VERSION "j1939-2025-03-v2.4-light"

NS_ :

BS_:

BU_:

BO_ 2633675518 HVESP7HIST: 19 Vector__XXX
 SG_ Hvesp7StateOfHealth : 0|8@1+ (0.4,0) [0|100] "%" Vector__XXX
 SG_ Hvesp7TotalEnergyThroughput : 24|32@1+ (100,0) [0|421108121500] "Watt-hour" Vector__XXX
 SG_ Hvesp7TotalAccumulatedCharge : 56|32@1+ (100,0) [0|421108121500] "Ah" Vector__XXX
 SG_ Hvesp7TotalLifetimeEnergyInput : 88|32@1+ (1,0) [0|4211081215] "kWh" Vector__XXX
 SG_ Hvesp7TotalLifetimeEnergyOutput : 120|32@1+ (1,0) [0|4211081215] "kWh" Vector__XXX
 SG_ Hvsp7CnttrOpnUndrLdCnt : 8|16@1+ (1,0) [0|64255] "count" Vector__XXX

BO_ 2566567166 EVDCLIM1: 8 Vector__XXX
 SG_ HrdOrEvDChrgngVltgMxmm : 0|16@1+ (0.05,0) [0|3212.75] "V" Vector__XXX
 SG_ HrdOrEvDChrgngCrrntMxmm : 16|16@1+ (0.0625,0) [0|4015.9375] "A" Vector__XXX
 SG_ HrdOrEvDChrgngPwrMxmm : 32|16@1+ (0.05,0) [0|3212.75] "kW" Vector__XXX
 SG_ HrdOrEvRqstdEnrgTrnsfrTp : 48|4@1+ (1,0) [0|15] "" Vector__XXX

BO_ 2566567422 EVSEDCLIM1: 8 Vector__XXX
 SG_ EvseDcChargingVoltageMaximum : 0|16@1+ (0.05,0) [0|3212.75] "V" Vector__XXX
 SG_ EvseDcChargingCurrentMaximum : 16|16@1+ (0.0625,0) [0|4015.9375] "A" Vector__XXX
 SG_ EvseDcChargingPowerMaximum : 32|16@1+ (0.05,0) [0|3212.75] "kW" Vector__XXX
 SG_ EvsSpprtdEnrgTrnsfrTps : 48|4@1+ (1,0) [0|15] "" Vector__XXX

BO_ 2566567678 EVSEDCLIM2: 8 Vector__XXX
 SG_ EvseDcChargingVoltageMinimum : 0|16@1+ (0.05,0) [0|3212.75] "V" Vector__XXX
 SG_ EvseDcChargingCurrentMinimum : 16|16@1+ (0.0625,0) [0|4015.9375] "A" Vector__XXX
 SG_ EvsePeakCurrentRipple : 32|16@1+ (0.0625,0) [0|4015.9375] "A" Vector__XXX
 SG_ EvseCurrentRegulationTolerance : 48|16@1+ (0.0625,0) [0|4015.9375] "A" Vector__XXX

BO_ 2566567934 EVDCTGT: 8 Vector__XXX
 SG_ DcChargingTargetCrc : 0|8@1+ (1,0) [0|250] "count" Vector__XXX
 SG_ DcChargingTargetSequenceCounter : 8|4@1+ (1,0) [0|15] "" Vector__XXX
 SG_ DcTargetChargingVoltage : 16|16@1+ (0.05,0) [0|3212.75] "V" Vector__XXX
 SG_ DcTargetChargingCurrent : 32|16@1+ (0.0625,0) [0|4015.9375] "A" Vector__XXX

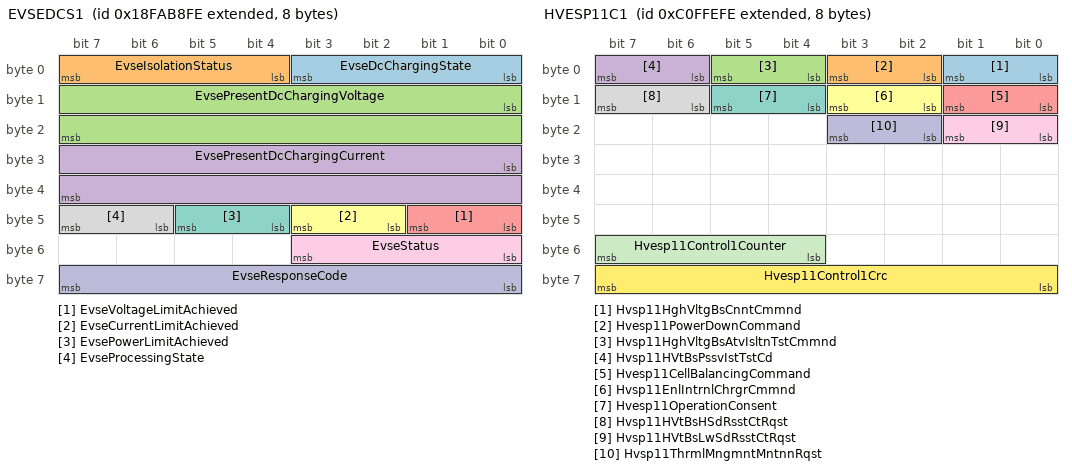
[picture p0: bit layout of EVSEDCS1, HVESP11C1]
BO_ 2566568190 EVSEDCS1: 8 Vector__XXX
 SG_ EvseDcChargingState : 0|4@1+ (1,0) [0|15] "" Vector__XXX
 SG_ EvseIsolationStatus : 4|4@1+ (1,0) [0|15] "" Vector__XXX
 SG_ EvsePresentDcChargingVoltage : 8|16@1+ (0.05,0) [0|3212.75] "V" Vector__XXX
 SG_ EvsePresentDcChargingCurrent : 24|16@1+ (0.05,-1600) [-1600|1612.75] "A" Vector__XXX
 SG_ EvseVoltageLimitAchieved : 40|2@1+ (1,0) [0|3] "" Vector__XXX
 SG_ EvseCurrentLimitAchieved : 42|2@1+ (1,0) [0|3] "" Vector__XXX
 SG_ EvsePowerLimitAchieved : 44|2@1+ (1,0) [0|3] "" Vector__XXX
 SG_ EvseProcessingState : 46|2@1+ (1,0) [0|3] "" Vector__XXX
 SG_ EvseStatus : 48|4@1+ (1,0) [0|15] "" Vector__XXX
 SG_ EvseResponseCode : 56|8@1+ (1,0) [0|250] "" Vector__XXX

BO_ 2566568446 EVSE1CC1: 8 Vector__XXX
 SG_ HrdOrEvDInltCnttr1Cmmnd : 0|2@1+ (1,0) [0|3] "" Vector__XXX

BO_ 2566568702 EVSE1CS1: 8 Vector__XXX
 SG_ HrdOrEvDCnttrInptVltg : 0|16@1+ (0.05,0) [0|3212.75] "V" Vector__XXX
 SG_ HybridOrEvDcChargingBusVoltage : 16|16@1+ (0.05,0) [0|3212.75] "V" Vector__XXX
 SG_ HrdOrEvDInltCnttr1Stt : 32|2@1+ (1,0) [0|3] "" Vector__XXX

BO_ 2566568958 DLCC3: 8 Vector__XXX
 SG_ TrnsmssnOlTmprtrHghLmpCmmnd : 0|2@1+ (1,0) [0|3] "" Vector__XXX
 SG_ TrnsmssnOlPrssrLwLmpCmmnd : 2|2@1+ (1,0) [0|3] "" Vector__XXX

BO_ 2566569214 DLCD3: 8 Vector__XXX
 SG_ TrnsmssnOlTmprtrHghLmpDt : 0|2@1+ (1,0) [0|3] "" Vector__XXX
 SG_ TrnsmssnOlPrssrLwLmpDt : 2|2@1+ (1,0) [0|3] "" Vector__XXX

BO_ 2566569470 MG1LD: 16 Vector__XXX
 SG_ MtrGnrtr1TtlEnrgCnsmd : 0|32@1+ (100,0) [0|421108121500] "Watt-hour" Vector__XXX
 SG_ MtrGnrtr1TtlEnrgGnrtd : 32|32@1+ (100,0) [0|421108121500] "Watt-hour" Vector__XXX
 SG_ MtrGnrtr1TtlChrgCnsmd : 64|32@1+ (100,0) [0|421108121500] "Ah" Vector__XXX
 SG_ MtrGnrtr1TtlChrgGnrtd : 96|32@1+ (100,0) [0|421108121500] "Ah" Vector__XXX

BO_ 2566569726 MG2LD: 16 Vector__XXX
 SG_ MtrGnrtr2TtlEnrgCnsmd : 0|32@1+ (100,0) [0|421108121500] "Watt-hour" Vector__XXX
 SG_ MtrGnrtr2TtlEnrgGnrtd : 32|32@1+ (100,0) [0|421108121500] "Watt-hour" Vector__XXX
 SG_ MtrGnrtr2TtlChrgCnsmd : 64|32@1+ (100,0) [0|421108121500] "Ah" Vector__XXX
 SG_ MtrGnrtr2TtlChrgGnrtd : 96|32@1+ (100,0) [0|421108121500] "Ah" Vector__XXX

BO_ 2566569982 MG3LD: 16 Vector__XXX
 SG_ MtrGnrtr3TtlEnrgCnsmd : 0|32@1+ (100,0) [0|421108121500] "Watt-hour" Vector__XXX
 SG_ MtrGnrtr3TtlEnrgGnrtd : 32|32@1+ (100,0) [0|421108121500] "Watt-hour" Vector__XXX
 SG_ MtrGnrtr3TtlChrgCnsmd : 64|32@1+ (100,0) [0|421108121500] "Ah" Vector__XXX
 SG_ MtrGnrtr3TtlChrgGnrtd : 96|32@1+ (100,0) [0|421108121500] "Ah" Vector__XXX

BO_ 2566570238 MG4LD: 16 Vector__XXX
 SG_ MtrGnrtr4TtlEnrgCnsmd : 0|32@1+ (100,0) [0|421108121500] "Watt-hour" Vector__XXX
 SG_ MtrGnrtr4TtlEnrgGnrtd : 32|32@1+ (100,0) [0|421108121500] "Watt-hour" Vector__XXX
 SG_ MtrGnrtr4TtlChrgCnsmd : 64|32@1+ (100,0) [0|421108121500] "Ah" Vector__XXX
 SG_ MtrGnrtr4TtlChrgGnrtd : 96|32@1+ (100,0) [0|421108121500] "Ah" Vector__XXX

BO_ 2566570494 MG5LD: 16 Vector__XXX
 SG_ MtrGnrtr5TtlEnrgCnsmd : 0|32@1+ (100,0) [0|421108121500] "Watt-hour" Vector__XXX
 SG_ MtrGnrtr5TtlEnrgGnrtd : 32|32@1+ (100,0) [0|421108121500] "Watt-hour" Vector__XXX
 SG_ MtrGnrtr5TtlChrgCnsmd : 64|32@1+ (100,0) [0|421108121500] "Ah" Vector__XXX
 SG_ MtrGnrtr5TtlChrgGnrtd : 96|32@1+ (100,0) [0|421108121500] "Ah" Vector__XXX

BO_ 2566570750 MG6LD: 16 Vector__XXX
 SG_ MtrGnrtr6TtlEnrgCnsmd : 0|32@1+ (100,0) [0|421108121500] "Watt-hour" Vector__XXX
 SG_ MtrGnrtr6TtlEnrgGnrtd : 32|32@1+ (100,0) [0|421108121500] "Watt-hour" Vector__XXX
 SG_ MtrGnrtr6TtlChrgCnsmd : 64|32@1+ (100,0) [0|421108121500] "Ah" Vector__XXX
 SG_ MtrGnrtr6TtlChrgGnrtd : 96|32@1+ (100,0) [0|421108121500] "Ah" Vector__XXX

BO_ 2566571006 AIR3: 8 Vector__XXX
 SG_ AirDryerCartridgeLifeRemaining : 0|8@1+ (0.4,0) [0|100] "%" Vector__XXX
 SG_ AirSuspensionSupplyPressure2 : 8|8@1+ (8,0) [0|2000] "kPa" Vector__XXX

BO_ 2566571262 EVSEACSV: 8 Vector__XXX
 SG_ EvseNominalRmsVoltageLineToLine : 16|16@1+ (0.05,0) [0|3212.75] "V" Vector__XXX
 SG_ EvseNominalSupplyFrequency : 32|8@1+ (1,0) [0|250] "" Vector__XXX
 SG_ EvsNmnlRmsVltgLnTNtrl : 0|16@1+ (0.05,0) [0|3212.75] "V" Vector__XXX

BO_ 2566571518 EVSEAC3PL: 8 Vector__XXX
 SG_ HvessChargerRmsCurrentL1 : 0|16@1+ (0.0625,0) [0|4015.9375] "A" Vector__XXX
 SG_ HvessChargerRmsCurrentL2 : 16|16@1+ (0.0625,0) [0|4015.9375] "A" Vector__XXX
 SG_ HvessChargerRmsCurrentL3 : 32|16@1+ (0.0625,0) [0|4015.9375] "A" Vector__XXX
 SG_ HvessChargerNeutralRmsCurrent : 48|16@1+ (0.0625,0) [0|4015.9375] "A" Vector__XXX

BO_ 2499462910 ERC3: 8 Vector__XXX
 SG_ RtrdrRdSpdDlrtSwth : 0|2@1+ (1,0) [0|3] "" Vector__XXX
 SG_ RtrdrRdSpdAlrtSwth : 2|2@1+ (1,0) [0|3] "" Vector__XXX

BO_ 2566572286 ETC14: 8 Vector__XXX
 SG_ TransmissionClutch1Temperature : 0|16@1+ (0.03125,-273) [-273|1734.96875] "degC" Vector__XXX
 SG_ TrnsmssnClth1OvrhtIndtr : 16|2@1+ (1,0) [0|3] "" Vector__XXX
 SG_ TransmissionLaunchCapability : 18|3@1+ (1,0) [0|7] "" Vector__XXX
 SG_ TransmissionGearShiftCapability : 21|3@1+ (1,0) [0|7] "" Vector__XXX
 SG_ TrnsmssnDmgThrshldStts : 24|3@1+ (1,0) [0|7] "" Vector__XXX

BO_ 2499464702 A1SCREGP2: 8 Vector__XXX
 SG_ Aftrtrtmnt1SrOtltAsltPrssr : 0|16@1+ (0.1,0) [0|6425.5] "kPa" Vector__XXX
 SG_ Aftrtrtmnt1SrOtltPrssr : 16|16@1+ (0.1,0) [0|6425.5] "kPa" Vector__XXX

BO_ 2566573822 PTO2: 8 Vector__XXX
 SG_ TransmissionPtoGearboxStatus : 16|4@1+ (1,0) [0|15] "" Vector__XXX
 SG_ TrnsmssnPtGrxOtptShftSpd : 0|16@1+ (0.125,0) [0|8031.875] "rpm" Vector__XXX

BO_ 2364690686 EATC1: 8 Vector__XXX
 SG_ AxlrTrnsmssnOtptSpd : 0|16@1+ (0.125,0) [0|8031.875] "rpm" Vector__XXX

BO_ 2566563326 DFM3: 8 Vector__XXX
 SG_ BddDFMdEsttdIsttsFSvsRt : 0|16@1+ (0.05,0) [0|3212.75] "l/h" Vector__XXX
 SG_ BlnddDlFlMdOprtngStts : 16|4@1+ (1,0) [0|15] "" Vector__XXX
 SG_ BlendedDualFuelModeStatusReason : 24|8@1+ (1,0) [0|250] "" Vector__XXX

BO_ 2566563582 DFM2: 8 Vector__XXX
 SG_ BlnddDlFlMdTtlDslFlDmnd : 32|32@1+ (0.5,0) [0|2105540607.5] "l" Vector__XXX
 SG_ BlnddDlFlMdTtlDslFlDspldBGssFl : 0|32@1+ (0.5,0) [0|2105540607.5] "l" Vector__XXX

BO_ 2566563838 DFM1: 8 Vector__XXX
 SG_ BlnddDlFlMdTtlDslFlUsd : 0|32@1+ (0.5,0) [0|2105540607.5] "l" Vector__XXX
 SG_ BlnddDlFlMdTtlDslFlPrntDspld : 32|8@1+ (0.5,0) [0|125] "%" Vector__XXX
 SG_ BlnddDlFlMdPrntTmAtv : 40|8@1+ (0.4,0) [0|100] "%" Vector__XXX
 SG_ BlnddDlFlMdDslFlPrntDspld : 48|8@1+ (0.4,0) [0|100] "%" Vector__XXX
 SG_ BddDFMdEsttdIsttsDsSvsRtPt : 56|8@1+ (0.4,0) [0|100] "%" Vector__XXX

BO_ 2566564094 T1HIST: 12 Vector__XXX
 SG_ Trnsmssn1TtlOtptShftRvltns : 32|32@1+ (1000,0) [0|4211081215000] "r" Vector__XXX
 SG_ Trnsmssn1OprtnTmSnRld : 64|32@1+ (1,0) [0|4211081215] "s" Vector__XXX
 SG_ Trnsmssn1TtlHrsOfOprtn : 0|32@1+ (1,0) [0|4211081215] "s" Vector__XXX

BO_ 2566564350 TSTI: 8 Vector__XXX
 SG_ Trnsmssn1InptShftPkTwst : 0|8@1+ (0.1,-12.5) [-12.5|12.5] "deg" Vector__XXX
 SG_ Trnsmssn1OtptShftPkTwst : 8|8@1+ (0.1,-12.5) [-12.5|12.5] "deg" Vector__XXX
 SG_ Trnsmssn1IntrmdtShftPkTwst : 16|8@1+ (0.1,-12.5) [-12.5|12.5] "deg" Vector__XXX

BO_ 2566564606 EATC2: 8 Vector__XXX
 SG_ AxlrTrnsmssnSltdGr : 0|8@1+ (1,-125) [-125|125] "gear value" Vector__XXX
 SG_ AxlrTrnsmssnCrrntGr : 8|8@1+ (1,-125) [-125|125] "gear value" Vector__XXX

BO_ 2349858558 HVESP11C1: 8 Vector__XXX
 SG_ Hvsp11HghVltgBsCnntCmmnd : 0|2@1+ (1,0) [0|3] "" Vector__XXX
 SG_ Hvesp11PowerDownCommand : 2|2@1+ (1,0) [0|3] "" Vector__XXX
 SG_ Hvsp11HghVltgBsAtvIsltnTstCmmnd : 4|2@1+ (1,0) [0|3] "" Vector__XXX
 SG_ Hvsp11HVtBsPssvIstTstCd : 6|2@1+ (1,0) [0|3] "" Vector__XXX
 SG_ Hvesp11CellBalancingCommand : 8|2@1+ (1,0) [0|3] "" Vector__XXX
 SG_ Hvsp11EnlIntrnlChrgrCmmnd : 10|2@1+ (1,0) [0|3] "" Vector__XXX
 SG_ Hvesp11OperationConsent : 12|2@1+ (1,0) [0|3] "" Vector__XXX
 SG_ Hvsp11HVtBsHSdRsstCtRqst : 14|2@1+ (1,0) [0|3] "" Vector__XXX
 SG_ Hvsp11HVtBsLwSdRsstCtRqst : 16|2@1+ (1,0) [0|3] "" Vector__XXX
 SG_ Hvsp11ThrmlMngmntMntnnRqst : 18|2@1+ (1,0) [0|3] "" Vector__XXX
 SG_ Hvesp11Control1Counter : 52|4@1+ (1,0) [0|15] "" Vector__XXX
 SG_ Hvesp11Control1Crc : 56|8@1+ (1,0) [0|250] "count" Vector__XXX

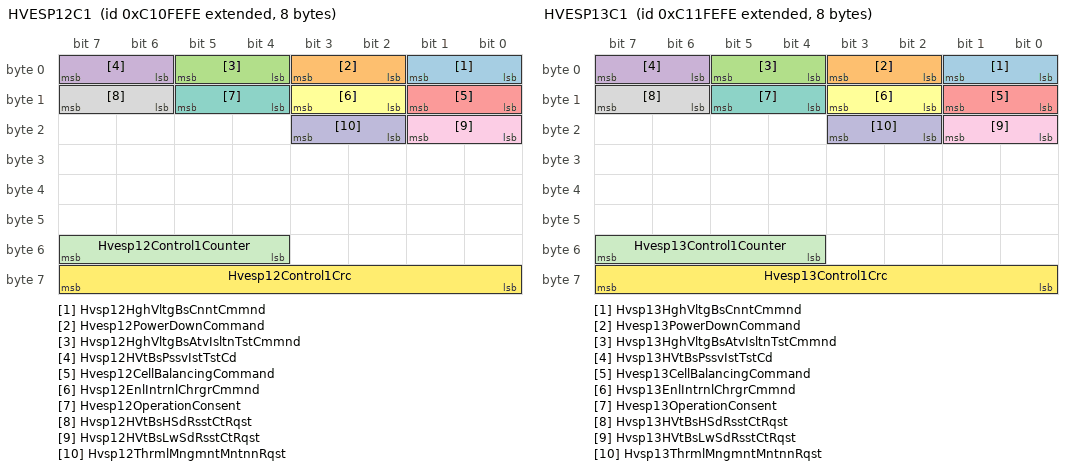
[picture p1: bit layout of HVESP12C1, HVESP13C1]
BO_ 2349924094 HVESP12C1: 8 Vector__XXX
 SG_ Hvsp12HghVltgBsCnntCmmnd : 0|2@1+ (1,0) [0|3] "" Vector__XXX
 SG_ Hvesp12PowerDownCommand : 2|2@1+ (1,0) [0|3] "" Vector__XXX
 SG_ Hvsp12HghVltgBsAtvIsltnTstCmmnd : 4|2@1+ (1,0) [0|3] "" Vector__XXX
 SG_ Hvsp12HVtBsPssvIstTstCd : 6|2@1+ (1,0) [0|3] "" Vector__XXX
 SG_ Hvesp12CellBalancingCommand : 8|2@1+ (1,0) [0|3] "" Vector__XXX
 SG_ Hvsp12EnlIntrnlChrgrCmmnd : 10|2@1+ (1,0) [0|3] "" Vector__XXX
 SG_ Hvesp12OperationConsent : 12|2@1+ (1,0) [0|3] "" Vector__XXX
 SG_ Hvsp12HVtBsHSdRsstCtRqst : 14|2@1+ (1,0) [0|3] "" Vector__XXX
 SG_ Hvsp12HVtBsLwSdRsstCtRqst : 16|2@1+ (1,0) [0|3] "" Vector__XXX
 SG_ Hvsp12ThrmlMngmntMntnnRqst : 18|2@1+ (1,0) [0|3] "" Vector__XXX
 SG_ Hvesp12Control1Counter : 52|4@1+ (1,0) [0|15] "" Vector__XXX
 SG_ Hvesp12Control1Crc : 56|8@1+ (1,0) [0|250] "count" Vector__XXX

BO_ 2349989630 HVESP13C1: 8 Vector__XXX
 SG_ Hvsp13HghVltgBsCnntCmmnd : 0|2@1+ (1,0) [0|3] "" Vector__XXX
 SG_ Hvesp13PowerDownCommand : 2|2@1+ (1,0) [0|3] "" Vector__XXX
 SG_ Hvsp13HghVltgBsAtvIsltnTstCmmnd : 4|2@1+ (1,0) [0|3] "" Vector__XXX
 SG_ Hvsp13HVtBsPssvIstTstCd : 6|2@1+ (1,0) [0|3] "" Vector__XXX
 SG_ Hvesp13CellBalancingCommand : 8|2@1+ (1,0) [0|3] "" Vector__XXX
 SG_ Hvsp13EnlIntrnlChrgrCmmnd : 10|2@1+ (1,0) [0|3] "" Vector__XXX
 SG_ Hvesp13OperationConsent : 12|2@1+ (1,0) [0|3] "" Vector__XXX
 SG_ Hvsp13HVtBsHSdRsstCtRqst : 14|2@1+ (1,0) [0|3] "" Vector__XXX
 SG_ Hvsp13HVtBsLwSdRsstCtRqst : 16|2@1+ (1,0) [0|3] "" Vector__XXX
 SG_ Hvsp13ThrmlMngmntMntnnRqst : 18|2@1+ (1,0) [0|3] "" Vector__XXX
 SG_ Hvesp13Control1Counter : 52|4@1+ (1,0) [0|15] "" Vector__XXX
 SG_ Hvesp13Control1Crc : 56|8@1+ (1,0) [0|250] "count" Vector__XXX

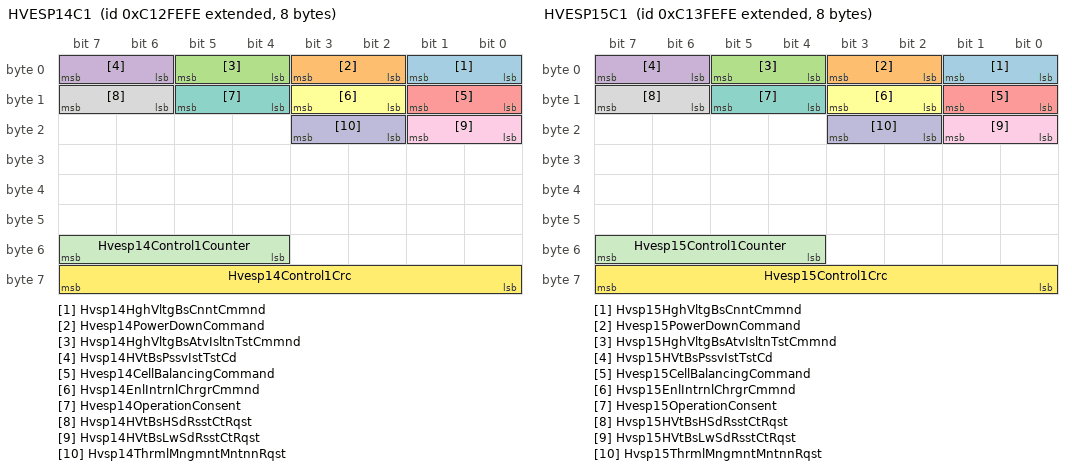
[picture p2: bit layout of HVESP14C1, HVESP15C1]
BO_ 2350055166 HVESP14C1: 8 Vector__XXX
 SG_ Hvsp14HghVltgBsCnntCmmnd : 0|2@1+ (1,0) [0|3] "" Vector__XXX
 SG_ Hvesp14PowerDownCommand : 2|2@1+ (1,0) [0|3] "" Vector__XXX
 SG_ Hvsp14HghVltgBsAtvIsltnTstCmmnd : 4|2@1+ (1,0) [0|3] "" Vector__XXX
 SG_ Hvsp14HVtBsPssvIstTstCd : 6|2@1+ (1,0) [0|3] "" Vector__XXX
 SG_ Hvesp14CellBalancingCommand : 8|2@1+ (1,0) [0|3] "" Vector__XXX
 SG_ Hvsp14EnlIntrnlChrgrCmmnd : 10|2@1+ (1,0) [0|3] "" Vector__XXX
 SG_ Hvesp14OperationConsent : 12|2@1+ (1,0) [0|3] "" Vector__XXX
 SG_ Hvsp14HVtBsHSdRsstCtRqst : 14|2@1+ (1,0) [0|3] "" Vector__XXX
 SG_ Hvsp14HVtBsLwSdRsstCtRqst : 16|2@1+ (1,0) [0|3] "" Vector__XXX
 SG_ Hvsp14ThrmlMngmntMntnnRqst : 18|2@1+ (1,0) [0|3] "" Vector__XXX
 SG_ Hvesp14Control1Counter : 52|4@1+ (1,0) [0|15] "" Vector__XXX
 SG_ Hvesp14Control1Crc : 56|8@1+ (1,0) [0|250] "count" Vector__XXX

BO_ 2350120702 HVESP15C1: 8 Vector__XXX
 SG_ Hvsp15HghVltgBsCnntCmmnd : 0|2@1+ (1,0) [0|3] "" Vector__XXX
 SG_ Hvesp15PowerDownCommand : 2|2@1+ (1,0) [0|3] "" Vector__XXX
 SG_ Hvsp15HghVltgBsAtvIsltnTstCmmnd : 4|2@1+ (1,0) [0|3] "" Vector__XXX
 SG_ Hvsp15HVtBsPssvIstTstCd : 6|2@1+ (1,0) [0|3] "" Vector__XXX
 SG_ Hvesp15CellBalancingCommand : 8|2@1+ (1,0) [0|3] "" Vector__XXX
 SG_ Hvsp15EnlIntrnlChrgrCmmnd : 10|2@1+ (1,0) [0|3] "" Vector__XXX
 SG_ Hvesp15OperationConsent : 12|2@1+ (1,0) [0|3] "" Vector__XXX
 SG_ Hvsp15HVtBsHSdRsstCtRqst : 14|2@1+ (1,0) [0|3] "" Vector__XXX
 SG_ Hvsp15HVtBsLwSdRsstCtRqst : 16|2@1+ (1,0) [0|3] "" Vector__XXX
 SG_ Hvsp15ThrmlMngmntMntnnRqst : 18|2@1+ (1,0) [0|3] "" Vector__XXX
 SG_ Hvesp15Control1Counter : 52|4@1+ (1,0) [0|15] "" Vector__XXX
 SG_ Hvesp15Control1Crc : 56|8@1+ (1,0) [0|250] "count" Vector__XXX

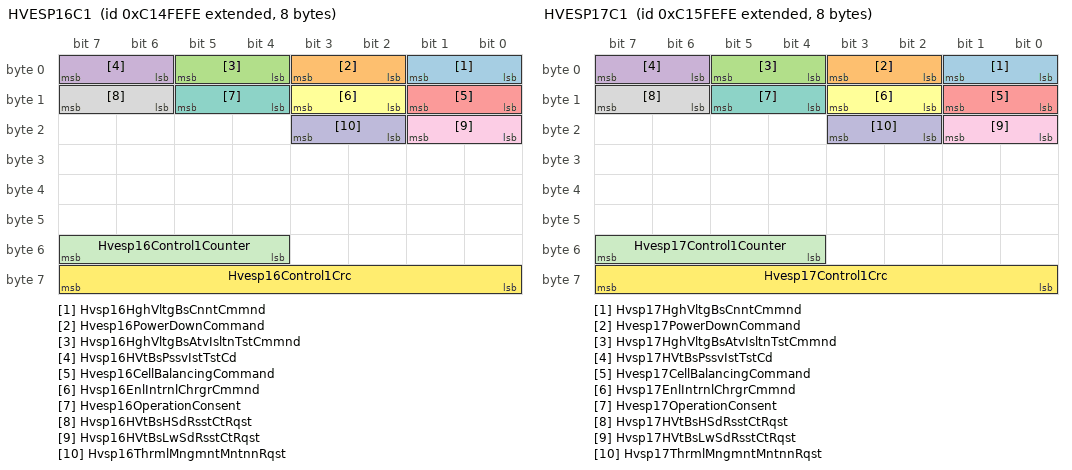
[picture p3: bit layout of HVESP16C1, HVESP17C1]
BO_ 2350186238 HVESP16C1: 8 Vector__XXX
 SG_ Hvsp16HghVltgBsCnntCmmnd : 0|2@1+ (1,0) [0|3] "" Vector__XXX
 SG_ Hvesp16PowerDownCommand : 2|2@1+ (1,0) [0|3] "" Vector__XXX
 SG_ Hvsp16HghVltgBsAtvIsltnTstCmmnd : 4|2@1+ (1,0) [0|3] "" Vector__XXX
 SG_ Hvsp16HVtBsPssvIstTstCd : 6|2@1+ (1,0) [0|3] "" Vector__XXX
 SG_ Hvesp16CellBalancingCommand : 8|2@1+ (1,0) [0|3] "" Vector__XXX
 SG_ Hvsp16EnlIntrnlChrgrCmmnd : 10|2@1+ (1,0) [0|3] "" Vector__XXX
 SG_ Hvesp16OperationConsent : 12|2@1+ (1,0) [0|3] "" Vector__XXX
 SG_ Hvsp16HVtBsHSdRsstCtRqst : 14|2@1+ (1,0) [0|3] "" Vector__XXX
 SG_ Hvsp16HVtBsLwSdRsstCtRqst : 16|2@1+ (1,0) [0|3] "" Vector__XXX
 SG_ Hvsp16ThrmlMngmntMntnnRqst : 18|2@1+ (1,0) [0|3] "" Vector__XXX
 SG_ Hvesp16Control1Counter : 52|4@1+ (1,0) [0|15] "" Vector__XXX
 SG_ Hvesp16Control1Crc : 56|8@1+ (1,0) [0|250] "count" Vector__XXX

BO_ 2350251774 HVESP17C1: 8 Vector__XXX
 SG_ Hvsp17HghVltgBsCnntCmmnd : 0|2@1+ (1,0) [0|3] "" Vector__XXX
 SG_ Hvesp17PowerDownCommand : 2|2@1+ (1,0) [0|3] "" Vector__XXX
 SG_ Hvsp17HghVltgBsAtvIsltnTstCmmnd : 4|2@1+ (1,0) [0|3] "" Vector__XXX
 SG_ Hvsp17HVtBsPssvIstTstCd : 6|2@1+ (1,0) [0|3] "" Vector__XXX
 SG_ Hvesp17CellBalancingCommand : 8|2@1+ (1,0) [0|3] "" Vector__XXX
 SG_ Hvsp17EnlIntrnlChrgrCmmnd : 10|2@1+ (1,0) [0|3] "" Vector__XXX
 SG_ Hvesp17OperationConsent : 12|2@1+ (1,0) [0|3] "" Vector__XXX
 SG_ Hvsp17HVtBsHSdRsstCtRqst : 14|2@1+ (1,0) [0|3] "" Vector__XXX
 SG_ Hvsp17HVtBsLwSdRsstCtRqst : 16|2@1+ (1,0) [0|3] "" Vector__XXX
 SG_ Hvsp17ThrmlMngmntMntnnRqst : 18|2@1+ (1,0) [0|3] "" Vector__XXX
 SG_ Hvesp17Control1Counter : 52|4@1+ (1,0) [0|15] "" Vector__XXX
 SG_ Hvesp17Control1Crc : 56|8@1+ (1,0) [0|250] "count" Vector__XXX

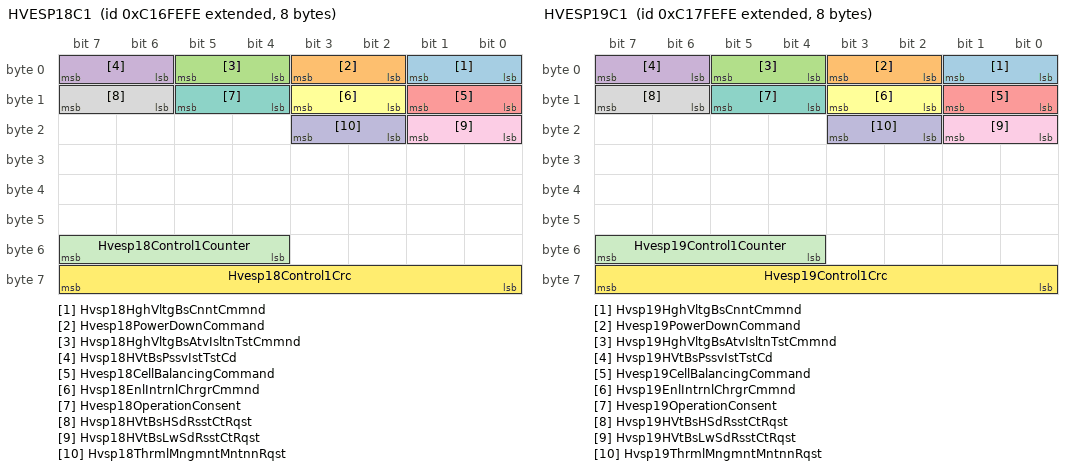
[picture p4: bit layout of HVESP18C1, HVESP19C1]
BO_ 2350317310 HVESP18C1: 8 Vector__XXX
 SG_ Hvsp18HghVltgBsCnntCmmnd : 0|2@1+ (1,0) [0|3] "" Vector__XXX
 SG_ Hvesp18PowerDownCommand : 2|2@1+ (1,0) [0|3] "" Vector__XXX
 SG_ Hvsp18HghVltgBsAtvIsltnTstCmmnd : 4|2@1+ (1,0) [0|3] "" Vector__XXX
 SG_ Hvsp18HVtBsPssvIstTstCd : 6|2@1+ (1,0) [0|3] "" Vector__XXX
 SG_ Hvesp18CellBalancingCommand : 8|2@1+ (1,0) [0|3] "" Vector__XXX
 SG_ Hvsp18EnlIntrnlChrgrCmmnd : 10|2@1+ (1,0) [0|3] "" Vector__XXX
 SG_ Hvesp18OperationConsent : 12|2@1+ (1,0) [0|3] "" Vector__XXX
 SG_ Hvsp18HVtBsHSdRsstCtRqst : 14|2@1+ (1,0) [0|3] "" Vector__XXX
 SG_ Hvsp18HVtBsLwSdRsstCtRqst : 16|2@1+ (1,0) [0|3] "" Vector__XXX
 SG_ Hvsp18ThrmlMngmntMntnnRqst : 18|2@1+ (1,0) [0|3] "" Vector__XXX
 SG_ Hvesp18Control1Counter : 52|4@1+ (1,0) [0|15] "" Vector__XXX
 SG_ Hvesp18Control1Crc : 56|8@1+ (1,0) [0|250] "count" Vector__XXX

BO_ 2350382846 HVESP19C1: 8 Vector__XXX
 SG_ Hvsp19HghVltgBsCnntCmmnd : 0|2@1+ (1,0) [0|3] "" Vector__XXX
 SG_ Hvesp19PowerDownCommand : 2|2@1+ (1,0) [0|3] "" Vector__XXX
 SG_ Hvsp19HghVltgBsAtvIsltnTstCmmnd : 4|2@1+ (1,0) [0|3] "" Vector__XXX
 SG_ Hvsp19HVtBsPssvIstTstCd : 6|2@1+ (1,0) [0|3] "" Vector__XXX
 SG_ Hvesp19CellBalancingCommand : 8|2@1+ (1,0) [0|3] "" Vector__XXX
 SG_ Hvsp19EnlIntrnlChrgrCmmnd : 10|2@1+ (1,0) [0|3] "" Vector__XXX
 SG_ Hvesp19OperationConsent : 12|2@1+ (1,0) [0|3] "" Vector__XXX
 SG_ Hvsp19HVtBsHSdRsstCtRqst : 14|2@1+ (1,0) [0|3] "" Vector__XXX
 SG_ Hvsp19HVtBsLwSdRsstCtRqst : 16|2@1+ (1,0) [0|3] "" Vector__XXX
 SG_ Hvsp19ThrmlMngmntMntnnRqst : 18|2@1+ (1,0) [0|3] "" Vector__XXX
 SG_ Hvesp19Control1Counter : 52|4@1+ (1,0) [0|15] "" Vector__XXX
 SG_ Hvesp19Control1Crc : 56|8@1+ (1,0) [0|250] "count" Vector__XXX

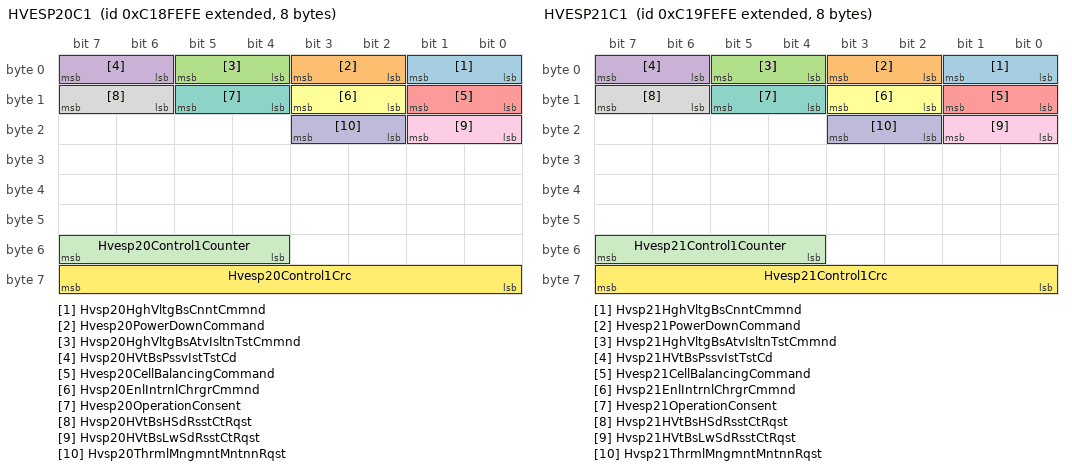
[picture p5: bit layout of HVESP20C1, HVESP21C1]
BO_ 2350448382 HVESP20C1: 8 Vector__XXX
 SG_ Hvsp20HghVltgBsCnntCmmnd : 0|2@1+ (1,0) [0|3] "" Vector__XXX
 SG_ Hvesp20PowerDownCommand : 2|2@1+ (1,0) [0|3] "" Vector__XXX
 SG_ Hvsp20HghVltgBsAtvIsltnTstCmmnd : 4|2@1+ (1,0) [0|3] "" Vector__XXX
 SG_ Hvsp20HVtBsPssvIstTstCd : 6|2@1+ (1,0) [0|3] "" Vector__XXX
 SG_ Hvesp20CellBalancingCommand : 8|2@1+ (1,0) [0|3] "" Vector__XXX
 SG_ Hvsp20EnlIntrnlChrgrCmmnd : 10|2@1+ (1,0) [0|3] "" Vector__XXX
 SG_ Hvesp20OperationConsent : 12|2@1+ (1,0) [0|3] "" Vector__XXX
 SG_ Hvsp20HVtBsHSdRsstCtRqst : 14|2@1+ (1,0) [0|3] "" Vector__XXX
 SG_ Hvsp20HVtBsLwSdRsstCtRqst : 16|2@1+ (1,0) [0|3] "" Vector__XXX
 SG_ Hvsp20ThrmlMngmntMntnnRqst : 18|2@1+ (1,0) [0|3] "" Vector__XXX
 SG_ Hvesp20Control1Counter : 52|4@1+ (1,0) [0|15] "" Vector__XXX
 SG_ Hvesp20Control1Crc : 56|8@1+ (1,0) [0|250] "count" Vector__XXX

BO_ 2350513918 HVESP21C1: 8 Vector__XXX
 SG_ Hvsp21HghVltgBsCnntCmmnd : 0|2@1+ (1,0) [0|3] "" Vector__XXX
 SG_ Hvesp21PowerDownCommand : 2|2@1+ (1,0) [0|3] "" Vector__XXX
 SG_ Hvsp21HghVltgBsAtvIsltnTstCmmnd : 4|2@1+ (1,0) [0|3] "" Vector__XXX
 SG_ Hvsp21HVtBsPssvIstTstCd : 6|2@1+ (1,0) [0|3] "" Vector__XXX
 SG_ Hvesp21CellBalancingCommand : 8|2@1+ (1,0) [0|3] "" Vector__XXX
 SG_ Hvsp21EnlIntrnlChrgrCmmnd : 10|2@1+ (1,0) [0|3] "" Vector__XXX
 SG_ Hvesp21OperationConsent : 12|2@1+ (1,0) [0|3] "" Vector__XXX
 SG_ Hvsp21HVtBsHSdRsstCtRqst : 14|2@1+ (1,0) [0|3] "" Vector__XXX
 SG_ Hvsp21HVtBsLwSdRsstCtRqst : 16|2@1+ (1,0) [0|3] "" Vector__XXX
 SG_ Hvsp21ThrmlMngmntMntnnRqst : 18|2@1+ (1,0) [0|3] "" Vector__XXX
 SG_ Hvesp21Control1Counter : 52|4@1+ (1,0) [0|15] "" Vector__XXX
 SG_ Hvesp21Control1Crc : 56|8@1+ (1,0) [0|250] "count" Vector__XXX

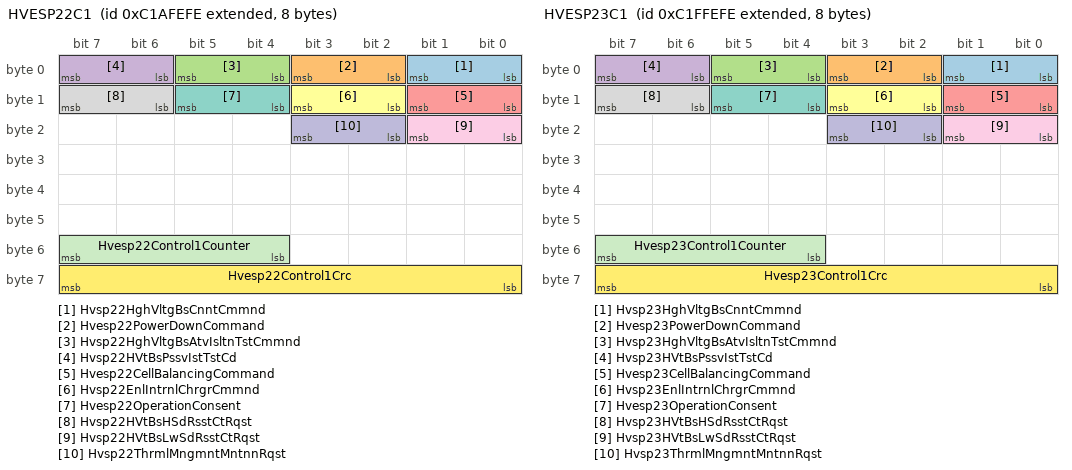
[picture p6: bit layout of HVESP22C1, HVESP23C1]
BO_ 2350579454 HVESP22C1: 8 Vector__XXX
 SG_ Hvsp22HghVltgBsCnntCmmnd : 0|2@1+ (1,0) [0|3] "" Vector__XXX
 SG_ Hvesp22PowerDownCommand : 2|2@1+ (1,0) [0|3] "" Vector__XXX
 SG_ Hvsp22HghVltgBsAtvIsltnTstCmmnd : 4|2@1+ (1,0) [0|3] "" Vector__XXX
 SG_ Hvsp22HVtBsPssvIstTstCd : 6|2@1+ (1,0) [0|3] "" Vector__XXX
 SG_ Hvesp22CellBalancingCommand : 8|2@1+ (1,0) [0|3] "" Vector__XXX
 SG_ Hvsp22EnlIntrnlChrgrCmmnd : 10|2@1+ (1,0) [0|3] "" Vector__XXX
 SG_ Hvesp22OperationConsent : 12|2@1+ (1,0) [0|3] "" Vector__XXX
 SG_ Hvsp22HVtBsHSdRsstCtRqst : 14|2@1+ (1,0) [0|3] "" Vector__XXX
 SG_ Hvsp22HVtBsLwSdRsstCtRqst : 16|2@1+ (1,0) [0|3] "" Vector__XXX
 SG_ Hvsp22ThrmlMngmntMntnnRqst : 18|2@1+ (1,0) [0|3] "" Vector__XXX
 SG_ Hvesp22Control1Counter : 52|4@1+ (1,0) [0|15] "" Vector__XXX
 SG_ Hvesp22Control1Crc : 56|8@1+ (1,0) [0|250] "count" Vector__XXX

BO_ 2350907134 HVESP23C1: 8 Vector__XXX
 SG_ Hvsp23HghVltgBsCnntCmmnd : 0|2@1+ (1,0) [0|3] "" Vector__XXX
 SG_ Hvesp23PowerDownCommand : 2|2@1+ (1,0) [0|3] "" Vector__XXX
 SG_ Hvsp23HghVltgBsAtvIsltnTstCmmnd : 4|2@1+ (1,0) [0|3] "" Vector__XXX
 SG_ Hvsp23HVtBsPssvIstTstCd : 6|2@1+ (1,0) [0|3] "" Vector__XXX
 SG_ Hvesp23CellBalancingCommand : 8|2@1+ (1,0) [0|3] "" Vector__XXX
 SG_ Hvsp23EnlIntrnlChrgrCmmnd : 10|2@1+ (1,0) [0|3] "" Vector__XXX
 SG_ Hvesp23OperationConsent : 12|2@1+ (1,0) [0|3] "" Vector__XXX
 SG_ Hvsp23HVtBsHSdRsstCtRqst : 14|2@1+ (1,0) [0|3] "" Vector__XXX
 SG_ Hvsp23HVtBsLwSdRsstCtRqst : 16|2@1+ (1,0) [0|3] "" Vector__XXX
 SG_ Hvsp23ThrmlMngmntMntnnRqst : 18|2@1+ (1,0) [0|3] "" Vector__XXX
 SG_ Hvesp23Control1Counter : 52|4@1+ (1,0) [0|15] "" Vector__XXX
 SG_ Hvesp23Control1Crc : 56|8@1+ (1,0) [0|250] "count" Vector__XXX

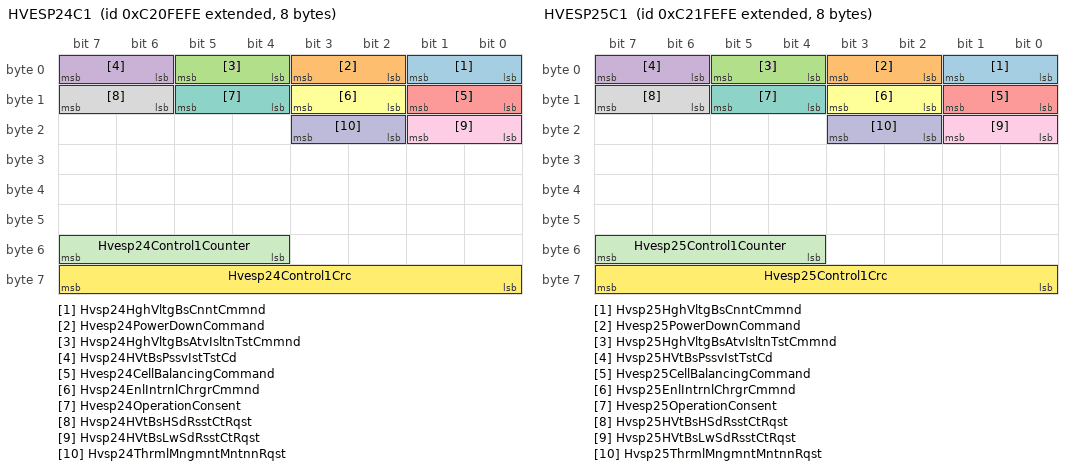
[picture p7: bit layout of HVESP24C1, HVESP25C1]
BO_ 2350972670 HVESP24C1: 8 Vector__XXX
 SG_ Hvsp24HghVltgBsCnntCmmnd : 0|2@1+ (1,0) [0|3] "" Vector__XXX
 SG_ Hvesp24PowerDownCommand : 2|2@1+ (1,0) [0|3] "" Vector__XXX
 SG_ Hvsp24HghVltgBsAtvIsltnTstCmmnd : 4|2@1+ (1,0) [0|3] "" Vector__XXX
 SG_ Hvsp24HVtBsPssvIstTstCd : 6|2@1+ (1,0) [0|3] "" Vector__XXX
 SG_ Hvesp24CellBalancingCommand : 8|2@1+ (1,0) [0|3] "" Vector__XXX
 SG_ Hvsp24EnlIntrnlChrgrCmmnd : 10|2@1+ (1,0) [0|3] "" Vector__XXX
 SG_ Hvesp24OperationConsent : 12|2@1+ (1,0) [0|3] "" Vector__XXX
 SG_ Hvsp24HVtBsHSdRsstCtRqst : 14|2@1+ (1,0) [0|3] "" Vector__XXX
 SG_ Hvsp24HVtBsLwSdRsstCtRqst : 16|2@1+ (1,0) [0|3] "" Vector__XXX
 SG_ Hvsp24ThrmlMngmntMntnnRqst : 18|2@1+ (1,0) [0|3] "" Vector__XXX
 SG_ Hvesp24Control1Counter : 52|4@1+ (1,0) [0|15] "" Vector__XXX
 SG_ Hvesp24Control1Crc : 56|8@1+ (1,0) [0|250] "count" Vector__XXX

BO_ 2351038206 HVESP25C1: 8 Vector__XXX
 SG_ Hvsp25HghVltgBsCnntCmmnd : 0|2@1+ (1,0) [0|3] "" Vector__XXX
 SG_ Hvesp25PowerDownCommand : 2|2@1+ (1,0) [0|3] "" Vector__XXX
 SG_ Hvsp25HghVltgBsAtvIsltnTstCmmnd : 4|2@1+ (1,0) [0|3] "" Vector__XXX
 SG_ Hvsp25HVtBsPssvIstTstCd : 6|2@1+ (1,0) [0|3] "" Vector__XXX
 SG_ Hvesp25CellBalancingCommand : 8|2@1+ (1,0) [0|3] "" Vector__XXX
 SG_ Hvsp25EnlIntrnlChrgrCmmnd : 10|2@1+ (1,0) [0|3] "" Vector__XXX
 SG_ Hvesp25OperationConsent : 12|2@1+ (1,0) [0|3] "" Vector__XXX
 SG_ Hvsp25HVtBsHSdRsstCtRqst : 14|2@1+ (1,0) [0|3] "" Vector__XXX
 SG_ Hvsp25HVtBsLwSdRsstCtRqst : 16|2@1+ (1,0) [0|3] "" Vector__XXX
 SG_ Hvsp25ThrmlMngmntMntnnRqst : 18|2@1+ (1,0) [0|3] "" Vector__XXX
 SG_ Hvesp25Control1Counter : 52|4@1+ (1,0) [0|15] "" Vector__XXX
 SG_ Hvesp25Control1Crc : 56|8@1+ (1,0) [0|250] "count" Vector__XXX

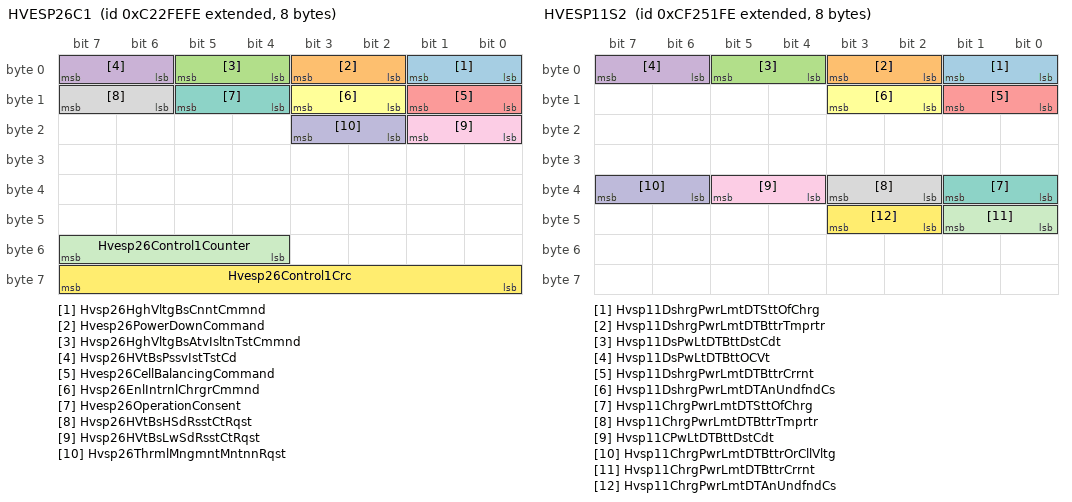
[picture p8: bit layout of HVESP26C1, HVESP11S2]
BO_ 2351103742 HVESP26C1: 8 Vector__XXX
 SG_ Hvsp26HghVltgBsCnntCmmnd : 0|2@1+ (1,0) [0|3] "" Vector__XXX
 SG_ Hvesp26PowerDownCommand : 2|2@1+ (1,0) [0|3] "" Vector__XXX
 SG_ Hvsp26HghVltgBsAtvIsltnTstCmmnd : 4|2@1+ (1,0) [0|3] "" Vector__XXX
 SG_ Hvsp26HVtBsPssvIstTstCd : 6|2@1+ (1,0) [0|3] "" Vector__XXX
 SG_ Hvesp26CellBalancingCommand : 8|2@1+ (1,0) [0|3] "" Vector__XXX
 SG_ Hvsp26EnlIntrnlChrgrCmmnd : 10|2@1+ (1,0) [0|3] "" Vector__XXX
 SG_ Hvesp26OperationConsent : 12|2@1+ (1,0) [0|3] "" Vector__XXX
 SG_ Hvsp26HVtBsHSdRsstCtRqst : 14|2@1+ (1,0) [0|3] "" Vector__XXX
 SG_ Hvsp26HVtBsLwSdRsstCtRqst : 16|2@1+ (1,0) [0|3] "" Vector__XXX
 SG_ Hvsp26ThrmlMngmntMntnnRqst : 18|2@1+ (1,0) [0|3] "" Vector__XXX
 SG_ Hvesp26Control1Counter : 52|4@1+ (1,0) [0|15] "" Vector__XXX
 SG_ Hvesp26Control1Crc : 56|8@1+ (1,0) [0|250] "count" Vector__XXX

BO_ 2555182846 EAECPC: 8 Vector__XXX
 SG_ EngnClntEltrPmpEnlCmmnd : 0|2@1+ (1,0) [0|3] "" Vector__XXX
 SG_ EngnClntEltrPmpPwrHld : 2|2@1+ (1,0) [0|3] "" Vector__XXX
 SG_ EngnClntEltrPmpDrvSr : 4|2@1+ (1,0) [0|3] "" Vector__XXX
 SG_ EngnClntEltrPmpSpdCmmnd : 8|16@1+ (0.5,0) [0|32127.5] "rpm" Vector__XXX
 SG_ EngnClntEltrPmpPrntSpd : 24|8@1+ (0.5,0) [0|125] "%" Vector__XXX

BO_ 2364567550 PC1IC1: 8 Vector__XXX
 SG_ PowerConverter1ControlCrc : 0|8@1+ (1,0) [0|250] "count" Vector__XXX
 SG_ PowerConverter1ControlCounter : 8|4@1+ (1,0) [0|15] "" Vector__XXX
 SG_ PwrCnvrtr1CntrlLmtsRqstOvrrdMd : 12|4@1+ (1,0) [0|15] "" Vector__XXX
 SG_ PwCvt1CtLtsRqstOvdMx : 16|12@1+ (0.0625,-125) [-125|125.9375] "%" Vector__XXX
 SG_ PwCvt1CtLtsRqstOvdM : 28|12@1+ (0.0625,-125) [-125|125.9375] "%" Vector__XXX
 SG_ PwrCnvrtr1CntrlStpntMdRqst : 43|5@1+ (1,0) [0|31] "" Vector__XXX
 SG_ PwrCnvrtr1CntrlStpntRqst : 48|16@1+ (0.00390625,-125) [-125|125.99609375] "%" Vector__XXX

BO_ 2364567806 PC2IC1: 8 Vector__XXX
 SG_ PowerConverter2ControlCrc : 0|8@1+ (1,0) [0|250] "count" Vector__XXX
 SG_ PowerConverter2ControlCounter : 8|4@1+ (1,0) [0|15] "" Vector__XXX
 SG_ PwrCnvrtr2CntrlLmtsRqstOvrrdMd : 12|4@1+ (1,0) [0|15] "" Vector__XXX
 SG_ PwCvt2CtLtsRqstOvdMx : 16|12@1+ (0.0625,-125) [-125|125.9375] "%" Vector__XXX
 SG_ PwCvt2CtLtsRqstOvdM : 28|12@1+ (0.0625,-125) [-125|125.9375] "%" Vector__XXX
 SG_ PwrCnvrtr2CntrlStpntMdRqst : 43|5@1+ (1,0) [0|31] "" Vector__XXX
 SG_ PwrCnvrtr2CntrlStpntRqst : 48|16@1+ (0.00390625,-125) [-125|125.99609375] "%" Vector__XXX

BO_ 2565894654 PC1IRLR1: 8 Vector__XXX
 SG_ PwrCnvrtr1RtLmtsRqst1Cr : 0|8@1+ (1,0) [0|250] "count" Vector__XXX
 SG_ PwrCnvrtr1RtLmtsRqst1Cntr : 8|4@1+ (1,0) [0|15] "" Vector__XXX
 SG_ PwCvt1RtLtsRqstAstFqRtLt : 12|12@1+ (0.25,0) [0|1003.75] "%/s" Vector__XXX
 SG_ PwCvt1RtLtsRqstAstCtRtLt : 24|12@1+ (2,0) [0|8030] "%/s" Vector__XXX

BO_ 2565894910 PC2IRLR1: 8 Vector__XXX
 SG_ PwrCnvrtr2RtLmtsRqst1Cr : 0|8@1+ (1,0) [0|250] "count" Vector__XXX
 SG_ PwrCnvrtr2RtLmtsRqst1Cntr : 8|4@1+ (1,0) [0|15] "" Vector__XXX
 SG_ PwCvt2RtLtsRqstAstFqRtLt : 12|12@1+ (0.25,0) [0|1003.75] "%/s" Vector__XXX
 SG_ PwCvt2RtLtsRqstAstCtRtLt : 24|12@1+ (2,0) [0|8030] "%/s" Vector__XXX

BO_ 2364568574 PC2IC2: 8 Vector__XXX
 SG_ PowerConverter2Control2Crc : 0|8@1+ (1,0) [0|250] "count" Vector__XXX
 SG_ PowerConverter2Control2Counter : 8|4@1+ (1,0) [0|15] "" Vector__XXX
 SG_ PwrCnvrtr2PdCntrlAppllMd : 12|4@1+ (1,0) [0|15] "" Vector__XXX
 SG_ PwCvt2PdCtNzdDtG : 16|8@1+ (0.03125,0) [0|7.8125] "%/(%/s)" Vector__XXX
 SG_ PwrCnvrtr2PdCntrlNrmlzdIntgrlGn : 24|16@1+ (0.015625,0) [0|1003.984375] "%/(%/s)" Vector__XXX
 SG_ PwCvt2PdCtNzdPptG : 40|12@1+ (0.0625,0) [0|250.9375] "%/%" Vector__XXX

BO_ 2364568830 PC1IC2: 8 Vector__XXX
 SG_ PowerConverter1Control2Crc : 0|8@1+ (1,0) [0|250] "count" Vector__XXX
 SG_ PowerConverter1Control2Counter : 8|4@1+ (1,0) [0|15] "" Vector__XXX
 SG_ PwrCnvrtr1PdCntrlAppllMd : 12|4@1+ (1,0) [0|15] "" Vector__XXX
 SG_ PwCvt1PdCtNzdDtG : 16|8@1+ (0.03125,0) [0|7.8125] "%/(%/s)" Vector__XXX
 SG_ PwrCnvrtr1PdCntrlNrmlzdIntgrlGn : 24|16@1+ (0.015625,0) [0|1003.984375] "%/(%/s)" Vector__XXX
 SG_ PwCvt1PdCtNzdPptG : 40|12@1+ (0.0625,0) [0|250.9375] "%/%" Vector__XXX

BO_ 2364569086 PC1IMF1: 8 Vector__XXX
 SG_ PowerConverter1ModeFeedback1Crc : 0|8@1+ (1,0) [0|250] "count" Vector__XXX
 SG_ PwrCnvrtr1MdFdk1Cntr : 8|4@1+ (1,0) [0|15] "" Vector__XXX
 SG_ PwrCnvrtr1CntrlLmtsOvrrdMd : 12|4@1+ (1,0) [0|15] "" Vector__XXX
 SG_ PwrCnvrtr1CntrlStpntMd : 16|5@1+ (1,0) [0|31] "" Vector__XXX
 SG_ PowerConverter1HvilStatus : 21|2@1+ (1,0) [0|3] "" Vector__XXX

BO_ 2565895934 PC1ILAP: 8 Vector__XXX
 SG_ PwrCnvrtr1LmtsAtvPwrCr : 0|8@1+ (1,0) [0|250] "count" Vector__XXX
 SG_ PwrCnvrtr1LmtsAtvPwrCntr : 8|4@1+ (1,0) [0|15] "" Vector__XXX
 SG_ PwrCnvrtr1LmtsAtvEltrlPwrMxmm : 12|12@1+ (0.0625,-125) [-125|125.9375] "%" Vector__XXX
 SG_ PwrCnvrtr1LmtsAtvEltrlPwrMnmm : 24|12@1+ (0.0625,-125) [-125|125.9375] "%" Vector__XXX
 SG_ PwCvt1LtsAtvDES1PwMx : 36|12@1+ (0.0625,-125) [-125|125.9375] "%" Vector__XXX
 SG_ PwCvt1LtsAtvDES1PwM : 48|12@1+ (0.0625,-125) [-125|125.9375] "%" Vector__XXX

BO_ 2565896190 PC1ILAM: 8 Vector__XXX
 SG_ PwrCnvrtr1LmtsAtvEltrlCr : 0|8@1+ (1,0) [0|250] "count" Vector__XXX
 SG_ PwrCnvrtr1LmtsAtvEltrlCntr : 8|4@1+ (1,0) [0|15] "" Vector__XXX
 SG_ PwrCnvrtr1LmtsAtvCrrntMxmm : 12|12@1+ (0.0625,-125) [-125|125.9375] "%" Vector__XXX
 SG_ PwrCnvrtr1LmtsAtvCrrntMnmm : 24|12@1+ (0.0625,-125) [-125|125.9375] "%" Vector__XXX
 SG_ PwrCnvrtr1LmtsAtvFrqnMxmm : 36|12@1+ (0.0625,-125) [-125|125.9375] "%" Vector__XXX
 SG_ PwrCnvrtr1LmtsAtvFrqnMnmm : 48|12@1+ (0.0625,-125) [-125|125.9375] "%" Vector__XXX

BO_ 2565896446 PC1ILADC: 8 Vector__XXX
 SG_ PwrCnvrtr1LmtsAtvDEnrgSr1Cr : 0|8@1+ (1,0) [0|250] "count" Vector__XXX
 SG_ PwrCnvrtr1LmtsAtvDEnrgSr1Cntr : 8|4@1+ (1,0) [0|15] "" Vector__XXX
 SG_ PwCvt1LtsAtvDES1VtMx : 12|12@1+ (0.0625,-125) [-125|125.9375] "%" Vector__XXX
 SG_ PwCvt1LtsAtvDES1VtM : 24|12@1+ (0.0625,-125) [-125|125.9375] "%" Vector__XXX
 SG_ PwCvt1LtsAtvDES1CtMx : 36|12@1+ (0.0625,-125) [-125|125.9375] "%" Vector__XXX
 SG_ PwCvt1LtsAtvDES1CtM : 48|12@1+ (0.0625,-125) [-125|125.9375] "%" Vector__XXX

BO_ 2565896702 PC1ILV: 8 Vector__XXX
 SG_ PwrCnvrtr1SwthdIgntnVltg : 0|16@1+ (0.05,0) [0|3212.75] "V" Vector__XXX
 SG_ PwrCnvrtr1UnswthdSlVltg : 16|16@1+ (0.05,0) [0|3212.75] "V" Vector__XXX

BO_ 2364570366 PC2IMF1: 8 Vector__XXX
 SG_ PowerConverter2ModeFeedback1Crc : 0|8@1+ (1,0) [0|250] "count" Vector__XXX
 SG_ PwrCnvrtr2MdFdk1Cntr : 8|4@1+ (1,0) [0|15] "" Vector__XXX
 SG_ PwrCnvrtr2CntrlLmtsOvrrdMd : 12|4@1+ (1,0) [0|15] "" Vector__XXX
 SG_ PwrCnvrtr2CntrlStpntMd : 16|5@1+ (1,0) [0|31] "" Vector__XXX
 SG_ PowerConverter2HvilStatus : 21|2@1+ (1,0) [0|3] "" Vector__XXX

BO_ 2565897214 PC2ILAP: 8 Vector__XXX
 SG_ PwrCnvrtr2LmtsAtvPwrCr : 0|8@1+ (1,0) [0|250] "count" Vector__XXX
 SG_ PwrCnvrtr2LmtsAtvPwrCntr : 8|4@1+ (1,0) [0|15] "" Vector__XXX
 SG_ PwrCnvrtr2LmtsAtvEltrlPwrMxmm : 12|12@1+ (0.0625,-125) [-125|125.9375] "%" Vector__XXX
 SG_ PwrCnvrtr2LmtsAtvEltrlPwrMnmm : 24|12@1+ (0.0625,-125) [-125|125.9375] "%" Vector__XXX
 SG_ PwCvt2LtsAtvDES1PwMx : 36|12@1+ (0.0625,-125) [-125|125.9375] "%" Vector__XXX
 SG_ PwCvt2LtsAtvDES1PwM : 48|12@1+ (0.0625,-125) [-125|125.9375] "%" Vector__XXX

BO_ 2565897470 PC2ILAM: 8 Vector__XXX
 SG_ PwrCnvrtr2LmtsAtvEltrlCr : 0|8@1+ (1,0) [0|250] "count" Vector__XXX
 SG_ PwrCnvrtr2LmtsAtvEltrlCntr : 8|4@1+ (1,0) [0|15] "" Vector__XXX
 SG_ PwrCnvrtr2LmtsAtvCrrntMxmm : 12|12@1+ (0.0625,-125) [-125|125.9375] "%" Vector__XXX
 SG_ PwrCnvrtr2LmtsAtvCrrntMnmm : 24|12@1+ (0.0625,-125) [-125|125.9375] "%" Vector__XXX
 SG_ PwrCnvrtr2LmtsAtvFrqnMxmm : 36|12@1+ (0.0625,-125) [-125|125.9375] "%" Vector__XXX
 SG_ PwrCnvrtr2LmtsAtvFrqnMnmm : 48|12@1+ (0.0625,-125) [-125|125.9375] "%" Vector__XXX

BO_ 2565897726 PC2ILADC: 8 Vector__XXX
 SG_ PwrCnvrtr2LmtsAtvDEnrgSr1Cr : 0|8@1+ (1,0) [0|250] "count" Vector__XXX
 SG_ PwrCnvrtr2LmtsAtvDEnrgSr1Cntr : 8|4@1+ (1,0) [0|15] "" Vector__XXX
 SG_ PwCvt2LtsAtvDES1VtMx : 12|12@1+ (0.0625,-125) [-125|125.9375] "%" Vector__XXX
 SG_ PwCvt2LtsAtvDES1VtM : 24|12@1+ (0.0625,-125) [-125|125.9375] "%" Vector__XXX
 SG_ PwCvt2LtsAtvDES1CtMx : 36|12@1+ (0.0625,-125) [-125|125.9375] "%" Vector__XXX
 SG_ PwCvt2LtsAtvDES1CtM : 48|12@1+ (0.0625,-125) [-125|125.9375] "%" Vector__XXX

BO_ 2565897982 PC2ILV: 8 Vector__XXX
 SG_ PwrCnvrtr2SwthdIgntnVltg : 0|16@1+ (0.05,0) [0|3212.75] "V" Vector__XXX
 SG_ PwrCnvrtr2UnswthdSlVltg : 16|16@1+ (0.05,0) [0|3212.75] "V" Vector__XXX

BO_ 2565898238 PC1IS2: 8 Vector__XXX
 SG_ PowerConverter1Status2Crc : 0|8@1+ (1,0) [0|250] "count" Vector__XXX
 SG_ PowerConverter1Status2Counter : 8|4@1+ (1,0) [0|15] "" Vector__XXX
 SG_ PwrCnvrtr1AvllMxmmCrrnt : 12|12@1+ (0.0625,-125) [-125|125.9375] "%" Vector__XXX
 SG_ PwrCnvrtr1AvllMnmmCrrnt : 24|12@1+ (0.0625,-125) [-125|125.9375] "%" Vector__XXX

BO_ 2565898494 PC1IRLA1: 8 Vector__XXX
 SG_ PwrCnvrtr1RtLmtsAtv1Cr : 0|8@1+ (1,0) [0|250] "count" Vector__XXX
 SG_ PwrCnvrtr1RtLmtsAtv1Cntr : 8|4@1+ (1,0) [0|15] "" Vector__XXX
 SG_ PwCvt1RtLtsAtvAstCtRtLt : 24|12@1+ (2,0) [0|8030] "%/s" Vector__XXX

BO_ 2565898750 PC2IS2: 8 Vector__XXX
 SG_ PowerConverter2Status2Crc : 0|8@1+ (1,0) [0|250] "count" Vector__XXX
 SG_ PowerConverter2Status2Counter : 8|4@1+ (1,0) [0|15] "" Vector__XXX
 SG_ PwrCnvrtr2AvllMxmmCrrnt : 12|12@1+ (0.0625,-125) [-125|125.9375] "%" Vector__XXX
 SG_ PwrCnvrtr2AvllMnmmCrrnt : 24|12@1+ (0.0625,-125) [-125|125.9375] "%" Vector__XXX

BO_ 2565899006 PC2IRLA1: 8 Vector__XXX
 SG_ PwrCnvrtr2RtLmtsAtv1Cr : 0|8@1+ (1,0) [0|250] "count" Vector__XXX
 SG_ PwrCnvrtr2RtLmtsAtv1Cntr : 8|4@1+ (1,0) [0|15] "" Vector__XXX
 SG_ PwCvt2RtLtsAtvAstCtRtLt : 24|12@1+ (2,0) [0|8030] "%/s" Vector__XXX

BO_ 2565899262 PC2II: 8 Vector__XXX
 SG_ PwrCnvrtr2IsltnIntgrtCr : 0|8@1+ (1,0) [0|250] "count" Vector__XXX
 SG_ PwrCnvrtr2IsltnIntgrtCntr : 8|4@1+ (1,0) [0|15] "" Vector__XXX
 SG_ PwCvt2DES1NtvTCsssGdVt : 12|12@1+ (0.0625,-125) [-125|125.9375] "%" Vector__XXX
 SG_ PwCvt2HVtBsAtvIstTstStts : 24|4@1+ (1,0) [0|15] "" Vector__XXX
 SG_ PwCvt2HVtBsPssvIstTstStts : 28|4@1+ (1,0) [0|15] "" Vector__XXX
 SG_ PwCvt2HVtBsAtvIstTstRsts : 32|16@1+ (0.1,0) [0|6425.5] "OhmPerV" Vector__XXX
 SG_ PwCvt2HVtBsPssvIstTstRsts : 48|16@1+ (0.1,0) [0|6425.5] "OhmPerV" Vector__XXX

BO_ 2565899518 PC1II: 8 Vector__XXX
 SG_ PwrCnvrtr1IsltnIntgrtCr : 0|8@1+ (1,0) [0|250] "count" Vector__XXX
 SG_ PwrCnvrtr1IsltnIntgrtCntr : 8|4@1+ (1,0) [0|15] "" Vector__XXX
 SG_ PwCvt1DES1NtvTCsssGdVt : 12|12@1+ (0.0625,-125) [-125|125.9375] "%" Vector__XXX
 SG_ PwCvt1HVtBsAtvIstTstStts : 24|4@1+ (1,0) [0|15] "" Vector__XXX
 SG_ PwCvt1HVtBsPssvIstTstStts : 28|4@1+ (1,0) [0|15] "" Vector__XXX
 SG_ PwCvt1HVtBsAtvIstTstRsts : 32|16@1+ (0.1,0) [0|6425.5] "OhmPerV" Vector__XXX
 SG_ PwCvt1HVtBsPssvIstTstRsts : 48|16@1+ (0.1,0) [0|6425.5] "OhmPerV" Vector__XXX

BO_ 2364573182 PC2IS1: 8 Vector__XXX
 SG_ PowerConverter2Status1Crc : 0|8@1+ (1,0) [0|250] "count" Vector__XXX
 SG_ PowerConverter2Status1Counter : 8|4@1+ (1,0) [0|15] "" Vector__XXX
 SG_ PowerConverter2Current : 12|12@1+ (0.0625,-125) [-125|125.9375] "%" Vector__XXX
 SG_ PowerConverter2Frequency : 24|16@1+ (0.00390625,-125) [-125|125.99609375] "%" Vector__XXX
 SG_ PwrCnvrtr2DEnrgSr1Crrnt : 40|12@1+ (0.0625,-125) [-125|125.9375] "%" Vector__XXX
 SG_ PwrCnvrtr2DEnrgSr1Vltg : 52|12@1+ (0.0625,-125) [-125|125.9375] "%" Vector__XXX

BO_ 2364573438 PC1IS1: 8 Vector__XXX
 SG_ PowerConverter1Status1Crc : 0|8@1+ (1,0) [0|250] "count" Vector__XXX
 SG_ PowerConverter1Status1Counter : 8|4@1+ (1,0) [0|15] "" Vector__XXX
 SG_ PowerConverter1Current : 12|12@1+ (0.0625,-125) [-125|125.9375] "%" Vector__XXX
 SG_ PowerConverter1Frequency : 24|16@1+ (0.00390625,-125) [-125|125.99609375] "%" Vector__XXX
 SG_ PwrCnvrtr1DEnrgSr1Crrnt : 40|12@1+ (0.0625,-125) [-125|125.9375] "%" Vector__XXX
 SG_ PwrCnvrtr1DEnrgSr1Vltg : 52|12@1+ (0.0625,-125) [-125|125.9375] "%" Vector__XXX

BO_ 2364690942 HVESP11S2: 8 Vector__XXX
 SG_ Hvsp11DshrgPwrLmtDTSttOfChrg : 0|2@1+ (1,0) [0|3] "" Vector__XXX
 SG_ Hvsp11DshrgPwrLmtDTBttrTmprtr : 2|2@1+ (1,0) [0|3] "" Vector__XXX
 SG_ Hvsp11DsPwLtDTBttDstCdt : 4|2@1+ (1,0) [0|3] "" Vector__XXX
 SG_ Hvsp11DsPwLtDTBttOCVt : 6|2@1+ (1,0) [0|3] "" Vector__XXX
 SG_ Hvsp11DshrgPwrLmtDTBttrCrrnt : 8|2@1+ (1,0) [0|3] "" Vector__XXX
 SG_ Hvsp11DshrgPwrLmtDTAnUndfndCs : 10|2@1+ (1,0) [0|3] "" Vector__XXX
 SG_ Hvsp11ChrgPwrLmtDTSttOfChrg : 32|2@1+ (1,0) [0|3] "" Vector__XXX
 SG_ Hvsp11ChrgPwrLmtDTBttrTmprtr : 34|2@1+ (1,0) [0|3] "" Vector__XXX
 SG_ Hvsp11CPwLtDTBttDstCdt : 36|2@1+ (1,0) [0|3] "" Vector__XXX
 SG_ Hvsp11ChrgPwrLmtDTBttrOrCllVltg : 38|2@1+ (1,0) [0|3] "" Vector__XXX
 SG_ Hvsp11ChrgPwrLmtDTBttrCrrnt : 40|2@1+ (1,0) [0|3] "" Vector__XXX
 SG_ Hvsp11ChrgPwrLmtDTAnUndfndCs : 42|2@1+ (1,0) [0|3] "" Vector__XXX

BO_ 2364691198 HVESP11D1: 8 Vector__XXX
 SG_ Hvesp11AvailableDischargePower : 0|16@1+ (0.05,0) [0|3212.75] "kW" Vector__XXX
 SG_ Hvesp11AvailableChargePower : 16|16@1+ (0.05,0) [0|3212.75] "kW" Vector__XXX
 SG_ Hvesp11VoltageLevel : 32|16@1+ (0.05,0) [0|3212.75] "V" Vector__XXX
 SG_ Hvesp11Current : 48|16@1+ (0.05,-1600) [-1600|1612.75] "A" Vector__XXX

BO_ 2364691454 HVESP11D2: 8 Vector__XXX
 SG_ Hvesp11FastUpdateStateOfCharge : 0|16@1+ (0.0015625,0) [0|100.3984375] "%" Vector__XXX
 SG_ Hvesp11HighestCellVoltage : 16|16@1+ (0.001,0) [0|64.255] "V" Vector__XXX
 SG_ Hvesp11LowestCellVoltage : 32|16@1+ (0.001,0) [0|64.255] "V" Vector__XXX
 SG_ Hvsp11CllVltgDffrntlStts : 48|4@1+ (1,0) [0|15] "" Vector__XXX

BO_ 2364691710 HVESP11D3: 8 Vector__XXX
 SG_ Hvesp11HighestCellTemperature : 0|16@1+ (0.03125,-273) [-273|1734.96875] "degC" Vector__XXX
 SG_ Hvesp11LowestCellTemperature : 16|16@1+ (0.03125,-273) [-273|1734.96875] "degC" Vector__XXX
 SG_ Hvesp11AverageCellTemperature : 32|16@1+ (0.03125,-273) [-273|1734.96875] "degC" Vector__XXX
 SG_ Hvsp11CllTmprtrDffrntlStts : 48|2@1+ (1,0) [0|3] "" Vector__XXX

BO_ 2364691966 HVESP11D4: 8 Vector__XXX
 SG_ Hvesp11DischargeCapacity : 0|16@1+ (0.01,0) [0|642.55] "Ah" Vector__XXX
 SG_ Hvesp11ChargeCapacity : 16|16@1+ (0.01,0) [0|642.55] "Ah" Vector__XXX
 SG_ Hvesp11CellBalancingCount : 32|16@1+ (1,0) [0|64255] "count" Vector__XXX

BO_ 2364692222 HVESP11D5: 8 Vector__XXX
 SG_ Hvesp11LowestCellStateOfCharge : 32|16@1+ (0.0015625,0) [0|100.3984375] "%" Vector__XXX
 SG_ Hvesp11HighestCellStateOfCharge : 48|16@1+ (0.0015625,0) [0|100.3984375] "%" Vector__XXX
 SG_ Hvsp11MxmmInstntnsDshrgCrrntLmt : 0|16@1+ (0.05,-1600) [-1600|0] "A" Vector__XXX
 SG_ Hvsp11MxmmInstntnsChrgCrrntLmt : 16|16@1+ (0.05,-1600) [0|1612.75] "A" Vector__XXX

BO_ 2364692478 HVESP11D6: 8 Vector__XXX
 SG_ Hvesp11BusVoltage : 0|16@1+ (0.05,0) [0|3212.75] "V" Vector__XXX
 SG_ Hvesp11IgnitionVoltage : 16|16@1+ (0.01,0) [0|642.55] "V" Vector__XXX
 SG_ Hvesp11IntakeCoolantTemperature : 32|8@1+ (1,-40) [-40|210] "degC" Vector__XXX
 SG_ Hvesp11OutletCoolantTemperature : 40|8@1+ (1,-40) [-40|210] "degC" Vector__XXX
 SG_ Hvesp11ElectronicsTemperature : 48|8@1+ (1,-40) [-40|210] "degC" Vector__XXX
 SG_ Hvesp11Temperature : 56|8@1+ (1,-40) [-40|210] "degC" Vector__XXX

BO_ 2364692734 HVESP11S1: 8 Vector__XXX
 SG_ Hvsp11HghVltgBsPstvCnttrStt : 0|2@1+ (1,0) [0|3] "" Vector__XXX
 SG_ Hvsp11HghVltgBsNgtvCnttrStt : 2|2@1+ (1,0) [0|3] "" Vector__XXX
 SG_ Hvsp11HghVltgBsDsnntFrwrnng : 4|4@1+ (1,0) [0|15] "" Vector__XXX
 SG_ Hvsp11HghVltgBsPrChrgRlStt : 8|2@1+ (1,0) [0|3] "" Vector__XXX
 SG_ Hvsp11CntrOfPkCnttrStt : 10|2@1+ (1,0) [0|3] "" Vector__XXX
 SG_ Hvsp11HghVltgBsAtvIsltnTstStts : 12|4@1+ (1,0) [0|15] "" Vector__XXX
 SG_ Hvsp11HghVltgBsPssvIsltnTstStts : 16|4@1+ (1,0) [0|15] "" Vector__XXX
 SG_ Hvesp11HvilStatus : 20|2@1+ (1,0) [0|3] "" Vector__XXX
 SG_ Hvesp11InertiaSwitchStatus : 22|2@1+ (1,0) [0|3] "" Vector__XXX
 SG_ Hvesp11StateOfChargeStatus : 24|4@1+ (1,0) [0|15] "" Vector__XXX
 SG_ Hvesp11CellBalanceStatus : 28|2@1+ (1,0) [0|3] "" Vector__XXX
 SG_ Hvesp11CellBalancingActive : 30|2@1+ (1,0) [0|3] "" Vector__XXX
 SG_ Hvesp11InternalChargerStatus : 32|2@1+ (1,0) [0|3] "" Vector__XXX
 SG_ Hvsp11HghVltgBsCnntnStts : 40|4@1+ (1,0) [0|15] "" Vector__XXX
 SG_ Hvesp11OperationalStatus : 44|4@1+ (1,0) [0|15] "" Vector__XXX
 SG_ Hvesp11Status1Counter : 52|4@1+ (1,0) [0|15] "" Vector__XXX
 SG_ Hvesp11Status1Crc : 56|8@1+ (1,0) [0|250] "count" Vector__XXX

BO_ 2364692990 HVESP11D7: 8 Vector__XXX
 SG_ Hvesp11DischargeEnergyCapacity : 0|24@1+ (0.001,0) [0|16449.535] "kWh" Vector__XXX
 SG_ Hvesp11ChargeEnergyCapacity : 24|24@1+ (0.001,0) [0|16449.535] "kWh" Vector__XXX
 SG_ Hvsp11MxmmChrgVltgLmt : 48|16@1+ (0.05,0) [0|3212.75] "V" Vector__XXX

BO_ 2364693246 HVESP11MS1: 8 Vector__XXX
 SG_ Hvesp11Module1OperationalStatus : 0|2@1+ (1,0) [0|3] "" Vector__XXX
 SG_ Hvesp11Module2OperationalStatus : 2|2@1+ (1,0) [0|3] "" Vector__XXX
 SG_ Hvesp11Module3OperationalStatus : 4|2@1+ (1,0) [0|3] "" Vector__XXX
 SG_ Hvesp11Module4OperationalStatus : 6|2@1+ (1,0) [0|3] "" Vector__XXX
 SG_ Hvesp11Module5OperationalStatus : 8|2@1+ (1,0) [0|3] "" Vector__XXX
 SG_ Hvesp11Module6OperationalStatus : 10|2@1+ (1,0) [0|3] "" Vector__XXX
 SG_ Hvesp11Module7OperationalStatus : 12|2@1+ (1,0) [0|3] "" Vector__XXX
 SG_ Hvesp11Module8OperationalStatus : 14|2@1+ (1,0) [0|3] "" Vector__XXX
 SG_ Hvesp11Module9OperationalStatus : 16|2@1+ (1,0) [0|3] "" Vector__XXX
 SG_ Hvsp11Mdl10OprtnlStts : 18|2@1+ (1,0) [0|3] "" Vector__XXX
 SG_ Hvsp11Mdl11OprtnlStts : 20|2@1+ (1,0) [0|3] "" Vector__XXX
 SG_ Hvsp11Mdl12OprtnlStts : 22|2@1+ (1,0) [0|3] "" Vector__XXX
 SG_ Hvsp11Mdl13OprtnlStts : 24|2@1+ (1,0) [0|3] "" Vector__XXX
 SG_ Hvsp11Mdl14OprtnlStts : 26|2@1+ (1,0) [0|3] "" Vector__XXX
 SG_ Hvsp11Mdl15OprtnlStts : 28|2@1+ (1,0) [0|3] "" Vector__XXX
 SG_ Hvsp11Mdl16OprtnlStts : 30|2@1+ (1,0) [0|3] "" Vector__XXX
 SG_ Hvsp11Mdl17OprtnlStts : 32|2@1+ (1,0) [0|3] "" Vector__XXX
 SG_ Hvsp11Mdl18OprtnlStts : 34|2@1+ (1,0) [0|3] "" Vector__XXX
 SG_ Hvsp11Mdl19OprtnlStts : 36|2@1+ (1,0) [0|3] "" Vector__XXX
 SG_ Hvsp11Mdl20OprtnlStts : 38|2@1+ (1,0) [0|3] "" Vector__XXX
 SG_ Hvsp11Mdl21OprtnlStts : 40|2@1+ (1,0) [0|3] "" Vector__XXX
 SG_ Hvsp11Mdl22OprtnlStts : 42|2@1+ (1,0) [0|3] "" Vector__XXX
 SG_ Hvsp11Mdl23OprtnlStts : 44|2@1+ (1,0) [0|3] "" Vector__XXX
 SG_ Hvsp11Mdl24OprtnlStts : 46|2@1+ (1,0) [0|3] "" Vector__XXX
 SG_ Hvsp11Mdl25OprtnlStts : 48|2@1+ (1,0) [0|3] "" Vector__XXX
 SG_ Hvsp11Mdl26OprtnlStts : 50|2@1+ (1,0) [0|3] "" Vector__XXX
 SG_ Hvsp11Mdl27OprtnlStts : 52|2@1+ (1,0) [0|3] "" Vector__XXX
 SG_ Hvsp11Mdl28OprtnlStts : 54|2@1+ (1,0) [0|3] "" Vector__XXX
 SG_ Hvsp11Mdl29OprtnlStts : 56|2@1+ (1,0) [0|3] "" Vector__XXX
 SG_ Hvsp11Mdl30OprtnlStts : 58|2@1+ (1,0) [0|3] "" Vector__XXX
 SG_ Hvsp11Mdl31OprtnlStts : 60|2@1+ (1,0) [0|3] "" Vector__XXX
 SG_ Hvsp11Mdl32OprtnlStts : 62|2@1+ (1,0) [0|3] "" Vector__XXX

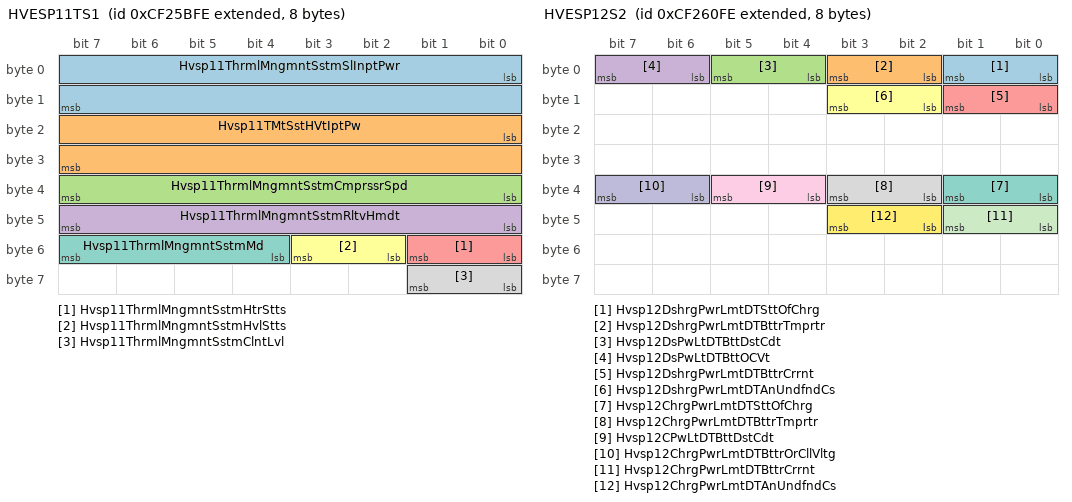
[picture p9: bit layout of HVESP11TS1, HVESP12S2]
BO_ 2364693502 HVESP11TS1: 8 Vector__XXX
 SG_ Hvsp11ThrmlMngmntSstmSlInptPwr : 0|16@1+ (0.5,0) [0|32127.5] "W" Vector__XXX
 SG_ Hvsp11TMtSstHVtIptPw : 16|16@1+ (0.5,0) [0|32127.5] "W" Vector__XXX
 SG_ Hvsp11ThrmlMngmntSstmCmprssrSpd : 32|8@1+ (32,0) [0|8000] "rpm" Vector__XXX
 SG_ Hvsp11ThrmlMngmntSstmRltvHmdt : 40|8@1+ (0.4,0) [0|100] "%" Vector__XXX
 SG_ Hvsp11ThrmlMngmntSstmHtrStts : 48|2@1+ (1,0) [0|3] "" Vector__XXX
 SG_ Hvsp11ThrmlMngmntSstmHvlStts : 50|2@1+ (1,0) [0|3] "" Vector__XXX
 SG_ Hvsp11ThrmlMngmntSstmMd : 52|4@1+ (1,0) [0|15] "" Vector__XXX
 SG_ Hvsp11ThrmlMngmntSstmClntLvl : 56|2@1+ (1,0) [0|3] "" Vector__XXX

BO_ 2364693758 HVESP11D8: 8 Vector__XXX
 SG_ Hvsp11HghstCllVltgMdlNmr : 0|8@1+ (1,0) [0|250] "count" Vector__XXX
 SG_ Hvsp11HghstCllVltgCllNmr : 8|8@1+ (1,0) [0|250] "count" Vector__XXX
 SG_ Hvsp11LwstCllVltgMdlNmr : 16|8@1+ (1,0) [0|250] "count" Vector__XXX
 SG_ Hvsp11LwstCllVltgCllNmr : 24|8@1+ (1,0) [0|250] "count" Vector__XXX
 SG_ Hvesp11AverageCellVoltage : 32|16@1+ (0.001,0) [0|64.255] "V" Vector__XXX

BO_ 2364694014 HVESP11D9: 8 Vector__XXX
 SG_ Hvsp11HghstCllTmprtrMdlNmr : 0|8@1+ (1,0) [0|250] "count" Vector__XXX
 SG_ Hvsp11HghstCllTmprtrCllNmr : 8|8@1+ (1,0) [0|250] "count" Vector__XXX
 SG_ Hvsp11LwstCllTmprtrMdlNmr : 16|8@1+ (1,0) [0|250] "count" Vector__XXX
 SG_ Hvsp11LwstCllTmprtrCllNmr : 24|8@1+ (1,0) [0|250] "count" Vector__XXX
 SG_ Hvess11ThermalEventDetected : 32|2@1+ (1,0) [0|3] "" Vector__XXX
 SG_ Hvsp11Dt9EmdddIntgrtSpprt : 50|2@1+ (1,0) [0|3] "" Vector__XXX
 SG_ Hvesp11Data9Counter : 52|4@1+ (1,0) [0|15] "" Vector__XXX
 SG_ Hvesp11Data9Crc : 56|8@1+ (1,0) [0|250] "count" Vector__XXX

BO_ 2364694270 HVESP11D10: 8 Vector__XXX
 SG_ Hvsp11HghstCllSttOfChrgMdlNmr : 0|8@1+ (1,0) [0|250] "count" Vector__XXX
 SG_ Hvsp11HghstCllSttOfChrgCllNmr : 8|8@1+ (1,0) [0|250] "count" Vector__XXX
 SG_ Hvsp11LwstCllSttOfChrgMdlNmr : 16|8@1+ (1,0) [0|250] "count" Vector__XXX
 SG_ Hvsp11LwstCllSttOfChrgCllNmr : 24|8@1+ (1,0) [0|250] "count" Vector__XXX
 SG_ Hvsp11HghVltgBsAtvIsltnTstRslts : 32|16@1+ (0.1,0) [0|6425.5] "OhmPerV" Vector__XXX
 SG_ Hvsp11HVtBsPssvIstTstRsts : 48|16@1+ (0.1,0) [0|6425.5] "OhmPerV" Vector__XXX

BO_ 2364694526 HVESP11D11: 8 Vector__XXX
 SG_ Hvsp11BsVltgNgtvTChsssGrndVltg : 0|16@1+ (0.05,0) [0|3212.75] "V" Vector__XXX
 SG_ Hvsp11VltgLvlNgtvTChsssGrndVltg : 16|16@1+ (0.05,0) [0|3212.75] "V" Vector__XXX
 SG_ Hvesp11ActualChargeRate : 32|16@1+ (0.05,0) [0|3212.75] "kW" Vector__XXX

BO_ 2364694782 HVESP12S2: 8 Vector__XXX
 SG_ Hvsp12DshrgPwrLmtDTSttOfChrg : 0|2@1+ (1,0) [0|3] "" Vector__XXX
 SG_ Hvsp12DshrgPwrLmtDTBttrTmprtr : 2|2@1+ (1,0) [0|3] "" Vector__XXX
 SG_ Hvsp12DsPwLtDTBttDstCdt : 4|2@1+ (1,0) [0|3] "" Vector__XXX
 SG_ Hvsp12DsPwLtDTBttOCVt : 6|2@1+ (1,0) [0|3] "" Vector__XXX
 SG_ Hvsp12DshrgPwrLmtDTBttrCrrnt : 8|2@1+ (1,0) [0|3] "" Vector__XXX
 SG_ Hvsp12DshrgPwrLmtDTAnUndfndCs : 10|2@1+ (1,0) [0|3] "" Vector__XXX
 SG_ Hvsp12ChrgPwrLmtDTSttOfChrg : 32|2@1+ (1,0) [0|3] "" Vector__XXX
 SG_ Hvsp12ChrgPwrLmtDTBttrTmprtr : 34|2@1+ (1,0) [0|3] "" Vector__XXX
 SG_ Hvsp12CPwLtDTBttDstCdt : 36|2@1+ (1,0) [0|3] "" Vector__XXX
 SG_ Hvsp12ChrgPwrLmtDTBttrOrCllVltg : 38|2@1+ (1,0) [0|3] "" Vector__XXX
 SG_ Hvsp12ChrgPwrLmtDTBttrCrrnt : 40|2@1+ (1,0) [0|3] "" Vector__XXX
 SG_ Hvsp12ChrgPwrLmtDTAnUndfndCs : 42|2@1+ (1,0) [0|3] "" Vector__XXX

BO_ 2364695038 HVESP12D1: 8 Vector__XXX
 SG_ Hvesp12AvailableDischargePower : 0|16@1+ (0.05,0) [0|3212.75] "kW" Vector__XXX
 SG_ Hvesp12AvailableChargePower : 16|16@1+ (0.05,0) [0|3212.75] "kW" Vector__XXX
 SG_ Hvesp12VoltageLevel : 32|16@1+ (0.05,0) [0|3212.75] "V" Vector__XXX
 SG_ Hvesp12Current : 48|16@1+ (0.05,-1600) [-1600|1612.75] "A" Vector__XXX

BO_ 2364695294 HVESP12D2: 8 Vector__XXX
 SG_ Hvesp12FastUpdateStateOfCharge : 0|16@1+ (0.0015625,0) [0|100.3984375] "%" Vector__XXX
 SG_ Hvesp12HighestCellVoltage : 16|16@1+ (0.001,0) [0|64.255] "V" Vector__XXX
 SG_ Hvesp12LowestCellVoltage : 32|16@1+ (0.001,0) [0|64.255] "V" Vector__XXX
 SG_ Hvsp12CllVltgDffrntlStts : 48|4@1+ (1,0) [0|15] "" Vector__XXX

BO_ 2364695550 HVESP12D3: 8 Vector__XXX
 SG_ Hvesp12HighestCellTemperature : 0|16@1+ (0.03125,-273) [-273|1734.96875] "degC" Vector__XXX
 SG_ Hvesp12LowestCellTemperature : 16|16@1+ (0.03125,-273) [-273|1734.96875] "degC" Vector__XXX
 SG_ Hvesp12AverageCellTemperature : 32|16@1+ (0.03125,-273) [-273|1734.96875] "degC" Vector__XXX
 SG_ Hvsp12CllTmprtrDffrntlStts : 48|2@1+ (1,0) [0|3] "" Vector__XXX

BO_ 2364695806 HVESP12D4: 8 Vector__XXX
 SG_ Hvesp12DischargeCapacity : 0|16@1+ (0.01,0) [0|642.55] "Ah" Vector__XXX
 SG_ Hvesp12ChargeCapacity : 16|16@1+ (0.01,0) [0|642.55] "Ah" Vector__XXX
 SG_ Hvesp12CellBalancingCount : 32|16@1+ (1,0) [0|64255] "count" Vector__XXX

BO_ 2364696062 HVESP12D5: 8 Vector__XXX
 SG_ Hvesp12LowestCellStateOfCharge : 32|16@1+ (0.0015625,0) [0|100.3984375] "%" Vector__XXX
 SG_ Hvesp12HighestCellStateOfCharge : 48|16@1+ (0.0015625,0) [0|100.3984375] "%" Vector__XXX
 SG_ Hvsp12MxmmInstntnsDshrgCrrntLmt : 0|16@1+ (0.05,-1600) [-1600|0] "A" Vector__XXX
 SG_ Hvsp12MxmmInstntnsChrgCrrntLmt : 16|16@1+ (0.05,-1600) [0|1612.75] "A" Vector__XXX

BO_ 2364696318 HVESP12D6: 8 Vector__XXX
 SG_ Hvesp12BusVoltage : 0|16@1+ (0.05,0) [0|3212.75] "V" Vector__XXX
 SG_ Hvesp12IgnitionVoltage : 16|16@1+ (0.01,0) [0|642.55] "V" Vector__XXX
 SG_ Hvesp12IntakeCoolantTemperature : 32|8@1+ (1,-40) [-40|210] "degC" Vector__XXX
 SG_ Hvesp12OutletCoolantTemperature : 40|8@1+ (1,-40) [-40|210] "degC" Vector__XXX
 SG_ Hvesp12ElectronicsTemperature : 48|8@1+ (1,-40) [-40|210] "degC" Vector__XXX
 SG_ Hvesp12Temperature : 56|8@1+ (1,-40) [-40|210] "degC" Vector__XXX

BO_ 2364696574 HVESP12S1: 8 Vector__XXX
 SG_ Hvsp12HghVltgBsPstvCnttrStt : 0|2@1+ (1,0) [0|3] "" Vector__XXX
 SG_ Hvsp12HghVltgBsNgtvCnttrStt : 2|2@1+ (1,0) [0|3] "" Vector__XXX
 SG_ Hvsp12HghVltgBsDsnntFrwrnng : 4|4@1+ (1,0) [0|15] "" Vector__XXX
 SG_ Hvsp12HghVltgBsPrChrgRlStt : 8|2@1+ (1,0) [0|3] "" Vector__XXX
 SG_ Hvsp12CntrOfPkCnttrStt : 10|2@1+ (1,0) [0|3] "" Vector__XXX
 SG_ Hvsp12HghVltgBsAtvIsltnTstStts : 12|4@1+ (1,0) [0|15] "" Vector__XXX
 SG_ Hvsp12HghVltgBsPssvIsltnTstStts : 16|4@1+ (1,0) [0|15] "" Vector__XXX
 SG_ Hvesp12HvilStatus : 20|2@1+ (1,0) [0|3] "" Vector__XXX
 SG_ Hvesp12InertiaSwitchStatus : 22|2@1+ (1,0) [0|3] "" Vector__XXX
 SG_ Hvesp12StateOfChargeStatus : 24|4@1+ (1,0) [0|15] "" Vector__XXX
 SG_ Hvesp12CellBalanceStatus : 28|2@1+ (1,0) [0|3] "" Vector__XXX
 SG_ Hvesp12CellBalancingActive : 30|2@1+ (1,0) [0|3] "" Vector__XXX
 SG_ Hvesp12InternalChargerStatus : 32|2@1+ (1,0) [0|3] "" Vector__XXX
 SG_ Hvsp12HghVltgBsCnntnStts : 40|4@1+ (1,0) [0|15] "" Vector__XXX
 SG_ Hvesp12OperationalStatus : 44|4@1+ (1,0) [0|15] "" Vector__XXX
 SG_ Hvesp12Status1Counter : 52|4@1+ (1,0) [0|15] "" Vector__XXX
 SG_ Hvesp12Status1Crc : 56|8@1+ (1,0) [0|250] "count" Vector__XXX

BO_ 2364696830 HVESP12D7: 8 Vector__XXX
 SG_ Hvesp12DischargeEnergyCapacity : 0|24@1+ (0.001,0) [0|16449.535] "kWh" Vector__XXX
 SG_ Hvesp12ChargeEnergyCapacity : 24|24@1+ (0.001,0) [0|16449.535] "kWh" Vector__XXX
 SG_ Hvsp12MxmmChrgVltgLmt : 48|16@1+ (0.05,0) [0|3212.75] "V" Vector__XXX

BO_ 2364697086 HVESP12MS1: 8 Vector__XXX
 SG_ Hvesp12Module1OperationalStatus : 0|2@1+ (1,0) [0|3] "" Vector__XXX
 SG_ Hvesp12Module2OperationalStatus : 2|2@1+ (1,0) [0|3] "" Vector__XXX
 SG_ Hvesp12Module3OperationalStatus : 4|2@1+ (1,0) [0|3] "" Vector__XXX
 SG_ Hvesp12Module4OperationalStatus : 6|2@1+ (1,0) [0|3] "" Vector__XXX
 SG_ Hvesp12Module5OperationalStatus : 8|2@1+ (1,0) [0|3] "" Vector__XXX
 SG_ Hvesp12Module6OperationalStatus : 10|2@1+ (1,0) [0|3] "" Vector__XXX
 SG_ Hvesp12Module7OperationalStatus : 12|2@1+ (1,0) [0|3] "" Vector__XXX
 SG_ Hvesp12Module8OperationalStatus : 14|2@1+ (1,0) [0|3] "" Vector__XXX
 SG_ Hvesp12Module9OperationalStatus : 16|2@1+ (1,0) [0|3] "" Vector__XXX
 SG_ Hvsp12Mdl10OprtnlStts : 18|2@1+ (1,0) [0|3] "" Vector__XXX
 SG_ Hvsp12Mdl11OprtnlStts : 20|2@1+ (1,0) [0|3] "" Vector__XXX
 SG_ Hvsp12Mdl12OprtnlStts : 22|2@1+ (1,0) [0|3] "" Vector__XXX
 SG_ Hvsp12Mdl13OprtnlStts : 24|2@1+ (1,0) [0|3] "" Vector__XXX
 SG_ Hvsp12Mdl14OprtnlStts : 26|2@1+ (1,0) [0|3] "" Vector__XXX
 SG_ Hvsp12Mdl15OprtnlStts : 28|2@1+ (1,0) [0|3] "" Vector__XXX
 SG_ Hvsp12Mdl16OprtnlStts : 30|2@1+ (1,0) [0|3] "" Vector__XXX
 SG_ Hvsp12Mdl17OprtnlStts : 32|2@1+ (1,0) [0|3] "" Vector__XXX
 SG_ Hvsp12Mdl18OprtnlStts : 34|2@1+ (1,0) [0|3] "" Vector__XXX
 SG_ Hvsp12Mdl19OprtnlStts : 36|2@1+ (1,0) [0|3] "" Vector__XXX
 SG_ Hvsp12Mdl20OprtnlStts : 38|2@1+ (1,0) [0|3] "" Vector__XXX
 SG_ Hvsp12Mdl21OprtnlStts : 40|2@1+ (1,0) [0|3] "" Vector__XXX
 SG_ Hvsp12Mdl22OprtnlStts : 42|2@1+ (1,0) [0|3] "" Vector__XXX
 SG_ Hvsp12Mdl23OprtnlStts : 44|2@1+ (1,0) [0|3] "" Vector__XXX
 SG_ Hvsp12Mdl24OprtnlStts : 46|2@1+ (1,0) [0|3] "" Vector__XXX
 SG_ Hvsp12Mdl25OprtnlStts : 48|2@1+ (1,0) [0|3] "" Vector__XXX
 SG_ Hvsp12Mdl26OprtnlStts : 50|2@1+ (1,0) [0|3] "" Vector__XXX
 SG_ Hvsp12Mdl27OprtnlStts : 52|2@1+ (1,0) [0|3] "" Vector__XXX
 SG_ Hvsp12Mdl28OprtnlStts : 54|2@1+ (1,0) [0|3] "" Vector__XXX
 SG_ Hvsp12Mdl29OprtnlStts : 56|2@1+ (1,0) [0|3] "" Vector__XXX
 SG_ Hvsp12Mdl30OprtnlStts : 58|2@1+ (1,0) [0|3] "" Vector__XXX
 SG_ Hvsp12Mdl31OprtnlStts : 60|2@1+ (1,0) [0|3] "" Vector__XXX
 SG_ Hvsp12Mdl32OprtnlStts : 62|2@1+ (1,0) [0|3] "" Vector__XXX

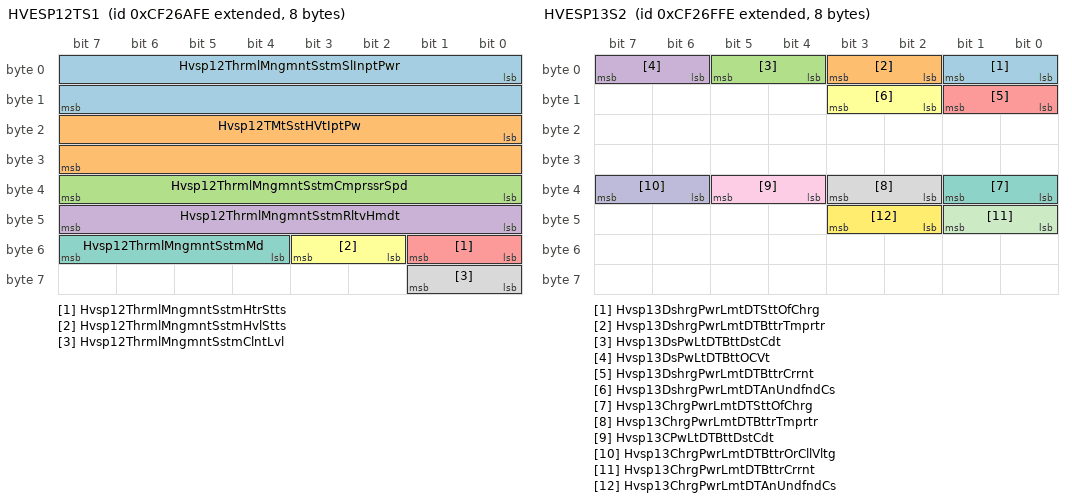
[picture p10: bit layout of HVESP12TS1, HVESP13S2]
BO_ 2364697342 HVESP12TS1: 8 Vector__XXX
 SG_ Hvsp12ThrmlMngmntSstmSlInptPwr : 0|16@1+ (0.5,0) [0|32127.5] "W" Vector__XXX
 SG_ Hvsp12TMtSstHVtIptPw : 16|16@1+ (0.5,0) [0|32127.5] "W" Vector__XXX
 SG_ Hvsp12ThrmlMngmntSstmCmprssrSpd : 32|8@1+ (32,0) [0|8000] "rpm" Vector__XXX
 SG_ Hvsp12ThrmlMngmntSstmRltvHmdt : 40|8@1+ (0.4,0) [0|100] "%" Vector__XXX
 SG_ Hvsp12ThrmlMngmntSstmHtrStts : 48|2@1+ (1,0) [0|3] "" Vector__XXX
 SG_ Hvsp12ThrmlMngmntSstmHvlStts : 50|2@1+ (1,0) [0|3] "" Vector__XXX
 SG_ Hvsp12ThrmlMngmntSstmMd : 52|4@1+ (1,0) [0|15] "" Vector__XXX
 SG_ Hvsp12ThrmlMngmntSstmClntLvl : 56|2@1+ (1,0) [0|3] "" Vector__XXX

BO_ 2364697598 HVESP12D8: 8 Vector__XXX
 SG_ Hvsp12HghstCllVltgMdlNmr : 0|8@1+ (1,0) [0|250] "count" Vector__XXX
 SG_ Hvsp12HghstCllVltgCllNmr : 8|8@1+ (1,0) [0|250] "count" Vector__XXX
 SG_ Hvsp12LwstCllVltgMdlNmr : 16|8@1+ (1,0) [0|250] "count" Vector__XXX
 SG_ Hvsp12LwstCllVltgCllNmr : 24|8@1+ (1,0) [0|250] "count" Vector__XXX
 SG_ Hvesp12AverageCellVoltage : 32|16@1+ (0.001,0) [0|64.255] "V" Vector__XXX

BO_ 2364697854 HVESP12D9: 8 Vector__XXX
 SG_ Hvsp12HghstCllTmprtrMdlNmr : 0|8@1+ (1,0) [0|250] "count" Vector__XXX
 SG_ Hvsp12HghstCllTmprtrCllNmr : 8|8@1+ (1,0) [0|250] "count" Vector__XXX
 SG_ Hvsp12LwstCllTmprtrMdlNmr : 16|8@1+ (1,0) [0|250] "count" Vector__XXX
 SG_ Hvsp12LwstCllTmprtrCllNmr : 24|8@1+ (1,0) [0|250] "count" Vector__XXX
 SG_ Hvess12ThermalEventDetected : 32|2@1+ (1,0) [0|3] "" Vector__XXX
 SG_ Hvsp12Dt9EmdddIntgrtSpprt : 50|2@1+ (1,0) [0|3] "" Vector__XXX
 SG_ Hvesp12Data9Counter : 52|4@1+ (1,0) [0|15] "" Vector__XXX
 SG_ Hvesp12Data9Crc : 56|8@1+ (1,0) [0|250] "count" Vector__XXX

BO_ 2364698110 HVESP12D10: 8 Vector__XXX
 SG_ Hvsp12HghstCllSttOfChrgMdlNmr : 0|8@1+ (1,0) [0|250] "count" Vector__XXX
 SG_ Hvsp12HghstCllSttOfChrgCllNmr : 8|8@1+ (1,0) [0|250] "count" Vector__XXX
 SG_ Hvsp12LwstCllSttOfChrgMdlNmr : 16|8@1+ (1,0) [0|250] "count" Vector__XXX
 SG_ Hvsp12LwstCllSttOfChrgCllNmr : 24|8@1+ (1,0) [0|250] "count" Vector__XXX
 SG_ Hvsp12HghVltgBsAtvIsltnTstRslts : 32|16@1+ (0.1,0) [0|6425.5] "OhmPerV" Vector__XXX
 SG_ Hvsp12HVtBsPssvIstTstRsts : 48|16@1+ (0.1,0) [0|6425.5] "OhmPerV" Vector__XXX

BO_ 2364698366 HVESP12D11: 8 Vector__XXX
 SG_ Hvsp12BsVltgNgtvTChsssGrndVltg : 0|16@1+ (0.05,0) [0|3212.75] "V" Vector__XXX
 SG_ Hvsp12VltgLvlNgtvTChsssGrndVltg : 16|16@1+ (0.05,0) [0|3212.75] "V" Vector__XXX
 SG_ Hvesp12ActualChargeRate : 32|16@1+ (0.05,0) [0|3212.75] "kW" Vector__XXX

BO_ 2364698622 HVESP13S2: 8 Vector__XXX
 SG_ Hvsp13DshrgPwrLmtDTSttOfChrg : 0|2@1+ (1,0) [0|3] "" Vector__XXX
 SG_ Hvsp13DshrgPwrLmtDTBttrTmprtr : 2|2@1+ (1,0) [0|3] "" Vector__XXX
 SG_ Hvsp13DsPwLtDTBttDstCdt : 4|2@1+ (1,0) [0|3] "" Vector__XXX
 SG_ Hvsp13DsPwLtDTBttOCVt : 6|2@1+ (1,0) [0|3] "" Vector__XXX
 SG_ Hvsp13DshrgPwrLmtDTBttrCrrnt : 8|2@1+ (1,0) [0|3] "" Vector__XXX
 SG_ Hvsp13DshrgPwrLmtDTAnUndfndCs : 10|2@1+ (1,0) [0|3] "" Vector__XXX
 SG_ Hvsp13ChrgPwrLmtDTSttOfChrg : 32|2@1+ (1,0) [0|3] "" Vector__XXX
 SG_ Hvsp13ChrgPwrLmtDTBttrTmprtr : 34|2@1+ (1,0) [0|3] "" Vector__XXX
 SG_ Hvsp13CPwLtDTBttDstCdt : 36|2@1+ (1,0) [0|3] "" Vector__XXX
 SG_ Hvsp13ChrgPwrLmtDTBttrOrCllVltg : 38|2@1+ (1,0) [0|3] "" Vector__XXX
 SG_ Hvsp13ChrgPwrLmtDTBttrCrrnt : 40|2@1+ (1,0) [0|3] "" Vector__XXX
 SG_ Hvsp13ChrgPwrLmtDTAnUndfndCs : 42|2@1+ (1,0) [0|3] "" Vector__XXX

BO_ 2364698878 HVESP13D1: 8 Vector__XXX
 SG_ Hvesp13AvailableDischargePower : 0|16@1+ (0.05,0) [0|3212.75] "kW" Vector__XXX
 SG_ Hvesp13AvailableChargePower : 16|16@1+ (0.05,0) [0|3212.75] "kW" Vector__XXX
 SG_ Hvesp13VoltageLevel : 32|16@1+ (0.05,0) [0|3212.75] "V" Vector__XXX
 SG_ Hvesp13Current : 48|16@1+ (0.05,-1600) [-1600|1612.75] "A" Vector__XXX

BO_ 2364699134 HVESP13D2: 8 Vector__XXX
 SG_ Hvesp13FastUpdateStateOfCharge : 0|16@1+ (0.0015625,0) [0|100.3984375] "%" Vector__XXX
 SG_ Hvesp13HighestCellVoltage : 16|16@1+ (0.001,0) [0|64.255] "V" Vector__XXX
 SG_ Hvesp13LowestCellVoltage : 32|16@1+ (0.001,0) [0|64.255] "V" Vector__XXX
 SG_ Hvsp13CllVltgDffrntlStts : 48|4@1+ (1,0) [0|15] "" Vector__XXX

BO_ 2364699390 HVESP13D3: 8 Vector__XXX
 SG_ Hvesp13HighestCellTemperature : 0|16@1+ (0.03125,-273) [-273|1734.96875] "degC" Vector__XXX
 SG_ Hvesp13LowestCellTemperature : 16|16@1+ (0.03125,-273) [-273|1734.96875] "degC" Vector__XXX
 SG_ Hvesp13AverageCellTemperature : 32|16@1+ (0.03125,-273) [-273|1734.96875] "degC" Vector__XXX
 SG_ Hvsp13CllTmprtrDffrntlStts : 48|2@1+ (1,0) [0|3] "" Vector__XXX

BO_ 2364699646 HVESP13D4: 8 Vector__XXX
 SG_ Hvesp13DischargeCapacity : 0|16@1+ (0.01,0) [0|642.55] "Ah" Vector__XXX
 SG_ Hvesp13ChargeCapacity : 16|16@1+ (0.01,0) [0|642.55] "Ah" Vector__XXX
 SG_ Hvesp13CellBalancingCount : 32|16@1+ (1,0) [0|64255] "count" Vector__XXX

BO_ 2364699902 HVESP13D5: 8 Vector__XXX
 SG_ Hvesp13LowestCellStateOfCharge : 32|16@1+ (0.0015625,0) [0|100.3984375] "%" Vector__XXX
 SG_ Hvesp13HighestCellStateOfCharge : 48|16@1+ (0.0015625,0) [0|100.3984375] "%" Vector__XXX
 SG_ Hvsp13MxmmInstntnsDshrgCrrntLmt : 0|16@1+ (0.05,-1600) [-1600|0] "A" Vector__XXX
 SG_ Hvsp13MxmmInstntnsChrgCrrntLmt : 16|16@1+ (0.05,-1600) [0|1612.75] "A" Vector__XXX

BO_ 2364700158 HVESP13D6: 8 Vector__XXX
 SG_ Hvesp13BusVoltage : 0|16@1+ (0.05,0) [0|3212.75] "V" Vector__XXX
 SG_ Hvesp13IgnitionVoltage : 16|16@1+ (0.01,0) [0|642.55] "V" Vector__XXX
 SG_ Hvesp13IntakeCoolantTemperature : 32|8@1+ (1,-40) [-40|210] "degC" Vector__XXX
 SG_ Hvesp13OutletCoolantTemperature : 40|8@1+ (1,-40) [-40|210] "degC" Vector__XXX
 SG_ Hvesp13ElectronicsTemperature : 48|8@1+ (1,-40) [-40|210] "degC" Vector__XXX
 SG_ Hvesp13Temperature : 56|8@1+ (1,-40) [-40|210] "degC" Vector__XXX

BO_ 2364700414 HVESP13S1: 8 Vector__XXX
 SG_ Hvsp13HghVltgBsPstvCnttrStt : 0|2@1+ (1,0) [0|3] "" Vector__XXX
 SG_ Hvsp13HghVltgBsNgtvCnttrStt : 2|2@1+ (1,0) [0|3] "" Vector__XXX
 SG_ Hvsp13HghVltgBsDsnntFrwrnng : 4|4@1+ (1,0) [0|15] "" Vector__XXX
 SG_ Hvsp13HghVltgBsPrChrgRlStt : 8|2@1+ (1,0) [0|3] "" Vector__XXX
 SG_ Hvsp13CntrOfPkCnttrStt : 10|2@1+ (1,0) [0|3] "" Vector__XXX
 SG_ Hvsp13HghVltgBsAtvIsltnTstStts : 12|4@1+ (1,0) [0|15] "" Vector__XXX
 SG_ Hvsp13HghVltgBsPssvIsltnTstStts : 16|4@1+ (1,0) [0|15] "" Vector__XXX
 SG_ Hvesp13HvilStatus : 20|2@1+ (1,0) [0|3] "" Vector__XXX
 SG_ Hvesp13InertiaSwitchStatus : 22|2@1+ (1,0) [0|3] "" Vector__XXX
 SG_ Hvesp13StateOfChargeStatus : 24|4@1+ (1,0) [0|15] "" Vector__XXX
 SG_ Hvesp13CellBalanceStatus : 28|2@1+ (1,0) [0|3] "" Vector__XXX
 SG_ Hvesp13CellBalancingActive : 30|2@1+ (1,0) [0|3] "" Vector__XXX
 SG_ Hvesp13InternalChargerStatus : 32|2@1+ (1,0) [0|3] "" Vector__XXX
 SG_ Hvsp13HghVltgBsCnntnStts : 40|4@1+ (1,0) [0|15] "" Vector__XXX
 SG_ Hvesp13OperationalStatus : 44|4@1+ (1,0) [0|15] "" Vector__XXX
 SG_ Hvesp13Status1Counter : 52|4@1+ (1,0) [0|15] "" Vector__XXX
 SG_ Hvesp13Status1Crc : 56|8@1+ (1,0) [0|250] "count" Vector__XXX

BO_ 2364700670 HVESP13D7: 8 Vector__XXX
 SG_ Hvesp13DischargeEnergyCapacity : 0|24@1+ (0.001,0) [0|16449.535] "kWh" Vector__XXX
 SG_ Hvesp13ChargeEnergyCapacity : 24|24@1+ (0.001,0) [0|16449.535] "kWh" Vector__XXX
 SG_ Hvsp13MxmmChrgVltgLmt : 48|16@1+ (0.05,0) [0|3212.75] "V" Vector__XXX

BO_ 2364700926 HVESP13MS1: 8 Vector__XXX
 SG_ Hvesp13Module1OperationalStatus : 0|2@1+ (1,0) [0|3] "" Vector__XXX
 SG_ Hvesp13Module2OperationalStatus : 2|2@1+ (1,0) [0|3] "" Vector__XXX
 SG_ Hvesp13Module3OperationalStatus : 4|2@1+ (1,0) [0|3] "" Vector__XXX
 SG_ Hvesp13Module4OperationalStatus : 6|2@1+ (1,0) [0|3] "" Vector__XXX
 SG_ Hvesp13Module5OperationalStatus : 8|2@1+ (1,0) [0|3] "" Vector__XXX
 SG_ Hvesp13Module6OperationalStatus : 10|2@1+ (1,0) [0|3] "" Vector__XXX
 SG_ Hvesp13Module7OperationalStatus : 12|2@1+ (1,0) [0|3] "" Vector__XXX
 SG_ Hvesp13Module8OperationalStatus : 14|2@1+ (1,0) [0|3] "" Vector__XXX
 SG_ Hvesp13Module9OperationalStatus : 16|2@1+ (1,0) [0|3] "" Vector__XXX
 SG_ Hvsp13Mdl10OprtnlStts : 18|2@1+ (1,0) [0|3] "" Vector__XXX
 SG_ Hvsp13Mdl11OprtnlStts : 20|2@1+ (1,0) [0|3] "" Vector__XXX
 SG_ Hvsp13Mdl12OprtnlStts : 22|2@1+ (1,0) [0|3] "" Vector__XXX
 SG_ Hvsp13Mdl13OprtnlStts : 24|2@1+ (1,0) [0|3] "" Vector__XXX
 SG_ Hvsp13Mdl14OprtnlStts : 26|2@1+ (1,0) [0|3] "" Vector__XXX
 SG_ Hvsp13Mdl15OprtnlStts : 28|2@1+ (1,0) [0|3] "" Vector__XXX
 SG_ Hvsp13Mdl16OprtnlStts : 30|2@1+ (1,0) [0|3] "" Vector__XXX
 SG_ Hvsp13Mdl17OprtnlStts : 32|2@1+ (1,0) [0|3] "" Vector__XXX
 SG_ Hvsp13Mdl18OprtnlStts : 34|2@1+ (1,0) [0|3] "" Vector__XXX
 SG_ Hvsp13Mdl19OprtnlStts : 36|2@1+ (1,0) [0|3] "" Vector__XXX
 SG_ Hvsp13Mdl20OprtnlStts : 38|2@1+ (1,0) [0|3] "" Vector__XXX
 SG_ Hvsp13Mdl21OprtnlStts : 40|2@1+ (1,0) [0|3] "" Vector__XXX
 SG_ Hvsp13Mdl22OprtnlStts : 42|2@1+ (1,0) [0|3] "" Vector__XXX
 SG_ Hvsp13Mdl23OprtnlStts : 44|2@1+ (1,0) [0|3] "" Vector__XXX
 SG_ Hvsp13Mdl24OprtnlStts : 46|2@1+ (1,0) [0|3] "" Vector__XXX
 SG_ Hvsp13Mdl25OprtnlStts : 48|2@1+ (1,0) [0|3] "" Vector__XXX
 SG_ Hvsp13Mdl26OprtnlStts : 50|2@1+ (1,0) [0|3] "" Vector__XXX
 SG_ Hvsp13Mdl27OprtnlStts : 52|2@1+ (1,0) [0|3] "" Vector__XXX
 SG_ Hvsp13Mdl28OprtnlStts : 54|2@1+ (1,0) [0|3] "" Vector__XXX
 SG_ Hvsp13Mdl29OprtnlStts : 56|2@1+ (1,0) [0|3] "" Vector__XXX
 SG_ Hvsp13Mdl30OprtnlStts : 58|2@1+ (1,0) [0|3] "" Vector__XXX
 SG_ Hvsp13Mdl31OprtnlStts : 60|2@1+ (1,0) [0|3] "" Vector__XXX
 SG_ Hvsp13Mdl32OprtnlStts : 62|2@1+ (1,0) [0|3] "" Vector__XXX

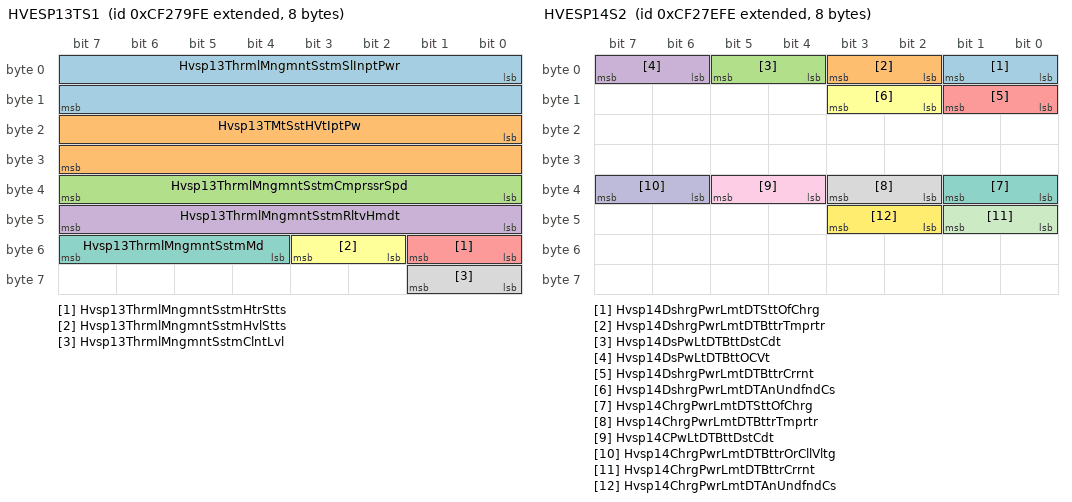
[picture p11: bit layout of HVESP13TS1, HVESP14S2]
BO_ 2364701182 HVESP13TS1: 8 Vector__XXX
 SG_ Hvsp13ThrmlMngmntSstmSlInptPwr : 0|16@1+ (0.5,0) [0|32127.5] "W" Vector__XXX
 SG_ Hvsp13TMtSstHVtIptPw : 16|16@1+ (0.5,0) [0|32127.5] "W" Vector__XXX
 SG_ Hvsp13ThrmlMngmntSstmCmprssrSpd : 32|8@1+ (32,0) [0|8000] "rpm" Vector__XXX
 SG_ Hvsp13ThrmlMngmntSstmRltvHmdt : 40|8@1+ (0.4,0) [0|100] "%" Vector__XXX
 SG_ Hvsp13ThrmlMngmntSstmHtrStts : 48|2@1+ (1,0) [0|3] "" Vector__XXX
 SG_ Hvsp13ThrmlMngmntSstmHvlStts : 50|2@1+ (1,0) [0|3] "" Vector__XXX
 SG_ Hvsp13ThrmlMngmntSstmMd : 52|4@1+ (1,0) [0|15] "" Vector__XXX
 SG_ Hvsp13ThrmlMngmntSstmClntLvl : 56|2@1+ (1,0) [0|3] "" Vector__XXX

BO_ 2364701438 HVESP13D8: 8 Vector__XXX
 SG_ Hvsp13HghstCllVltgMdlNmr : 0|8@1+ (1,0) [0|250] "count" Vector__XXX
 SG_ Hvsp13HghstCllVltgCllNmr : 8|8@1+ (1,0) [0|250] "count" Vector__XXX
 SG_ Hvsp13LwstCllVltgMdlNmr : 16|8@1+ (1,0) [0|250] "count" Vector__XXX
 SG_ Hvsp13LwstCllVltgCllNmr : 24|8@1+ (1,0) [0|250] "count" Vector__XXX
 SG_ Hvesp13AverageCellVoltage : 32|16@1+ (0.001,0) [0|64.255] "V" Vector__XXX

BO_ 2364701694 HVESP13D9: 8 Vector__XXX
 SG_ Hvsp13HghstCllTmprtrMdlNmr : 0|8@1+ (1,0) [0|250] "count" Vector__XXX
 SG_ Hvsp13HghstCllTmprtrCllNmr : 8|8@1+ (1,0) [0|250] "count" Vector__XXX
 SG_ Hvsp13LwstCllTmprtrMdlNmr : 16|8@1+ (1,0) [0|250] "count" Vector__XXX
 SG_ Hvsp13LwstCllTmprtrCllNmr : 24|8@1+ (1,0) [0|250] "count" Vector__XXX
 SG_ Hvess13ThermalEventDetected : 32|2@1+ (1,0) [0|3] "" Vector__XXX
 SG_ Hvsp13Dt9EmdddIntgrtSpprt : 50|2@1+ (1,0) [0|3] "" Vector__XXX
 SG_ Hvesp13Data9Counter : 52|4@1+ (1,0) [0|15] "" Vector__XXX
 SG_ Hvesp13Data9Crc : 56|8@1+ (1,0) [0|250] "count" Vector__XXX

BO_ 2364701950 HVESP13D10: 8 Vector__XXX
 SG_ Hvsp13HghstCllSttOfChrgMdlNmr : 0|8@1+ (1,0) [0|250] "count" Vector__XXX
 SG_ Hvsp13HghstCllSttOfChrgCllNmr : 8|8@1+ (1,0) [0|250] "count" Vector__XXX
 SG_ Hvsp13LwstCllSttOfChrgMdlNmr : 16|8@1+ (1,0) [0|250] "count" Vector__XXX
 SG_ Hvsp13LwstCllSttOfChrgCllNmr : 24|8@1+ (1,0) [0|250] "count" Vector__XXX
 SG_ Hvsp13HghVltgBsAtvIsltnTstRslts : 32|16@1+ (0.1,0) [0|6425.5] "OhmPerV" Vector__XXX
 SG_ Hvsp13HVtBsPssvIstTstRsts : 48|16@1+ (0.1,0) [0|6425.5] "OhmPerV" Vector__XXX

BO_ 2364702206 HVESP13D11: 8 Vector__XXX
 SG_ Hvsp13BsVltgNgtvTChsssGrndVltg : 0|16@1+ (0.05,0) [0|3212.75] "V" Vector__XXX
 SG_ Hvsp13VltgLvlNgtvTChsssGrndVltg : 16|16@1+ (0.05,0) [0|3212.75] "V" Vector__XXX
 SG_ Hvesp13ActualChargeRate : 32|16@1+ (0.05,0) [0|3212.75] "kW" Vector__XXX

BO_ 2364702462 HVESP14S2: 8 Vector__XXX
 SG_ Hvsp14DshrgPwrLmtDTSttOfChrg : 0|2@1+ (1,0) [0|3] "" Vector__XXX
 SG_ Hvsp14DshrgPwrLmtDTBttrTmprtr : 2|2@1+ (1,0) [0|3] "" Vector__XXX
 SG_ Hvsp14DsPwLtDTBttDstCdt : 4|2@1+ (1,0) [0|3] "" Vector__XXX
 SG_ Hvsp14DsPwLtDTBttOCVt : 6|2@1+ (1,0) [0|3] "" Vector__XXX
 SG_ Hvsp14DshrgPwrLmtDTBttrCrrnt : 8|2@1+ (1,0) [0|3] "" Vector__XXX
 SG_ Hvsp14DshrgPwrLmtDTAnUndfndCs : 10|2@1+ (1,0) [0|3] "" Vector__XXX
 SG_ Hvsp14ChrgPwrLmtDTSttOfChrg : 32|2@1+ (1,0) [0|3] "" Vector__XXX
 SG_ Hvsp14ChrgPwrLmtDTBttrTmprtr : 34|2@1+ (1,0) [0|3] "" Vector__XXX
 SG_ Hvsp14CPwLtDTBttDstCdt : 36|2@1+ (1,0) [0|3] "" Vector__XXX
 SG_ Hvsp14ChrgPwrLmtDTBttrOrCllVltg : 38|2@1+ (1,0) [0|3] "" Vector__XXX
 SG_ Hvsp14ChrgPwrLmtDTBttrCrrnt : 40|2@1+ (1,0) [0|3] "" Vector__XXX
 SG_ Hvsp14ChrgPwrLmtDTAnUndfndCs : 42|2@1+ (1,0) [0|3] "" Vector__XXX

BO_ 2364702718 HVESP14D1: 8 Vector__XXX
 SG_ Hvesp14AvailableDischargePower : 0|16@1+ (0.05,0) [0|3212.75] "kW" Vector__XXX
 SG_ Hvesp14AvailableChargePower : 16|16@1+ (0.05,0) [0|3212.75] "kW" Vector__XXX
 SG_ Hvesp14VoltageLevel : 32|16@1+ (0.05,0) [0|3212.75] "V" Vector__XXX
 SG_ Hvesp14Current : 48|16@1+ (0.05,-1600) [-1600|1612.75] "A" Vector__XXX

BO_ 2364702974 HVESP14D2: 8 Vector__XXX
 SG_ Hvesp14FastUpdateStateOfCharge : 0|16@1+ (0.0015625,0) [0|100.3984375] "%" Vector__XXX
 SG_ Hvesp14HighestCellVoltage : 16|16@1+ (0.001,0) [0|64.255] "V" Vector__XXX
 SG_ Hvesp14LowestCellVoltage : 32|16@1+ (0.001,0) [0|64.255] "V" Vector__XXX
 SG_ Hvsp14CllVltgDffrntlStts : 48|4@1+ (1,0) [0|15] "" Vector__XXX

BO_ 2364703230 HVESP14D3: 8 Vector__XXX
 SG_ Hvesp14HighestCellTemperature : 0|16@1+ (0.03125,-273) [-273|1734.96875] "degC" Vector__XXX
 SG_ Hvesp14LowestCellTemperature : 16|16@1+ (0.03125,-273) [-273|1734.96875] "degC" Vector__XXX
 SG_ Hvesp14AverageCellTemperature : 32|16@1+ (0.03125,-273) [-273|1734.96875] "degC" Vector__XXX
 SG_ Hvsp14CllTmprtrDffrntlStts : 48|2@1+ (1,0) [0|3] "" Vector__XXX

BO_ 2364703486 HVESP14D4: 8 Vector__XXX
 SG_ Hvesp14DischargeCapacity : 0|16@1+ (0.01,0) [0|642.55] "Ah" Vector__XXX
 SG_ Hvesp14ChargeCapacity : 16|16@1+ (0.01,0) [0|642.55] "Ah" Vector__XXX
 SG_ Hvesp14CellBalancingCount : 32|16@1+ (1,0) [0|64255] "count" Vector__XXX

BO_ 2364703742 HVESP14D5: 8 Vector__XXX
 SG_ Hvesp14LowestCellStateOfCharge : 32|16@1+ (0.0015625,0) [0|100.3984375] "%" Vector__XXX
 SG_ Hvesp14HighestCellStateOfCharge : 48|16@1+ (0.0015625,0) [0|100.3984375] "%" Vector__XXX
 SG_ Hvsp14MxmmInstntnsDshrgCrrntLmt : 0|16@1+ (0.05,-1600) [-1600|0] "A" Vector__XXX
 SG_ Hvsp14MxmmInstntnsChrgCrrntLmt : 16|16@1+ (0.05,-1600) [0|1612.75] "A" Vector__XXX

BO_ 2364703998 HVESP14D6: 8 Vector__XXX
 SG_ Hvesp14BusVoltage : 0|16@1+ (0.05,0) [0|3212.75] "V" Vector__XXX
 SG_ Hvesp14IgnitionVoltage : 16|16@1+ (0.01,0) [0|642.55] "V" Vector__XXX
 SG_ Hvesp14IntakeCoolantTemperature : 32|8@1+ (1,-40) [-40|210] "degC" Vector__XXX
 SG_ Hvesp14OutletCoolantTemperature : 40|8@1+ (1,-40) [-40|210] "degC" Vector__XXX
 SG_ Hvesp14ElectronicsTemperature : 48|8@1+ (1,-40) [-40|210] "degC" Vector__XXX
 SG_ Hvesp14Temperature : 56|8@1+ (1,-40) [-40|210] "degC" Vector__XXX

BO_ 2364704254 HVESP14S1: 8 Vector__XXX
 SG_ Hvsp14HghVltgBsPstvCnttrStt : 0|2@1+ (1,0) [0|3] "" Vector__XXX
 SG_ Hvsp14HghVltgBsNgtvCnttrStt : 2|2@1+ (1,0) [0|3] "" Vector__XXX
 SG_ Hvsp14HghVltgBsDsnntFrwrnng : 4|4@1+ (1,0) [0|15] "" Vector__XXX
 SG_ Hvsp14HghVltgBsPrChrgRlStt : 8|2@1+ (1,0) [0|3] "" Vector__XXX
 SG_ Hvsp14CntrOfPkCnttrStt : 10|2@1+ (1,0) [0|3] "" Vector__XXX
 SG_ Hvsp14HghVltgBsAtvIsltnTstStts : 12|4@1+ (1,0) [0|15] "" Vector__XXX
 SG_ Hvsp14HghVltgBsPssvIsltnTstStts : 16|4@1+ (1,0) [0|15] "" Vector__XXX
 SG_ Hvesp14HvilStatus : 20|2@1+ (1,0) [0|3] "" Vector__XXX
 SG_ Hvesp14InertiaSwitchStatus : 22|2@1+ (1,0) [0|3] "" Vector__XXX
 SG_ Hvesp14StateOfChargeStatus : 24|4@1+ (1,0) [0|15] "" Vector__XXX
 SG_ Hvesp14CellBalanceStatus : 28|2@1+ (1,0) [0|3] "" Vector__XXX
 SG_ Hvesp14CellBalancingActive : 30|2@1+ (1,0) [0|3] "" Vector__XXX
 SG_ Hvesp14InternalChargerStatus : 32|2@1+ (1,0) [0|3] "" Vector__XXX
 SG_ Hvsp14HghVltgBsCnntnStts : 40|4@1+ (1,0) [0|15] "" Vector__XXX
 SG_ Hvesp14OperationalStatus : 44|4@1+ (1,0) [0|15] "" Vector__XXX
 SG_ Hvesp14Status1Counter : 52|4@1+ (1,0) [0|15] "" Vector__XXX
 SG_ Hvesp14Status1Crc : 56|8@1+ (1,0) [0|250] "count" Vector__XXX

BO_ 2364704510 HVESP14D7: 8 Vector__XXX
 SG_ Hvesp14DischargeEnergyCapacity : 0|24@1+ (0.001,0) [0|16449.535] "kWh" Vector__XXX
 SG_ Hvesp14ChargeEnergyCapacity : 24|24@1+ (0.001,0) [0|16449.535] "kWh" Vector__XXX
 SG_ Hvsp14MxmmChrgVltgLmt : 48|16@1+ (0.05,0) [0|3212.75] "V" Vector__XXX

BO_ 2364704766 HVESP14MS1: 8 Vector__XXX
 SG_ Hvesp14Module1OperationalStatus : 0|2@1+ (1,0) [0|3] "" Vector__XXX
 SG_ Hvesp14Module2OperationalStatus : 2|2@1+ (1,0) [0|3] "" Vector__XXX
 SG_ Hvesp14Module3OperationalStatus : 4|2@1+ (1,0) [0|3] "" Vector__XXX
 SG_ Hvesp14Module4OperationalStatus : 6|2@1+ (1,0) [0|3] "" Vector__XXX
 SG_ Hvesp14Module5OperationalStatus : 8|2@1+ (1,0) [0|3] "" Vector__XXX
 SG_ Hvesp14Module6OperationalStatus : 10|2@1+ (1,0) [0|3] "" Vector__XXX
 SG_ Hvesp14Module7OperationalStatus : 12|2@1+ (1,0) [0|3] "" Vector__XXX
 SG_ Hvesp14Module8OperationalStatus : 14|2@1+ (1,0) [0|3] "" Vector__XXX
 SG_ Hvesp14Module9OperationalStatus : 16|2@1+ (1,0) [0|3] "" Vector__XXX
 SG_ Hvsp14Mdl10OprtnlStts : 18|2@1+ (1,0) [0|3] "" Vector__XXX
 SG_ Hvsp14Mdl11OprtnlStts : 20|2@1+ (1,0) [0|3] "" Vector__XXX
 SG_ Hvsp14Mdl12OprtnlStts : 22|2@1+ (1,0) [0|3] "" Vector__XXX
 SG_ Hvsp14Mdl13OprtnlStts : 24|2@1+ (1,0) [0|3] "" Vector__XXX
 SG_ Hvsp14Mdl14OprtnlStts : 26|2@1+ (1,0) [0|3] "" Vector__XXX
 SG_ Hvsp14Mdl15OprtnlStts : 28|2@1+ (1,0) [0|3] "" Vector__XXX
 SG_ Hvsp14Mdl16OprtnlStts : 30|2@1+ (1,0) [0|3] "" Vector__XXX
 SG_ Hvsp14Mdl17OprtnlStts : 32|2@1+ (1,0) [0|3] "" Vector__XXX
 SG_ Hvsp14Mdl18OprtnlStts : 34|2@1+ (1,0) [0|3] "" Vector__XXX
 SG_ Hvsp14Mdl19OprtnlStts : 36|2@1+ (1,0) [0|3] "" Vector__XXX
 SG_ Hvsp14Mdl20OprtnlStts : 38|2@1+ (1,0) [0|3] "" Vector__XXX
 SG_ Hvsp14Mdl21OprtnlStts : 40|2@1+ (1,0) [0|3] "" Vector__XXX
 SG_ Hvsp14Mdl22OprtnlStts : 42|2@1+ (1,0) [0|3] "" Vector__XXX
 SG_ Hvsp14Mdl23OprtnlStts : 44|2@1+ (1,0) [0|3] "" Vector__XXX
 SG_ Hvsp14Mdl24OprtnlStts : 46|2@1+ (1,0) [0|3] "" Vector__XXX
 SG_ Hvsp14Mdl25OprtnlStts : 48|2@1+ (1,0) [0|3] "" Vector__XXX
 SG_ Hvsp14Mdl26OprtnlStts : 50|2@1+ (1,0) [0|3] "" Vector__XXX
 SG_ Hvsp14Mdl27OprtnlStts : 52|2@1+ (1,0) [0|3] "" Vector__XXX
 SG_ Hvsp14Mdl28OprtnlStts : 54|2@1+ (1,0) [0|3] "" Vector__XXX
 SG_ Hvsp14Mdl29OprtnlStts : 56|2@1+ (1,0) [0|3] "" Vector__XXX
 SG_ Hvsp14Mdl30OprtnlStts : 58|2@1+ (1,0) [0|3] "" Vector__XXX
 SG_ Hvsp14Mdl31OprtnlStts : 60|2@1+ (1,0) [0|3] "" Vector__XXX
 SG_ Hvsp14Mdl32OprtnlStts : 62|2@1+ (1,0) [0|3] "" Vector__XXX

BO_ 2364705022 HVESP14TS1: 8 Vector__XXX
 SG_ Hvsp14ThrmlMngmntSstmSlInptPwr : 0|16@1+ (0.5,0) [0|32127.5] "W" Vector__XXX
 SG_ Hvsp14TMtSstHVtIptPw : 16|16@1+ (0.5,0) [0|32127.5] "W" Vector__XXX
 SG_ Hvsp14ThrmlMngmntSstmCmprssrSpd : 32|8@1+ (32,0) [0|8000] "rpm" Vector__XXX
 SG_ Hvsp14ThrmlMngmntSstmRltvHmdt : 40|8@1+ (0.4,0) [0|100] "%" Vector__XXX
 SG_ Hvsp14ThrmlMngmntSstmHtrStts : 48|2@1+ (1,0) [0|3] "" Vector__XXX
 SG_ Hvsp14ThrmlMngmntSstmHvlStts : 50|2@1+ (1,0) [0|3] "" Vector__XXX
 SG_ Hvsp14ThrmlMngmntSstmMd : 52|4@1+ (1,0) [0|15] "" Vector__XXX
 SG_ Hvsp14ThrmlMngmntSstmClntLvl : 56|2@1+ (1,0) [0|3] "" Vector__XXX

BO_ 2364705278 HVESP14D8: 8 Vector__XXX
 SG_ Hvsp14HghstCllVltgMdlNmr : 0|8@1+ (1,0) [0|250] "count" Vector__XXX
 SG_ Hvsp14HghstCllVltgCllNmr : 8|8@1+ (1,0) [0|250] "count" Vector__XXX
 SG_ Hvsp14LwstCllVltgMdlNmr : 16|8@1+ (1,0) [0|250] "count" Vector__XXX
 SG_ Hvsp14LwstCllVltgCllNmr : 24|8@1+ (1,0) [0|250] "count" Vector__XXX
 SG_ Hvesp14AverageCellVoltage : 32|16@1+ (0.001,0) [0|64.255] "V" Vector__XXX

BO_ 2364705534 HVESP14D9: 8 Vector__XXX
 SG_ Hvsp14HghstCllTmprtrMdlNmr : 0|8@1+ (1,0) [0|250] "count" Vector__XXX
 SG_ Hvsp14HghstCllTmprtrCllNmr : 8|8@1+ (1,0) [0|250] "count" Vector__XXX
 SG_ Hvsp14LwstCllTmprtrMdlNmr : 16|8@1+ (1,0) [0|250] "count" Vector__XXX
 SG_ Hvsp14LwstCllTmprtrCllNmr : 24|8@1+ (1,0) [0|250] "count" Vector__XXX
 SG_ Hvess14ThermalEventDetected : 32|2@1+ (1,0) [0|3] "" Vector__XXX
 SG_ Hvsp14Dt9EmdddIntgrtSpprt : 50|2@1+ (1,0) [0|3] "" Vector__XXX
 SG_ Hvesp14Data9Counter : 52|4@1+ (1,0) [0|15] "" Vector__XXX
 SG_ Hvesp14Data9Crc : 56|8@1+ (1,0) [0|250] "count" Vector__XXX

BO_ 2364705790 HVESP14D10: 8 Vector__XXX
 SG_ Hvsp14HghstCllSttOfChrgMdlNmr : 0|8@1+ (1,0) [0|250] "count" Vector__XXX
 SG_ Hvsp14HghstCllSttOfChrgCllNmr : 8|8@1+ (1,0) [0|250] "count" Vector__XXX
 SG_ Hvsp14LwstCllSttOfChrgMdlNmr : 16|8@1+ (1,0) [0|250] "count" Vector__XXX
 SG_ Hvsp14LwstCllSttOfChrgCllNmr : 24|8@1+ (1,0) [0|250] "count" Vector__XXX
 SG_ Hvsp14HghVltgBsAtvIsltnTstRslts : 32|16@1+ (0.1,0) [0|6425.5] "OhmPerV" Vector__XXX
 SG_ Hvsp14HVtBsPssvIstTstRsts : 48|16@1+ (0.1,0) [0|6425.5] "OhmPerV" Vector__XXX

BO_ 2364706046 HVESP14D11: 8 Vector__XXX
 SG_ Hvsp14BsVltgNgtvTChsssGrndVltg : 0|16@1+ (0.05,0) [0|3212.75] "V" Vector__XXX
 SG_ Hvsp14VltgLvlNgtvTChsssGrndVltg : 16|16@1+ (0.05,0) [0|3212.75] "V" Vector__XXX
 SG_ Hvesp14ActualChargeRate : 32|16@1+ (0.05,0) [0|3212.75] "kW" Vector__XXX

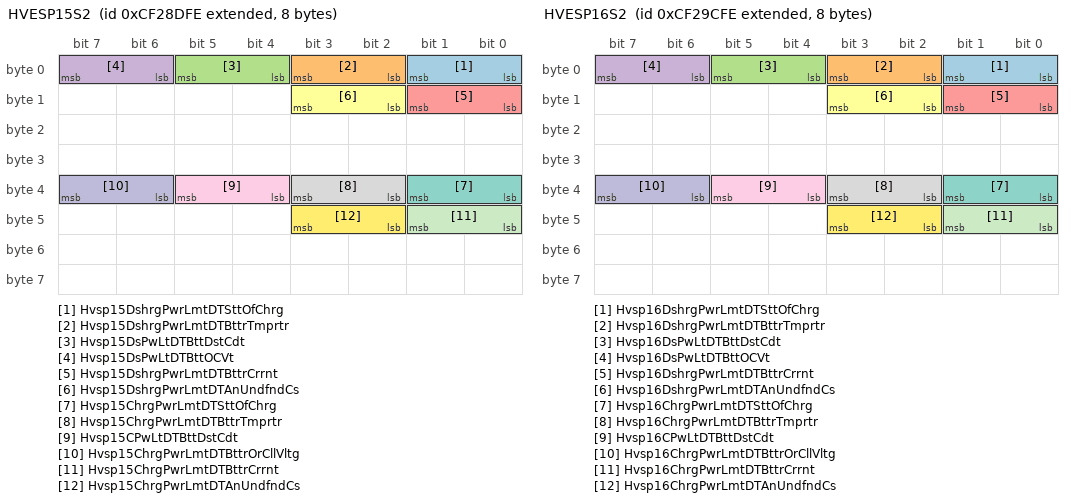
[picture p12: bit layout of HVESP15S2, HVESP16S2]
BO_ 2364706302 HVESP15S2: 8 Vector__XXX
 SG_ Hvsp15DshrgPwrLmtDTSttOfChrg : 0|2@1+ (1,0) [0|3] "" Vector__XXX
 SG_ Hvsp15DshrgPwrLmtDTBttrTmprtr : 2|2@1+ (1,0) [0|3] "" Vector__XXX
 SG_ Hvsp15DsPwLtDTBttDstCdt : 4|2@1+ (1,0) [0|3] "" Vector__XXX
 SG_ Hvsp15DsPwLtDTBttOCVt : 6|2@1+ (1,0) [0|3] "" Vector__XXX
 SG_ Hvsp15DshrgPwrLmtDTBttrCrrnt : 8|2@1+ (1,0) [0|3] "" Vector__XXX
 SG_ Hvsp15DshrgPwrLmtDTAnUndfndCs : 10|2@1+ (1,0) [0|3] "" Vector__XXX
 SG_ Hvsp15ChrgPwrLmtDTSttOfChrg : 32|2@1+ (1,0) [0|3] "" Vector__XXX
 SG_ Hvsp15ChrgPwrLmtDTBttrTmprtr : 34|2@1+ (1,0) [0|3] "" Vector__XXX
 SG_ Hvsp15CPwLtDTBttDstCdt : 36|2@1+ (1,0) [0|3] "" Vector__XXX
 SG_ Hvsp15ChrgPwrLmtDTBttrOrCllVltg : 38|2@1+ (1,0) [0|3] "" Vector__XXX
 SG_ Hvsp15ChrgPwrLmtDTBttrCrrnt : 40|2@1+ (1,0) [0|3] "" Vector__XXX
 SG_ Hvsp15ChrgPwrLmtDTAnUndfndCs : 42|2@1+ (1,0) [0|3] "" Vector__XXX

BO_ 2364706558 HVESP15D1: 8 Vector__XXX
 SG_ Hvesp15AvailableDischargePower : 0|16@1+ (0.05,0) [0|3212.75] "kW" Vector__XXX
 SG_ Hvesp15AvailableChargePower : 16|16@1+ (0.05,0) [0|3212.75] "kW" Vector__XXX
 SG_ Hvesp15VoltageLevel : 32|16@1+ (0.05,0) [0|3212.75] "V" Vector__XXX
 SG_ Hvesp15Current : 48|16@1+ (0.05,-1600) [-1600|1612.75] "A" Vector__XXX

BO_ 2364706814 HVESP15D2: 8 Vector__XXX
 SG_ Hvesp15FastUpdateStateOfCharge : 0|16@1+ (0.0015625,0) [0|100.3984375] "%" Vector__XXX
 SG_ Hvesp15HighestCellVoltage : 16|16@1+ (0.001,0) [0|64.255] "V" Vector__XXX
 SG_ Hvesp15LowestCellVoltage : 32|16@1+ (0.001,0) [0|64.255] "V" Vector__XXX
 SG_ Hvsp15CllVltgDffrntlStts : 48|4@1+ (1,0) [0|15] "" Vector__XXX

BO_ 2364707070 HVESP15D3: 8 Vector__XXX
 SG_ Hvesp15HighestCellTemperature : 0|16@1+ (0.03125,-273) [-273|1734.96875] "degC" Vector__XXX
 SG_ Hvesp15LowestCellTemperature : 16|16@1+ (0.03125,-273) [-273|1734.96875] "degC" Vector__XXX
 SG_ Hvesp15AverageCellTemperature : 32|16@1+ (0.03125,-273) [-273|1734.96875] "degC" Vector__XXX
 SG_ Hvsp15CllTmprtrDffrntlStts : 48|2@1+ (1,0) [0|3] "" Vector__XXX

BO_ 2364707326 HVESP15D4: 8 Vector__XXX
 SG_ Hvesp15DischargeCapacity : 0|16@1+ (0.01,0) [0|642.55] "Ah" Vector__XXX
 SG_ Hvesp15ChargeCapacity : 16|16@1+ (0.01,0) [0|642.55] "Ah" Vector__XXX
 SG_ Hvesp15CellBalancingCount : 32|16@1+ (1,0) [0|64255] "count" Vector__XXX

BO_ 2364707582 HVESP15D5: 8 Vector__XXX
 SG_ Hvesp15LowestCellStateOfCharge : 32|16@1+ (0.0015625,0) [0|100.3984375] "%" Vector__XXX
 SG_ Hvesp15HighestCellStateOfCharge : 48|16@1+ (0.0015625,0) [0|100.3984375] "%" Vector__XXX
 SG_ Hvsp15MxmmInstntnsDshrgCrrntLmt : 0|16@1+ (0.05,-1600) [-1600|0] "A" Vector__XXX
 SG_ Hvsp15MxmmInstntnsChrgCrrntLmt : 16|16@1+ (0.05,-1600) [0|1612.75] "A" Vector__XXX

BO_ 2364707838 HVESP15D6: 8 Vector__XXX
 SG_ Hvesp15BusVoltage : 0|16@1+ (0.05,0) [0|3212.75] "V" Vector__XXX
 SG_ Hvesp15IgnitionVoltage : 16|16@1+ (0.01,0) [0|642.55] "V" Vector__XXX
 SG_ Hvesp15IntakeCoolantTemperature : 32|8@1+ (1,-40) [-40|210] "degC" Vector__XXX
 SG_ Hvesp15OutletCoolantTemperature : 40|8@1+ (1,-40) [-40|210] "degC" Vector__XXX
 SG_ Hvesp15ElectronicsTemperature : 48|8@1+ (1,-40) [-40|210] "degC" Vector__XXX
 SG_ Hvesp15Temperature : 56|8@1+ (1,-40) [-40|210] "degC" Vector__XXX

BO_ 2364708094 HVESP15S1: 8 Vector__XXX
 SG_ Hvsp15HghVltgBsPstvCnttrStt : 0|2@1+ (1,0) [0|3] "" Vector__XXX
 SG_ Hvsp15HghVltgBsNgtvCnttrStt : 2|2@1+ (1,0) [0|3] "" Vector__XXX
 SG_ Hvsp15HghVltgBsDsnntFrwrnng : 4|4@1+ (1,0) [0|15] "" Vector__XXX
 SG_ Hvsp15HghVltgBsPrChrgRlStt : 8|2@1+ (1,0) [0|3] "" Vector__XXX
 SG_ Hvsp15CntrOfPkCnttrStt : 10|2@1+ (1,0) [0|3] "" Vector__XXX
 SG_ Hvsp15HghVltgBsAtvIsltnTstStts : 12|4@1+ (1,0) [0|15] "" Vector__XXX
 SG_ Hvsp15HghVltgBsPssvIsltnTstStts : 16|4@1+ (1,0) [0|15] "" Vector__XXX
 SG_ Hvesp15HvilStatus : 20|2@1+ (1,0) [0|3] "" Vector__XXX
 SG_ Hvesp15InertiaSwitchStatus : 22|2@1+ (1,0) [0|3] "" Vector__XXX
 SG_ Hvesp15StateOfChargeStatus : 24|4@1+ (1,0) [0|15] "" Vector__XXX
 SG_ Hvesp15CellBalanceStatus : 28|2@1+ (1,0) [0|3] "" Vector__XXX
 SG_ Hvesp15CellBalancingActive : 30|2@1+ (1,0) [0|3] "" Vector__XXX
 SG_ Hvesp15InternalChargerStatus : 32|2@1+ (1,0) [0|3] "" Vector__XXX
 SG_ Hvsp15HghVltgBsCnntnStts : 40|4@1+ (1,0) [0|15] "" Vector__XXX
 SG_ Hvesp15OperationalStatus : 44|4@1+ (1,0) [0|15] "" Vector__XXX
 SG_ Hvesp15Status1Counter : 52|4@1+ (1,0) [0|15] "" Vector__XXX
 SG_ Hvesp15Status1Crc : 56|8@1+ (1,0) [0|250] "count" Vector__XXX

BO_ 2364708350 HVESP15D7: 8 Vector__XXX
 SG_ Hvesp15DischargeEnergyCapacity : 0|24@1+ (0.001,0) [0|16449.535] "kWh" Vector__XXX
 SG_ Hvesp15ChargeEnergyCapacity : 24|24@1+ (0.001,0) [0|16449.535] "kWh" Vector__XXX
 SG_ Hvsp15MxmmChrgVltgLmt : 48|16@1+ (0.05,0) [0|3212.75] "V" Vector__XXX

BO_ 2364708606 HVESP15MS1: 8 Vector__XXX
 SG_ Hvesp15Module1OperationalStatus : 0|2@1+ (1,0) [0|3] "" Vector__XXX
 SG_ Hvesp15Module2OperationalStatus : 2|2@1+ (1,0) [0|3] "" Vector__XXX
 SG_ Hvesp15Module3OperationalStatus : 4|2@1+ (1,0) [0|3] "" Vector__XXX
 SG_ Hvesp15Module4OperationalStatus : 6|2@1+ (1,0) [0|3] "" Vector__XXX
 SG_ Hvesp15Module5OperationalStatus : 8|2@1+ (1,0) [0|3] "" Vector__XXX
 SG_ Hvesp15Module6OperationalStatus : 10|2@1+ (1,0) [0|3] "" Vector__XXX
 SG_ Hvesp15Module7OperationalStatus : 12|2@1+ (1,0) [0|3] "" Vector__XXX
 SG_ Hvesp15Module8OperationalStatus : 14|2@1+ (1,0) [0|3] "" Vector__XXX
 SG_ Hvesp15Module9OperationalStatus : 16|2@1+ (1,0) [0|3] "" Vector__XXX
 SG_ Hvsp15Mdl10OprtnlStts : 18|2@1+ (1,0) [0|3] "" Vector__XXX
 SG_ Hvsp15Mdl11OprtnlStts : 20|2@1+ (1,0) [0|3] "" Vector__XXX
 SG_ Hvsp15Mdl12OprtnlStts : 22|2@1+ (1,0) [0|3] "" Vector__XXX
 SG_ Hvsp15Mdl13OprtnlStts : 24|2@1+ (1,0) [0|3] "" Vector__XXX
 SG_ Hvsp15Mdl14OprtnlStts : 26|2@1+ (1,0) [0|3] "" Vector__XXX
 SG_ Hvsp15Mdl15OprtnlStts : 28|2@1+ (1,0) [0|3] "" Vector__XXX
 SG_ Hvsp15Mdl16OprtnlStts : 30|2@1+ (1,0) [0|3] "" Vector__XXX
 SG_ Hvsp15Mdl17OprtnlStts : 32|2@1+ (1,0) [0|3] "" Vector__XXX
 SG_ Hvsp15Mdl18OprtnlStts : 34|2@1+ (1,0) [0|3] "" Vector__XXX
 SG_ Hvsp15Mdl19OprtnlStts : 36|2@1+ (1,0) [0|3] "" Vector__XXX
 SG_ Hvsp15Mdl20OprtnlStts : 38|2@1+ (1,0) [0|3] "" Vector__XXX
 SG_ Hvsp15Mdl21OprtnlStts : 40|2@1+ (1,0) [0|3] "" Vector__XXX
 SG_ Hvsp15Mdl22OprtnlStts : 42|2@1+ (1,0) [0|3] "" Vector__XXX
 SG_ Hvsp15Mdl23OprtnlStts : 44|2@1+ (1,0) [0|3] "" Vector__XXX
 SG_ Hvsp15Mdl24OprtnlStts : 46|2@1+ (1,0) [0|3] "" Vector__XXX
 SG_ Hvsp15Mdl25OprtnlStts : 48|2@1+ (1,0) [0|3] "" Vector__XXX
 SG_ Hvsp15Mdl26OprtnlStts : 50|2@1+ (1,0) [0|3] "" Vector__XXX
 SG_ Hvsp15Mdl27OprtnlStts : 52|2@1+ (1,0) [0|3] "" Vector__XXX
 SG_ Hvsp15Mdl28OprtnlStts : 54|2@1+ (1,0) [0|3] "" Vector__XXX
 SG_ Hvsp15Mdl29OprtnlStts : 56|2@1+ (1,0) [0|3] "" Vector__XXX
 SG_ Hvsp15Mdl30OprtnlStts : 58|2@1+ (1,0) [0|3] "" Vector__XXX
 SG_ Hvsp15Mdl31OprtnlStts : 60|2@1+ (1,0) [0|3] "" Vector__XXX
 SG_ Hvsp15Mdl32OprtnlStts : 62|2@1+ (1,0) [0|3] "" Vector__XXX

BO_ 2364708862 HVESP15TS1: 8 Vector__XXX
 SG_ Hvsp15ThrmlMngmntSstmSlInptPwr : 0|16@1+ (0.5,0) [0|32127.5] "W" Vector__XXX
 SG_ Hvsp15TMtSstHVtIptPw : 16|16@1+ (0.5,0) [0|32127.5] "W" Vector__XXX
 SG_ Hvsp15ThrmlMngmntSstmCmprssrSpd : 32|8@1+ (32,0) [0|8000] "rpm" Vector__XXX
 SG_ Hvsp15ThrmlMngmntSstmRltvHmdt : 40|8@1+ (0.4,0) [0|100] "%" Vector__XXX
 SG_ Hvsp15ThrmlMngmntSstmHtrStts : 48|2@1+ (1,0) [0|3] "" Vector__XXX
 SG_ Hvsp15ThrmlMngmntSstmHvlStts : 50|2@1+ (1,0) [0|3] "" Vector__XXX
 SG_ Hvsp15ThrmlMngmntSstmMd : 52|4@1+ (1,0) [0|15] "" Vector__XXX
 SG_ Hvsp15ThrmlMngmntSstmClntLvl : 56|2@1+ (1,0) [0|3] "" Vector__XXX

BO_ 2364709118 HVESP15D8: 8 Vector__XXX
 SG_ Hvsp15HghstCllVltgMdlNmr : 0|8@1+ (1,0) [0|250] "count" Vector__XXX
 SG_ Hvsp15HghstCllVltgCllNmr : 8|8@1+ (1,0) [0|250] "count" Vector__XXX
 SG_ Hvsp15LwstCllVltgMdlNmr : 16|8@1+ (1,0) [0|250] "count" Vector__XXX
 SG_ Hvsp15LwstCllVltgCllNmr : 24|8@1+ (1,0) [0|250] "count" Vector__XXX
 SG_ Hvesp15AverageCellVoltage : 32|16@1+ (0.001,0) [0|64.255] "V" Vector__XXX

BO_ 2364709374 HVESP15D9: 8 Vector__XXX
 SG_ Hvsp15HghstCllTmprtrMdlNmr : 0|8@1+ (1,0) [0|250] "count" Vector__XXX
 SG_ Hvsp15HghstCllTmprtrCllNmr : 8|8@1+ (1,0) [0|250] "count" Vector__XXX
 SG_ Hvsp15LwstCllTmprtrMdlNmr : 16|8@1+ (1,0) [0|250] "count" Vector__XXX
 SG_ Hvsp15LwstCllTmprtrCllNmr : 24|8@1+ (1,0) [0|250] "count" Vector__XXX
 SG_ Hvess15ThermalEventDetected : 32|2@1+ (1,0) [0|3] "" Vector__XXX
 SG_ Hvsp15Dt9EmdddIntgrtSpprt : 50|2@1+ (1,0) [0|3] "" Vector__XXX
 SG_ Hvesp15Data9Counter : 52|4@1+ (1,0) [0|15] "" Vector__XXX
 SG_ Hvesp15Data9Crc : 56|8@1+ (1,0) [0|250] "count" Vector__XXX

BO_ 2364709630 HVESP15D10: 8 Vector__XXX
 SG_ Hvsp15HghstCllSttOfChrgMdlNmr : 0|8@1+ (1,0) [0|250] "count" Vector__XXX
 SG_ Hvsp15HghstCllSttOfChrgCllNmr : 8|8@1+ (1,0) [0|250] "count" Vector__XXX
 SG_ Hvsp15LwstCllSttOfChrgMdlNmr : 16|8@1+ (1,0) [0|250] "count" Vector__XXX
 SG_ Hvsp15LwstCllSttOfChrgCllNmr : 24|8@1+ (1,0) [0|250] "count" Vector__XXX
 SG_ Hvsp15HghVltgBsAtvIsltnTstRslts : 32|16@1+ (0.1,0) [0|6425.5] "OhmPerV" Vector__XXX
 SG_ Hvsp15HVtBsPssvIstTstRsts : 48|16@1+ (0.1,0) [0|6425.5] "OhmPerV" Vector__XXX

BO_ 2364709886 HVESP15D11: 8 Vector__XXX
 SG_ Hvsp15BsVltgNgtvTChsssGrndVltg : 0|16@1+ (0.05,0) [0|3212.75] "V" Vector__XXX
 SG_ Hvsp15VltgLvlNgtvTChsssGrndVltg : 16|16@1+ (0.05,0) [0|3212.75] "V" Vector__XXX
 SG_ Hvesp15ActualChargeRate : 32|16@1+ (0.05,0) [0|3212.75] "kW" Vector__XXX

BO_ 2364710142 HVESP16S2: 8 Vector__XXX
 SG_ Hvsp16DshrgPwrLmtDTSttOfChrg : 0|2@1+ (1,0) [0|3] "" Vector__XXX
 SG_ Hvsp16DshrgPwrLmtDTBttrTmprtr : 2|2@1+ (1,0) [0|3] "" Vector__XXX
 SG_ Hvsp16DsPwLtDTBttDstCdt : 4|2@1+ (1,0) [0|3] "" Vector__XXX
 SG_ Hvsp16DsPwLtDTBttOCVt : 6|2@1+ (1,0) [0|3] "" Vector__XXX
 SG_ Hvsp16DshrgPwrLmtDTBttrCrrnt : 8|2@1+ (1,0) [0|3] "" Vector__XXX
 SG_ Hvsp16DshrgPwrLmtDTAnUndfndCs : 10|2@1+ (1,0) [0|3] "" Vector__XXX
 SG_ Hvsp16ChrgPwrLmtDTSttOfChrg : 32|2@1+ (1,0) [0|3] "" Vector__XXX
 SG_ Hvsp16ChrgPwrLmtDTBttrTmprtr : 34|2@1+ (1,0) [0|3] "" Vector__XXX
 SG_ Hvsp16CPwLtDTBttDstCdt : 36|2@1+ (1,0) [0|3] "" Vector__XXX
 SG_ Hvsp16ChrgPwrLmtDTBttrOrCllVltg : 38|2@1+ (1,0) [0|3] "" Vector__XXX
 SG_ Hvsp16ChrgPwrLmtDTBttrCrrnt : 40|2@1+ (1,0) [0|3] "" Vector__XXX
 SG_ Hvsp16ChrgPwrLmtDTAnUndfndCs : 42|2@1+ (1,0) [0|3] "" Vector__XXX

BO_ 2364710398 HVESP16D1: 8 Vector__XXX
 SG_ Hvesp16AvailableDischargePower : 0|16@1+ (0.05,0) [0|3212.75] "kW" Vector__XXX
 SG_ Hvesp16AvailableChargePower : 16|16@1+ (0.05,0) [0|3212.75] "kW" Vector__XXX
 SG_ Hvesp16VoltageLevel : 32|16@1+ (0.05,0) [0|3212.75] "V" Vector__XXX
 SG_ Hvesp16Current : 48|16@1+ (0.05,-1600) [-1600|1612.75] "A" Vector__XXX

BO_ 2364710654 HVESP16D2: 8 Vector__XXX
 SG_ Hvesp16FastUpdateStateOfCharge : 0|16@1+ (0.0015625,0) [0|100.3984375] "%" Vector__XXX
 SG_ Hvesp16HighestCellVoltage : 16|16@1+ (0.001,0) [0|64.255] "V" Vector__XXX
 SG_ Hvesp16LowestCellVoltage : 32|16@1+ (0.001,0) [0|64.255] "V" Vector__XXX
 SG_ Hvsp16CllVltgDffrntlStts : 48|4@1+ (1,0) [0|15] "" Vector__XXX

BO_ 2364710910 HVESP16D3: 8 Vector__XXX
 SG_ Hvesp16HighestCellTemperature : 0|16@1+ (0.03125,-273) [-273|1734.96875] "degC" Vector__XXX
 SG_ Hvesp16LowestCellTemperature : 16|16@1+ (0.03125,-273) [-273|1734.96875] "degC" Vector__XXX
 SG_ Hvesp16AverageCellTemperature : 32|16@1+ (0.03125,-273) [-273|1734.96875] "degC" Vector__XXX
 SG_ Hvsp16CllTmprtrDffrntlStts : 48|2@1+ (1,0) [0|3] "" Vector__XXX

BO_ 2364711166 HVESP16D4: 8 Vector__XXX
 SG_ Hvesp16DischargeCapacity : 0|16@1+ (0.01,0) [0|642.55] "Ah" Vector__XXX
 SG_ Hvesp16ChargeCapacity : 16|16@1+ (0.01,0) [0|642.55] "Ah" Vector__XXX
 SG_ Hvesp16CellBalancingCount : 32|16@1+ (1,0) [0|64255] "count" Vector__XXX

BO_ 2364711422 HVESP16D5: 8 Vector__XXX
 SG_ Hvesp16LowestCellStateOfCharge : 32|16@1+ (0.0015625,0) [0|100.3984375] "%" Vector__XXX
 SG_ Hvesp16HighestCellStateOfCharge : 48|16@1+ (0.0015625,0) [0|100.3984375] "%" Vector__XXX
 SG_ Hvsp16MxmmInstntnsDshrgCrrntLmt : 0|16@1+ (0.05,-1600) [-1600|0] "A" Vector__XXX
 SG_ Hvsp16MxmmInstntnsChrgCrrntLmt : 16|16@1+ (0.05,-1600) [0|1612.75] "A" Vector__XXX

BO_ 2364711678 HVESP16D6: 8 Vector__XXX
 SG_ Hvesp16BusVoltage : 0|16@1+ (0.05,0) [0|3212.75] "V" Vector__XXX
 SG_ Hvesp16IgnitionVoltage : 16|16@1+ (0.01,0) [0|642.55] "V" Vector__XXX
 SG_ Hvesp16IntakeCoolantTemperature : 32|8@1+ (1,-40) [-40|210] "degC" Vector__XXX
 SG_ Hvesp16OutletCoolantTemperature : 40|8@1+ (1,-40) [-40|210] "degC" Vector__XXX
 SG_ Hvesp16ElectronicsTemperature : 48|8@1+ (1,-40) [-40|210] "degC" Vector__XXX
 SG_ Hvesp16Temperature : 56|8@1+ (1,-40) [-40|210] "degC" Vector__XXX

BO_ 2364711934 HVESP16S1: 8 Vector__XXX
 SG_ Hvsp16HghVltgBsPstvCnttrStt : 0|2@1+ (1,0) [0|3] "" Vector__XXX
 SG_ Hvsp16HghVltgBsNgtvCnttrStt : 2|2@1+ (1,0) [0|3] "" Vector__XXX
 SG_ Hvsp16HghVltgBsDsnntFrwrnng : 4|4@1+ (1,0) [0|15] "" Vector__XXX
 SG_ Hvsp16HghVltgBsPrChrgRlStt : 8|2@1+ (1,0) [0|3] "" Vector__XXX
 SG_ Hvsp16CntrOfPkCnttrStt : 10|2@1+ (1,0) [0|3] "" Vector__XXX
 SG_ Hvsp16HghVltgBsAtvIsltnTstStts : 12|4@1+ (1,0) [0|15] "" Vector__XXX
 SG_ Hvsp16HghVltgBsPssvIsltnTstStts : 16|4@1+ (1,0) [0|15] "" Vector__XXX
 SG_ Hvesp16HvilStatus : 20|2@1+ (1,0) [0|3] "" Vector__XXX
 SG_ Hvesp16InertiaSwitchStatus : 22|2@1+ (1,0) [0|3] "" Vector__XXX
 SG_ Hvesp16StateOfChargeStatus : 24|4@1+ (1,0) [0|15] "" Vector__XXX
 SG_ Hvesp16CellBalanceStatus : 28|2@1+ (1,0) [0|3] "" Vector__XXX
 SG_ Hvesp16CellBalancingActive : 30|2@1+ (1,0) [0|3] "" Vector__XXX
 SG_ Hvesp16InternalChargerStatus : 32|2@1+ (1,0) [0|3] "" Vector__XXX
 SG_ Hvsp16HghVltgBsCnntnStts : 40|4@1+ (1,0) [0|15] "" Vector__XXX
 SG_ Hvesp16OperationalStatus : 44|4@1+ (1,0) [0|15] "" Vector__XXX
 SG_ Hvesp16Status1Counter : 52|4@1+ (1,0) [0|15] "" Vector__XXX
 SG_ Hvesp16Status1Crc : 56|8@1+ (1,0) [0|250] "count" Vector__XXX

BO_ 2364712190 HVESP16D7: 8 Vector__XXX
 SG_ Hvesp16DischargeEnergyCapacity : 0|24@1+ (0.001,0) [0|16449.535] "kWh" Vector__XXX
 SG_ Hvesp16ChargeEnergyCapacity : 24|24@1+ (0.001,0) [0|16449.535] "kWh" Vector__XXX
 SG_ Hvsp16MxmmChrgVltgLmt : 48|16@1+ (0.05,0) [0|3212.75] "V" Vector__XXX

BO_ 2364712446 HVESP16MS1: 8 Vector__XXX
 SG_ Hvesp16Module1OperationalStatus : 0|2@1+ (1,0) [0|3] "" Vector__XXX
 SG_ Hvesp16Module2OperationalStatus : 2|2@1+ (1,0) [0|3] "" Vector__XXX
 SG_ Hvesp16Module3OperationalStatus : 4|2@1+ (1,0) [0|3] "" Vector__XXX
 SG_ Hvesp16Module4OperationalStatus : 6|2@1+ (1,0) [0|3] "" Vector__XXX
 SG_ Hvesp16Module5OperationalStatus : 8|2@1+ (1,0) [0|3] "" Vector__XXX
 SG_ Hvesp16Module6OperationalStatus : 10|2@1+ (1,0) [0|3] "" Vector__XXX
 SG_ Hvesp16Module7OperationalStatus : 12|2@1+ (1,0) [0|3] "" Vector__XXX
 SG_ Hvesp16Module8OperationalStatus : 14|2@1+ (1,0) [0|3] "" Vector__XXX
 SG_ Hvesp16Module9OperationalStatus : 16|2@1+ (1,0) [0|3] "" Vector__XXX
 SG_ Hvsp16Mdl10OprtnlStts : 18|2@1+ (1,0) [0|3] "" Vector__XXX
 SG_ Hvsp16Mdl11OprtnlStts : 20|2@1+ (1,0) [0|3] "" Vector__XXX
 SG_ Hvsp16Mdl12OprtnlStts : 22|2@1+ (1,0) [0|3] "" Vector__XXX
 SG_ Hvsp16Mdl13OprtnlStts : 24|2@1+ (1,0) [0|3] "" Vector__XXX
 SG_ Hvsp16Mdl14OprtnlStts : 26|2@1+ (1,0) [0|3] "" Vector__XXX
 SG_ Hvsp16Mdl15OprtnlStts : 28|2@1+ (1,0) [0|3] "" Vector__XXX
 SG_ Hvsp16Mdl16OprtnlStts : 30|2@1+ (1,0) [0|3] "" Vector__XXX
 SG_ Hvsp16Mdl17OprtnlStts : 32|2@1+ (1,0) [0|3] "" Vector__XXX
 SG_ Hvsp16Mdl18OprtnlStts : 34|2@1+ (1,0) [0|3] "" Vector__XXX
 SG_ Hvsp16Mdl19OprtnlStts : 36|2@1+ (1,0) [0|3] "" Vector__XXX
 SG_ Hvsp16Mdl20OprtnlStts : 38|2@1+ (1,0) [0|3] "" Vector__XXX
 SG_ Hvsp16Mdl21OprtnlStts : 40|2@1+ (1,0) [0|3] "" Vector__XXX
 SG_ Hvsp16Mdl22OprtnlStts : 42|2@1+ (1,0) [0|3] "" Vector__XXX
 SG_ Hvsp16Mdl23OprtnlStts : 44|2@1+ (1,0) [0|3] "" Vector__XXX
 SG_ Hvsp16Mdl24OprtnlStts : 46|2@1+ (1,0) [0|3] "" Vector__XXX
 SG_ Hvsp16Mdl25OprtnlStts : 48|2@1+ (1,0) [0|3] "" Vector__XXX
 SG_ Hvsp16Mdl26OprtnlStts : 50|2@1+ (1,0) [0|3] "" Vector__XXX
 SG_ Hvsp16Mdl27OprtnlStts : 52|2@1+ (1,0) [0|3] "" Vector__XXX
 SG_ Hvsp16Mdl28OprtnlStts : 54|2@1+ (1,0) [0|3] "" Vector__XXX
 SG_ Hvsp16Mdl29OprtnlStts : 56|2@1+ (1,0) [0|3] "" Vector__XXX
 SG_ Hvsp16Mdl30OprtnlStts : 58|2@1+ (1,0) [0|3] "" Vector__XXX
 SG_ Hvsp16Mdl31OprtnlStts : 60|2@1+ (1,0) [0|3] "" Vector__XXX
 SG_ Hvsp16Mdl32OprtnlStts : 62|2@1+ (1,0) [0|3] "" Vector__XXX

BO_ 2364712702 HVESP16TS1: 8 Vector__XXX
 SG_ Hvsp16ThrmlMngmntSstmSlInptPwr : 0|16@1+ (0.5,0) [0|32127.5] "W" Vector__XXX
 SG_ Hvsp16TMtSstHVtIptPw : 16|16@1+ (0.5,0) [0|32127.5] "W" Vector__XXX
 SG_ Hvsp16ThrmlMngmntSstmCmprssrSpd : 32|8@1+ (32,0) [0|8000] "rpm" Vector__XXX
 SG_ Hvsp16ThrmlMngmntSstmRltvHmdt : 40|8@1+ (0.4,0) [0|100] "%" Vector__XXX
 SG_ Hvsp16ThrmlMngmntSstmHtrStts : 48|2@1+ (1,0) [0|3] "" Vector__XXX
 SG_ Hvsp16ThrmlMngmntSstmHvlStts : 50|2@1+ (1,0) [0|3] "" Vector__XXX
 SG_ Hvsp16ThrmlMngmntSstmMd : 52|4@1+ (1,0) [0|15] "" Vector__XXX
 SG_ Hvsp16ThrmlMngmntSstmClntLvl : 56|2@1+ (1,0) [0|3] "" Vector__XXX

BO_ 2364712958 HVESP16D8: 8 Vector__XXX
 SG_ Hvsp16HghstCllVltgMdlNmr : 0|8@1+ (1,0) [0|250] "count" Vector__XXX
 SG_ Hvsp16HghstCllVltgCllNmr : 8|8@1+ (1,0) [0|250] "count" Vector__XXX
 SG_ Hvsp16LwstCllVltgMdlNmr : 16|8@1+ (1,0) [0|250] "count" Vector__XXX
 SG_ Hvsp16LwstCllVltgCllNmr : 24|8@1+ (1,0) [0|250] "count" Vector__XXX
 SG_ Hvesp16AverageCellVoltage : 32|16@1+ (0.001,0) [0|64.255] "V" Vector__XXX

BO_ 2364713214 HVESP16D9: 8 Vector__XXX
 SG_ Hvsp16HghstCllTmprtrMdlNmr : 0|8@1+ (1,0) [0|250] "count" Vector__XXX
 SG_ Hvsp16HghstCllTmprtrCllNmr : 8|8@1+ (1,0) [0|250] "count" Vector__XXX
 SG_ Hvsp16LwstCllTmprtrMdlNmr : 16|8@1+ (1,0) [0|250] "count" Vector__XXX
 SG_ Hvsp16LwstCllTmprtrCllNmr : 24|8@1+ (1,0) [0|250] "count" Vector__XXX
 SG_ Hvess16ThermalEventDetected : 32|2@1+ (1,0) [0|3] "" Vector__XXX
 SG_ Hvsp16Dt9EmdddIntgrtSpprt : 50|2@1+ (1,0) [0|3] "" Vector__XXX
 SG_ Hvesp16Data9Counter : 52|4@1+ (1,0) [0|15] "" Vector__XXX
 SG_ Hvesp16Data9Crc : 56|8@1+ (1,0) [0|250] "count" Vector__XXX

BO_ 2364713470 HVESP16D10: 8 Vector__XXX
 SG_ Hvsp16HghstCllSttOfChrgMdlNmr : 0|8@1+ (1,0) [0|250] "count" Vector__XXX
 SG_ Hvsp16HghstCllSttOfChrgCllNmr : 8|8@1+ (1,0) [0|250] "count" Vector__XXX
 SG_ Hvsp16LwstCllSttOfChrgMdlNmr : 16|8@1+ (1,0) [0|250] "count" Vector__XXX
 SG_ Hvsp16LwstCllSttOfChrgCllNmr : 24|8@1+ (1,0) [0|250] "count" Vector__XXX
 SG_ Hvsp16HghVltgBsAtvIsltnTstRslts : 32|16@1+ (0.1,0) [0|6425.5] "OhmPerV" Vector__XXX
 SG_ Hvsp16HVtBsPssvIstTstRsts : 48|16@1+ (0.1,0) [0|6425.5] "OhmPerV" Vector__XXX

BO_ 2364713726 HVESP16D11: 8 Vector__XXX
 SG_ Hvsp16BsVltgNgtvTChsssGrndVltg : 0|16@1+ (0.05,0) [0|3212.75] "V" Vector__XXX
 SG_ Hvsp16VltgLvlNgtvTChsssGrndVltg : 16|16@1+ (0.05,0) [0|3212.75] "V" Vector__XXX
 SG_ Hvesp16ActualChargeRate : 32|16@1+ (0.05,0) [0|3212.75] "kW" Vector__XXX

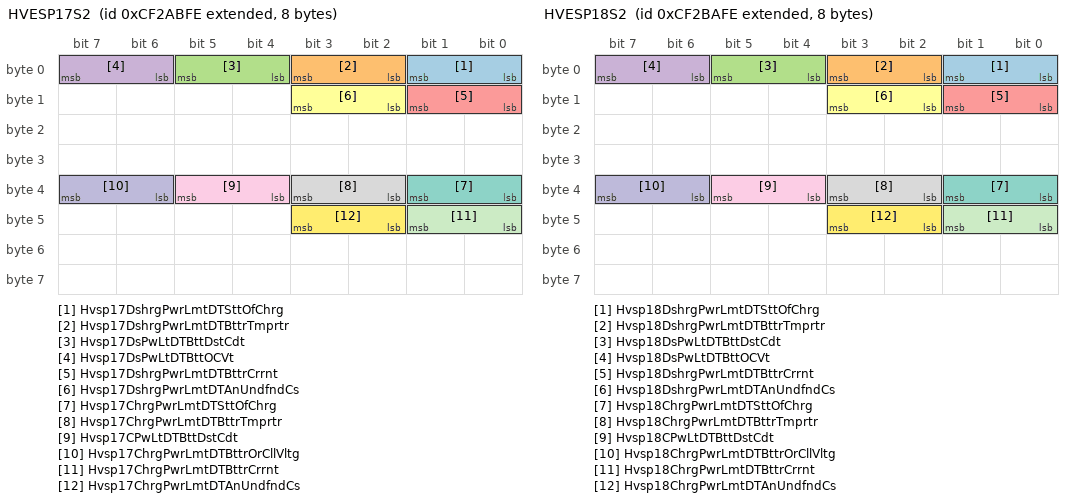
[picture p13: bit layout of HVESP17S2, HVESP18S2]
BO_ 2364713982 HVESP17S2: 8 Vector__XXX
 SG_ Hvsp17DshrgPwrLmtDTSttOfChrg : 0|2@1+ (1,0) [0|3] "" Vector__XXX
 SG_ Hvsp17DshrgPwrLmtDTBttrTmprtr : 2|2@1+ (1,0) [0|3] "" Vector__XXX
 SG_ Hvsp17DsPwLtDTBttDstCdt : 4|2@1+ (1,0) [0|3] "" Vector__XXX
 SG_ Hvsp17DsPwLtDTBttOCVt : 6|2@1+ (1,0) [0|3] "" Vector__XXX
 SG_ Hvsp17DshrgPwrLmtDTBttrCrrnt : 8|2@1+ (1,0) [0|3] "" Vector__XXX
 SG_ Hvsp17DshrgPwrLmtDTAnUndfndCs : 10|2@1+ (1,0) [0|3] "" Vector__XXX
 SG_ Hvsp17ChrgPwrLmtDTSttOfChrg : 32|2@1+ (1,0) [0|3] "" Vector__XXX
 SG_ Hvsp17ChrgPwrLmtDTBttrTmprtr : 34|2@1+ (1,0) [0|3] "" Vector__XXX
 SG_ Hvsp17CPwLtDTBttDstCdt : 36|2@1+ (1,0) [0|3] "" Vector__XXX
 SG_ Hvsp17ChrgPwrLmtDTBttrOrCllVltg : 38|2@1+ (1,0) [0|3] "" Vector__XXX
 SG_ Hvsp17ChrgPwrLmtDTBttrCrrnt : 40|2@1+ (1,0) [0|3] "" Vector__XXX
 SG_ Hvsp17ChrgPwrLmtDTAnUndfndCs : 42|2@1+ (1,0) [0|3] "" Vector__XXX

BO_ 2364714238 HVESP17D1: 8 Vector__XXX
 SG_ Hvesp17AvailableDischargePower : 0|16@1+ (0.05,0) [0|3212.75] "kW" Vector__XXX
 SG_ Hvesp17AvailableChargePower : 16|16@1+ (0.05,0) [0|3212.75] "kW" Vector__XXX
 SG_ Hvesp17VoltageLevel : 32|16@1+ (0.05,0) [0|3212.75] "V" Vector__XXX
 SG_ Hvesp17Current : 48|16@1+ (0.05,-1600) [-1600|1612.75] "A" Vector__XXX

BO_ 2364714494 HVESP17D2: 8 Vector__XXX
 SG_ Hvesp17FastUpdateStateOfCharge : 0|16@1+ (0.0015625,0) [0|100.3984375] "%" Vector__XXX
 SG_ Hvesp17HighestCellVoltage : 16|16@1+ (0.001,0) [0|64.255] "V" Vector__XXX
 SG_ Hvesp17LowestCellVoltage : 32|16@1+ (0.001,0) [0|64.255] "V" Vector__XXX
 SG_ Hvsp17CllVltgDffrntlStts : 48|4@1+ (1,0) [0|15] "" Vector__XXX

BO_ 2364714750 HVESP17D3: 8 Vector__XXX
 SG_ Hvesp17HighestCellTemperature : 0|16@1+ (0.03125,-273) [-273|1734.96875] "degC" Vector__XXX
 SG_ Hvesp17LowestCellTemperature : 16|16@1+ (0.03125,-273) [-273|1734.96875] "degC" Vector__XXX
 SG_ Hvesp17AverageCellTemperature : 32|16@1+ (0.03125,-273) [-273|1734.96875] "degC" Vector__XXX
 SG_ Hvsp17CllTmprtrDffrntlStts : 48|2@1+ (1,0) [0|3] "" Vector__XXX

BO_ 2364715006 HVESP17D4: 8 Vector__XXX
 SG_ Hvesp17DischargeCapacity : 0|16@1+ (0.01,0) [0|642.55] "Ah" Vector__XXX
 SG_ Hvesp17ChargeCapacity : 16|16@1+ (0.01,0) [0|642.55] "Ah" Vector__XXX
 SG_ Hvesp17CellBalancingCount : 32|16@1+ (1,0) [0|64255] "count" Vector__XXX

BO_ 2364715262 HVESP17D5: 8 Vector__XXX
 SG_ Hvesp17LowestCellStateOfCharge : 32|16@1+ (0.0015625,0) [0|100.3984375] "%" Vector__XXX
 SG_ Hvesp17HighestCellStateOfCharge : 48|16@1+ (0.0015625,0) [0|100.3984375] "%" Vector__XXX
 SG_ Hvsp17MxmmInstntnsDshrgCrrntLmt : 0|16@1+ (0.05,-1600) [-1600|0] "A" Vector__XXX
 SG_ Hvsp17MxmmInstntnsChrgCrrntLmt : 16|16@1+ (0.05,-1600) [0|1612.75] "A" Vector__XXX

BO_ 2364715518 HVESP17D6: 8 Vector__XXX
 SG_ Hvesp17BusVoltage : 0|16@1+ (0.05,0) [0|3212.75] "V" Vector__XXX
 SG_ Hvesp17IgnitionVoltage : 16|16@1+ (0.01,0) [0|642.55] "V" Vector__XXX
 SG_ Hvesp17IntakeCoolantTemperature : 32|8@1+ (1,-40) [-40|210] "degC" Vector__XXX
 SG_ Hvesp17OutletCoolantTemperature : 40|8@1+ (1,-40) [-40|210] "degC" Vector__XXX
 SG_ Hvesp17ElectronicsTemperature : 48|8@1+ (1,-40) [-40|210] "degC" Vector__XXX
 SG_ Hvesp17Temperature : 56|8@1+ (1,-40) [-40|210] "degC" Vector__XXX

BO_ 2364715774 HVESP17S1: 8 Vector__XXX
 SG_ Hvsp17HghVltgBsPstvCnttrStt : 0|2@1+ (1,0) [0|3] "" Vector__XXX
 SG_ Hvsp17HghVltgBsNgtvCnttrStt : 2|2@1+ (1,0) [0|3] "" Vector__XXX
 SG_ Hvsp17HghVltgBsDsnntFrwrnng : 4|4@1+ (1,0) [0|15] "" Vector__XXX
 SG_ Hvsp17HghVltgBsPrChrgRlStt : 8|2@1+ (1,0) [0|3] "" Vector__XXX
 SG_ Hvsp17CntrOfPkCnttrStt : 10|2@1+ (1,0) [0|3] "" Vector__XXX
 SG_ Hvsp17HghVltgBsAtvIsltnTstStts : 12|4@1+ (1,0) [0|15] "" Vector__XXX
 SG_ Hvsp17HghVltgBsPssvIsltnTstStts : 16|4@1+ (1,0) [0|15] "" Vector__XXX
 SG_ Hvesp17HvilStatus : 20|2@1+ (1,0) [0|3] "" Vector__XXX
 SG_ Hvesp17InertiaSwitchStatus : 22|2@1+ (1,0) [0|3] "" Vector__XXX
 SG_ Hvesp17StateOfChargeStatus : 24|4@1+ (1,0) [0|15] "" Vector__XXX
 SG_ Hvesp17CellBalanceStatus : 28|2@1+ (1,0) [0|3] "" Vector__XXX
 SG_ Hvesp17CellBalancingActive : 30|2@1+ (1,0) [0|3] "" Vector__XXX
 SG_ Hvesp17InternalChargerStatus : 32|2@1+ (1,0) [0|3] "" Vector__XXX
 SG_ Hvsp17HghVltgBsCnntnStts : 40|4@1+ (1,0) [0|15] "" Vector__XXX
 SG_ Hvesp17OperationalStatus : 44|4@1+ (1,0) [0|15] "" Vector__XXX
 SG_ Hvesp17Status1Counter : 52|4@1+ (1,0) [0|15] "" Vector__XXX
 SG_ Hvesp17Status1Crc : 56|8@1+ (1,0) [0|250] "count" Vector__XXX

BO_ 2364716030 HVESP17D7: 8 Vector__XXX
 SG_ Hvesp17DischargeEnergyCapacity : 0|24@1+ (0.001,0) [0|16449.535] "kWh" Vector__XXX
 SG_ Hvesp17ChargeEnergyCapacity : 24|24@1+ (0.001,0) [0|16449.535] "kWh" Vector__XXX
 SG_ Hvsp17MxmmChrgVltgLmt : 48|16@1+ (0.05,0) [0|3212.75] "V" Vector__XXX

BO_ 2364716286 HVESP17MS1: 8 Vector__XXX
 SG_ Hvesp17Module1OperationalStatus : 0|2@1+ (1,0) [0|3] "" Vector__XXX
 SG_ Hvesp17Module2OperationalStatus : 2|2@1+ (1,0) [0|3] "" Vector__XXX
 SG_ Hvesp17Module3OperationalStatus : 4|2@1+ (1,0) [0|3] "" Vector__XXX
 SG_ Hvesp17Module4OperationalStatus : 6|2@1+ (1,0) [0|3] "" Vector__XXX
 SG_ Hvesp17Module5OperationalStatus : 8|2@1+ (1,0) [0|3] "" Vector__XXX
 SG_ Hvesp17Module6OperationalStatus : 10|2@1+ (1,0) [0|3] "" Vector__XXX
 SG_ Hvesp17Module7OperationalStatus : 12|2@1+ (1,0) [0|3] "" Vector__XXX
 SG_ Hvesp17Module8OperationalStatus : 14|2@1+ (1,0) [0|3] "" Vector__XXX
 SG_ Hvesp17Module9OperationalStatus : 16|2@1+ (1,0) [0|3] "" Vector__XXX
 SG_ Hvsp17Mdl10OprtnlStts : 18|2@1+ (1,0) [0|3] "" Vector__XXX
 SG_ Hvsp17Mdl11OprtnlStts : 20|2@1+ (1,0) [0|3] "" Vector__XXX
 SG_ Hvsp17Mdl12OprtnlStts : 22|2@1+ (1,0) [0|3] "" Vector__XXX
 SG_ Hvsp17Mdl13OprtnlStts : 24|2@1+ (1,0) [0|3] "" Vector__XXX
 SG_ Hvsp17Mdl14OprtnlStts : 26|2@1+ (1,0) [0|3] "" Vector__XXX
 SG_ Hvsp17Mdl15OprtnlStts : 28|2@1+ (1,0) [0|3] "" Vector__XXX
 SG_ Hvsp17Mdl16OprtnlStts : 30|2@1+ (1,0) [0|3] "" Vector__XXX
 SG_ Hvsp17Mdl17OprtnlStts : 32|2@1+ (1,0) [0|3] "" Vector__XXX
 SG_ Hvsp17Mdl18OprtnlStts : 34|2@1+ (1,0) [0|3] "" Vector__XXX
 SG_ Hvsp17Mdl19OprtnlStts : 36|2@1+ (1,0) [0|3] "" Vector__XXX
 SG_ Hvsp17Mdl20OprtnlStts : 38|2@1+ (1,0) [0|3] "" Vector__XXX
 SG_ Hvsp17Mdl21OprtnlStts : 40|2@1+ (1,0) [0|3] "" Vector__XXX
 SG_ Hvsp17Mdl22OprtnlStts : 42|2@1+ (1,0) [0|3] "" Vector__XXX
 SG_ Hvsp17Mdl23OprtnlStts : 44|2@1+ (1,0) [0|3] "" Vector__XXX
 SG_ Hvsp17Mdl24OprtnlStts : 46|2@1+ (1,0) [0|3] "" Vector__XXX
 SG_ Hvsp17Mdl25OprtnlStts : 48|2@1+ (1,0) [0|3] "" Vector__XXX
 SG_ Hvsp17Mdl26OprtnlStts : 50|2@1+ (1,0) [0|3] "" Vector__XXX
 SG_ Hvsp17Mdl27OprtnlStts : 52|2@1+ (1,0) [0|3] "" Vector__XXX
 SG_ Hvsp17Mdl28OprtnlStts : 54|2@1+ (1,0) [0|3] "" Vector__XXX
 SG_ Hvsp17Mdl29OprtnlStts : 56|2@1+ (1,0) [0|3] "" Vector__XXX
 SG_ Hvsp17Mdl30OprtnlStts : 58|2@1+ (1,0) [0|3] "" Vector__XXX
 SG_ Hvsp17Mdl31OprtnlStts : 60|2@1+ (1,0) [0|3] "" Vector__XXX
 SG_ Hvsp17Mdl32OprtnlStts : 62|2@1+ (1,0) [0|3] "" Vector__XXX

BO_ 2364716542 HVESP17TS1: 8 Vector__XXX
 SG_ Hvsp17ThrmlMngmntSstmSlInptPwr : 0|16@1+ (0.5,0) [0|32127.5] "W" Vector__XXX
 SG_ Hvsp17TMtSstHVtIptPw : 16|16@1+ (0.5,0) [0|32127.5] "W" Vector__XXX
 SG_ Hvsp17ThrmlMngmntSstmCmprssrSpd : 32|8@1+ (32,0) [0|8000] "rpm" Vector__XXX
 SG_ Hvsp17ThrmlMngmntSstmRltvHmdt : 40|8@1+ (0.4,0) [0|100] "%" Vector__XXX
 SG_ Hvsp17ThrmlMngmntSstmHtrStts : 48|2@1+ (1,0) [0|3] "" Vector__XXX
 SG_ Hvsp17ThrmlMngmntSstmHvlStts : 50|2@1+ (1,0) [0|3] "" Vector__XXX
 SG_ Hvsp17ThrmlMngmntSstmMd : 52|4@1+ (1,0) [0|15] "" Vector__XXX
 SG_ Hvsp17ThrmlMngmntSstmClntLvl : 56|2@1+ (1,0) [0|3] "" Vector__XXX

BO_ 2364716798 HVESP17D8: 8 Vector__XXX
 SG_ Hvsp17HghstCllVltgMdlNmr : 0|8@1+ (1,0) [0|250] "count" Vector__XXX
 SG_ Hvsp17HghstCllVltgCllNmr : 8|8@1+ (1,0) [0|250] "count" Vector__XXX
 SG_ Hvsp17LwstCllVltgMdlNmr : 16|8@1+ (1,0) [0|250] "count" Vector__XXX
 SG_ Hvsp17LwstCllVltgCllNmr : 24|8@1+ (1,0) [0|250] "count" Vector__XXX
 SG_ Hvesp17AverageCellVoltage : 32|16@1+ (0.001,0) [0|64.255] "V" Vector__XXX

BO_ 2364717054 HVESP17D9: 8 Vector__XXX
 SG_ Hvsp17HghstCllTmprtrMdlNmr : 0|8@1+ (1,0) [0|250] "count" Vector__XXX
 SG_ Hvsp17HghstCllTmprtrCllNmr : 8|8@1+ (1,0) [0|250] "count" Vector__XXX
 SG_ Hvsp17LwstCllTmprtrMdlNmr : 16|8@1+ (1,0) [0|250] "count" Vector__XXX
 SG_ Hvsp17LwstCllTmprtrCllNmr : 24|8@1+ (1,0) [0|250] "count" Vector__XXX
 SG_ Hvess17ThermalEventDetected : 32|2@1+ (1,0) [0|3] "" Vector__XXX
 SG_ Hvsp17Dt9EmdddIntgrtSpprt : 50|2@1+ (1,0) [0|3] "" Vector__XXX
 SG_ Hvesp17Data9Counter : 52|4@1+ (1,0) [0|15] "" Vector__XXX
 SG_ Hvesp17Data9Crc : 56|8@1+ (1,0) [0|250] "count" Vector__XXX

BO_ 2364717310 HVESP17D10: 8 Vector__XXX
 SG_ Hvsp17HghstCllSttOfChrgMdlNmr : 0|8@1+ (1,0) [0|250] "count" Vector__XXX
 SG_ Hvsp17HghstCllSttOfChrgCllNmr : 8|8@1+ (1,0) [0|250] "count" Vector__XXX
 SG_ Hvsp17LwstCllSttOfChrgMdlNmr : 16|8@1+ (1,0) [0|250] "count" Vector__XXX
 SG_ Hvsp17LwstCllSttOfChrgCllNmr : 24|8@1+ (1,0) [0|250] "count" Vector__XXX
 SG_ Hvsp17HghVltgBsAtvIsltnTstRslts : 32|16@1+ (0.1,0) [0|6425.5] "OhmPerV" Vector__XXX
 SG_ Hvsp17HVtBsPssvIstTstRsts : 48|16@1+ (0.1,0) [0|6425.5] "OhmPerV" Vector__XXX

BO_ 2364717566 HVESP17D11: 8 Vector__XXX
 SG_ Hvsp17BsVltgNgtvTChsssGrndVltg : 0|16@1+ (0.05,0) [0|3212.75] "V" Vector__XXX
 SG_ Hvsp17VltgLvlNgtvTChsssGrndVltg : 16|16@1+ (0.05,0) [0|3212.75] "V" Vector__XXX
 SG_ Hvesp17ActualChargeRate : 32|16@1+ (0.05,0) [0|3212.75] "kW" Vector__XXX

BO_ 2364717822 HVESP18S2: 8 Vector__XXX
 SG_ Hvsp18DshrgPwrLmtDTSttOfChrg : 0|2@1+ (1,0) [0|3] "" Vector__XXX
 SG_ Hvsp18DshrgPwrLmtDTBttrTmprtr : 2|2@1+ (1,0) [0|3] "" Vector__XXX
 SG_ Hvsp18DsPwLtDTBttDstCdt : 4|2@1+ (1,0) [0|3] "" Vector__XXX
 SG_ Hvsp18DsPwLtDTBttOCVt : 6|2@1+ (1,0) [0|3] "" Vector__XXX
 SG_ Hvsp18DshrgPwrLmtDTBttrCrrnt : 8|2@1+ (1,0) [0|3] "" Vector__XXX
 SG_ Hvsp18DshrgPwrLmtDTAnUndfndCs : 10|2@1+ (1,0) [0|3] "" Vector__XXX
 SG_ Hvsp18ChrgPwrLmtDTSttOfChrg : 32|2@1+ (1,0) [0|3] "" Vector__XXX
 SG_ Hvsp18ChrgPwrLmtDTBttrTmprtr : 34|2@1+ (1,0) [0|3] "" Vector__XXX
 SG_ Hvsp18CPwLtDTBttDstCdt : 36|2@1+ (1,0) [0|3] "" Vector__XXX
 SG_ Hvsp18ChrgPwrLmtDTBttrOrCllVltg : 38|2@1+ (1,0) [0|3] "" Vector__XXX
 SG_ Hvsp18ChrgPwrLmtDTBttrCrrnt : 40|2@1+ (1,0) [0|3] "" Vector__XXX
 SG_ Hvsp18ChrgPwrLmtDTAnUndfndCs : 42|2@1+ (1,0) [0|3] "" Vector__XXX

BO_ 2364718078 HVESP18D1: 8 Vector__XXX
 SG_ Hvesp18AvailableDischargePower : 0|16@1+ (0.05,0) [0|3212.75] "kW" Vector__XXX
 SG_ Hvesp18AvailableChargePower : 16|16@1+ (0.05,0) [0|3212.75] "kW" Vector__XXX
 SG_ Hvesp18VoltageLevel : 32|16@1+ (0.05,0) [0|3212.75] "V" Vector__XXX
 SG_ Hvesp18Current : 48|16@1+ (0.05,-1600) [-1600|1612.75] "A" Vector__XXX

BO_ 2364718334 HVESP18D2: 8 Vector__XXX
 SG_ Hvesp18FastUpdateStateOfCharge : 0|16@1+ (0.0015625,0) [0|100.3984375] "%" Vector__XXX
 SG_ Hvesp18HighestCellVoltage : 16|16@1+ (0.001,0) [0|64.255] "V" Vector__XXX
 SG_ Hvesp18LowestCellVoltage : 32|16@1+ (0.001,0) [0|64.255] "V" Vector__XXX
 SG_ Hvsp18CllVltgDffrntlStts : 48|4@1+ (1,0) [0|15] "" Vector__XXX

BO_ 2364718590 HVESP18D3: 8 Vector__XXX
 SG_ Hvesp18HighestCellTemperature : 0|16@1+ (0.03125,-273) [-273|1734.96875] "degC" Vector__XXX
 SG_ Hvesp18LowestCellTemperature : 16|16@1+ (0.03125,-273) [-273|1734.96875] "degC" Vector__XXX
 SG_ Hvesp18AverageCellTemperature : 32|16@1+ (0.03125,-273) [-273|1734.96875] "degC" Vector__XXX
 SG_ Hvsp18CllTmprtrDffrntlStts : 48|2@1+ (1,0) [0|3] "" Vector__XXX

BO_ 2364718846 HVESP18D4: 8 Vector__XXX
 SG_ Hvesp18DischargeCapacity : 0|16@1+ (0.01,0) [0|642.55] "Ah" Vector__XXX
 SG_ Hvesp18ChargeCapacity : 16|16@1+ (0.01,0) [0|642.55] "Ah" Vector__XXX
 SG_ Hvesp18CellBalancingCount : 32|16@1+ (1,0) [0|64255] "count" Vector__XXX

BO_ 2364719102 HVESP18D5: 8 Vector__XXX
 SG_ Hvesp18LowestCellStateOfCharge : 32|16@1+ (0.0015625,0) [0|100.3984375] "%" Vector__XXX
 SG_ Hvesp18HighestCellStateOfCharge : 48|16@1+ (0.0015625,0) [0|100.3984375] "%" Vector__XXX
 SG_ Hvsp18MxmmInstntnsDshrgCrrntLmt : 0|16@1+ (0.05,-1600) [-1600|0] "A" Vector__XXX
 SG_ Hvsp18MxmmInstntnsChrgCrrntLmt : 16|16@1+ (0.05,-1600) [0|1612.75] "A" Vector__XXX

BO_ 2364719358 HVESP18D6: 8 Vector__XXX
 SG_ Hvesp18BusVoltage : 0|16@1+ (0.05,0) [0|3212.75] "V" Vector__XXX
 SG_ Hvesp18IgnitionVoltage : 16|16@1+ (0.01,0) [0|642.55] "V" Vector__XXX
 SG_ Hvesp18IntakeCoolantTemperature : 32|8@1+ (1,-40) [-40|210] "degC" Vector__XXX
 SG_ Hvesp18OutletCoolantTemperature : 40|8@1+ (1,-40) [-40|210] "degC" Vector__XXX
 SG_ Hvesp18ElectronicsTemperature : 48|8@1+ (1,-40) [-40|210] "degC" Vector__XXX
 SG_ Hvesp18Temperature : 56|8@1+ (1,-40) [-40|210] "degC" Vector__XXX

BO_ 2364719614 HVESP18S1: 8 Vector__XXX
 SG_ Hvsp18HghVltgBsPstvCnttrStt : 0|2@1+ (1,0) [0|3] "" Vector__XXX
 SG_ Hvsp18HghVltgBsNgtvCnttrStt : 2|2@1+ (1,0) [0|3] "" Vector__XXX
 SG_ Hvsp18HghVltgBsDsnntFrwrnng : 4|4@1+ (1,0) [0|15] "" Vector__XXX
 SG_ Hvsp18HghVltgBsPrChrgRlStt : 8|2@1+ (1,0) [0|3] "" Vector__XXX
 SG_ Hvsp18CntrOfPkCnttrStt : 10|2@1+ (1,0) [0|3] "" Vector__XXX
 SG_ Hvsp18HghVltgBsAtvIsltnTstStts : 12|4@1+ (1,0) [0|15] "" Vector__XXX
 SG_ Hvsp18HghVltgBsPssvIsltnTstStts : 16|4@1+ (1,0) [0|15] "" Vector__XXX
 SG_ Hvesp18HvilStatus : 20|2@1+ (1,0) [0|3] "" Vector__XXX
 SG_ Hvesp18InertiaSwitchStatus : 22|2@1+ (1,0) [0|3] "" Vector__XXX
 SG_ Hvesp18StateOfChargeStatus : 24|4@1+ (1,0) [0|15] "" Vector__XXX
 SG_ Hvesp18CellBalanceStatus : 28|2@1+ (1,0) [0|3] "" Vector__XXX
 SG_ Hvesp18CellBalancingActive : 30|2@1+ (1,0) [0|3] "" Vector__XXX
 SG_ Hvesp18InternalChargerStatus : 32|2@1+ (1,0) [0|3] "" Vector__XXX
 SG_ Hvsp18HghVltgBsCnntnStts : 40|4@1+ (1,0) [0|15] "" Vector__XXX
 SG_ Hvesp18OperationalStatus : 44|4@1+ (1,0) [0|15] "" Vector__XXX
 SG_ Hvesp18Status1Counter : 52|4@1+ (1,0) [0|15] "" Vector__XXX
 SG_ Hvesp18Status1Crc : 56|8@1+ (1,0) [0|250] "count" Vector__XXX

BO_ 2364719870 HVESP18D7: 8 Vector__XXX
 SG_ Hvesp18DischargeEnergyCapacity : 0|24@1+ (0.001,0) [0|16449.535] "kWh" Vector__XXX
 SG_ Hvesp18ChargeEnergyCapacity : 24|24@1+ (0.001,0) [0|16449.535] "kWh" Vector__XXX
 SG_ Hvsp18MxmmChrgVltgLmt : 48|16@1+ (0.05,0) [0|3212.75] "V" Vector__XXX

BO_ 2364720126 HVESP18MS1: 8 Vector__XXX
 SG_ Hvesp18Module1OperationalStatus : 0|2@1+ (1,0) [0|3] "" Vector__XXX
 SG_ Hvesp18Module2OperationalStatus : 2|2@1+ (1,0) [0|3] "" Vector__XXX
 SG_ Hvesp18Module3OperationalStatus : 4|2@1+ (1,0) [0|3] "" Vector__XXX
 SG_ Hvesp18Module4OperationalStatus : 6|2@1+ (1,0) [0|3] "" Vector__XXX
 SG_ Hvesp18Module5OperationalStatus : 8|2@1+ (1,0) [0|3] "" Vector__XXX
 SG_ Hvesp18Module6OperationalStatus : 10|2@1+ (1,0) [0|3] "" Vector__XXX
 SG_ Hvesp18Module7OperationalStatus : 12|2@1+ (1,0) [0|3] "" Vector__XXX
 SG_ Hvesp18Module8OperationalStatus : 14|2@1+ (1,0) [0|3] "" Vector__XXX
 SG_ Hvesp18Module9OperationalStatus : 16|2@1+ (1,0) [0|3] "" Vector__XXX
 SG_ Hvsp18Mdl10OprtnlStts : 18|2@1+ (1,0) [0|3] "" Vector__XXX
 SG_ Hvsp18Mdl11OprtnlStts : 20|2@1+ (1,0) [0|3] "" Vector__XXX
 SG_ Hvsp18Mdl12OprtnlStts : 22|2@1+ (1,0) [0|3] "" Vector__XXX
 SG_ Hvsp18Mdl13OprtnlStts : 24|2@1+ (1,0) [0|3] "" Vector__XXX
 SG_ Hvsp18Mdl14OprtnlStts : 26|2@1+ (1,0) [0|3] "" Vector__XXX
 SG_ Hvsp18Mdl15OprtnlStts : 28|2@1+ (1,0) [0|3] "" Vector__XXX
 SG_ Hvsp18Mdl16OprtnlStts : 30|2@1+ (1,0) [0|3] "" Vector__XXX
 SG_ Hvsp18Mdl17OprtnlStts : 32|2@1+ (1,0) [0|3] "" Vector__XXX
 SG_ Hvsp18Mdl18OprtnlStts : 34|2@1+ (1,0) [0|3] "" Vector__XXX
 SG_ Hvsp18Mdl19OprtnlStts : 36|2@1+ (1,0) [0|3] "" Vector__XXX
 SG_ Hvsp18Mdl20OprtnlStts : 38|2@1+ (1,0) [0|3] "" Vector__XXX
 SG_ Hvsp18Mdl21OprtnlStts : 40|2@1+ (1,0) [0|3] "" Vector__XXX
 SG_ Hvsp18Mdl22OprtnlStts : 42|2@1+ (1,0) [0|3] "" Vector__XXX
 SG_ Hvsp18Mdl23OprtnlStts : 44|2@1+ (1,0) [0|3] "" Vector__XXX
 SG_ Hvsp18Mdl24OprtnlStts : 46|2@1+ (1,0) [0|3] "" Vector__XXX
 SG_ Hvsp18Mdl25OprtnlStts : 48|2@1+ (1,0) [0|3] "" Vector__XXX
 SG_ Hvsp18Mdl26OprtnlStts : 50|2@1+ (1,0) [0|3] "" Vector__XXX
 SG_ Hvsp18Mdl27OprtnlStts : 52|2@1+ (1,0) [0|3] "" Vector__XXX
 SG_ Hvsp18Mdl28OprtnlStts : 54|2@1+ (1,0) [0|3] "" Vector__XXX
 SG_ Hvsp18Mdl29OprtnlStts : 56|2@1+ (1,0) [0|3] "" Vector__XXX
 SG_ Hvsp18Mdl30OprtnlStts : 58|2@1+ (1,0) [0|3] "" Vector__XXX
 SG_ Hvsp18Mdl31OprtnlStts : 60|2@1+ (1,0) [0|3] "" Vector__XXX
 SG_ Hvsp18Mdl32OprtnlStts : 62|2@1+ (1,0) [0|3] "" Vector__XXX

BO_ 2364720382 HVESP18TS1: 8 Vector__XXX
 SG_ Hvsp18ThrmlMngmntSstmSlInptPwr : 0|16@1+ (0.5,0) [0|32127.5] "W" Vector__XXX
 SG_ Hvsp18TMtSstHVtIptPw : 16|16@1+ (0.5,0) [0|32127.5] "W" Vector__XXX
 SG_ Hvsp18ThrmlMngmntSstmCmprssrSpd : 32|8@1+ (32,0) [0|8000] "rpm" Vector__XXX
 SG_ Hvsp18ThrmlMngmntSstmRltvHmdt : 40|8@1+ (0.4,0) [0|100] "%" Vector__XXX
 SG_ Hvsp18ThrmlMngmntSstmHtrStts : 48|2@1+ (1,0) [0|3] "" Vector__XXX
 SG_ Hvsp18ThrmlMngmntSstmHvlStts : 50|2@1+ (1,0) [0|3] "" Vector__XXX
 SG_ Hvsp18ThrmlMngmntSstmMd : 52|4@1+ (1,0) [0|15] "" Vector__XXX
 SG_ Hvsp18ThrmlMngmntSstmClntLvl : 56|2@1+ (1,0) [0|3] "" Vector__XXX

BO_ 2364720638 HVESP18D8: 8 Vector__XXX
 SG_ Hvsp18HghstCllVltgMdlNmr : 0|8@1+ (1,0) [0|250] "count" Vector__XXX
 SG_ Hvsp18HghstCllVltgCllNmr : 8|8@1+ (1,0) [0|250] "count" Vector__XXX
 SG_ Hvsp18LwstCllVltgMdlNmr : 16|8@1+ (1,0) [0|250] "count" Vector__XXX
 SG_ Hvsp18LwstCllVltgCllNmr : 24|8@1+ (1,0) [0|250] "count" Vector__XXX
 SG_ Hvesp18AverageCellVoltage : 32|16@1+ (0.001,0) [0|64.255] "V" Vector__XXX

BO_ 2364720894 HVESP18D9: 8 Vector__XXX
 SG_ Hvsp18HghstCllTmprtrMdlNmr : 0|8@1+ (1,0) [0|250] "count" Vector__XXX
 SG_ Hvsp18HghstCllTmprtrCllNmr : 8|8@1+ (1,0) [0|250] "count" Vector__XXX
 SG_ Hvsp18LwstCllTmprtrMdlNmr : 16|8@1+ (1,0) [0|250] "count" Vector__XXX
 SG_ Hvsp18LwstCllTmprtrCllNmr : 24|8@1+ (1,0) [0|250] "count" Vector__XXX
 SG_ Hvess18ThermalEventDetected : 32|2@1+ (1,0) [0|3] "" Vector__XXX
 SG_ Hvsp18Dt9EmdddIntgrtSpprt : 50|2@1+ (1,0) [0|3] "" Vector__XXX
 SG_ Hvesp18Data9Counter : 52|4@1+ (1,0) [0|15] "" Vector__XXX
 SG_ Hvesp18Data9Crc : 56|8@1+ (1,0) [0|250] "count" Vector__XXX

BO_ 2364721150 HVESP18D10: 8 Vector__XXX
 SG_ Hvsp18HghstCllSttOfChrgMdlNmr : 0|8@1+ (1,0) [0|250] "count" Vector__XXX
 SG_ Hvsp18HghstCllSttOfChrgCllNmr : 8|8@1+ (1,0) [0|250] "count" Vector__XXX
 SG_ Hvsp18LwstCllSttOfChrgMdlNmr : 16|8@1+ (1,0) [0|250] "count" Vector__XXX
 SG_ Hvsp18LwstCllSttOfChrgCllNmr : 24|8@1+ (1,0) [0|250] "count" Vector__XXX
 SG_ Hvsp18HghVltgBsAtvIsltnTstRslts : 32|16@1+ (0.1,0) [0|6425.5] "OhmPerV" Vector__XXX
 SG_ Hvsp18HVtBsPssvIstTstRsts : 48|16@1+ (0.1,0) [0|6425.5] "OhmPerV" Vector__XXX

BO_ 2364721406 HVESP18D11: 8 Vector__XXX
 SG_ Hvsp18BsVltgNgtvTChsssGrndVltg : 0|16@1+ (0.05,0) [0|3212.75] "V" Vector__XXX
 SG_ Hvsp18VltgLvlNgtvTChsssGrndVltg : 16|16@1+ (0.05,0) [0|3212.75] "V" Vector__XXX
 SG_ Hvesp18ActualChargeRate : 32|16@1+ (0.05,0) [0|3212.75] "kW" Vector__XXX

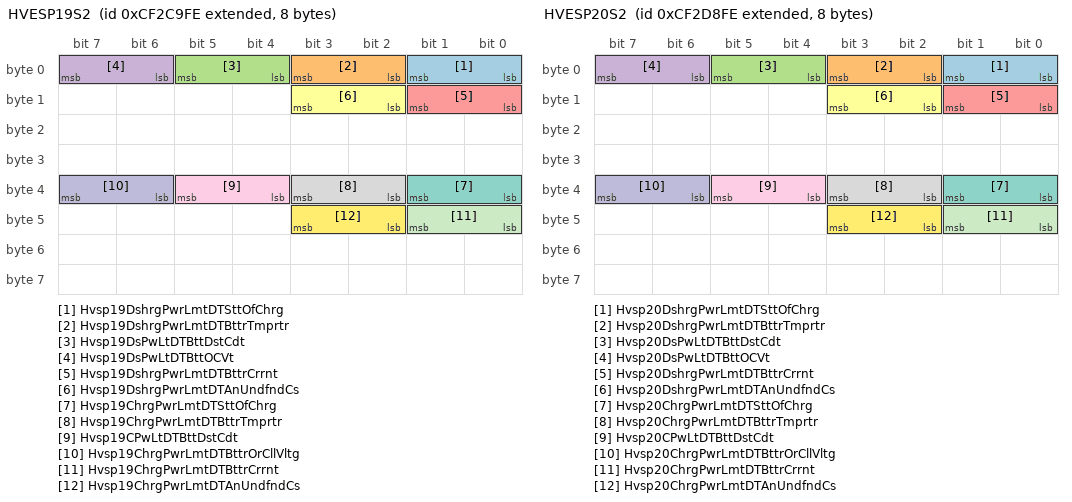
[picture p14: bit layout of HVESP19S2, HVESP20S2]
BO_ 2364721662 HVESP19S2: 8 Vector__XXX
 SG_ Hvsp19DshrgPwrLmtDTSttOfChrg : 0|2@1+ (1,0) [0|3] "" Vector__XXX
 SG_ Hvsp19DshrgPwrLmtDTBttrTmprtr : 2|2@1+ (1,0) [0|3] "" Vector__XXX
 SG_ Hvsp19DsPwLtDTBttDstCdt : 4|2@1+ (1,0) [0|3] "" Vector__XXX
 SG_ Hvsp19DsPwLtDTBttOCVt : 6|2@1+ (1,0) [0|3] "" Vector__XXX
 SG_ Hvsp19DshrgPwrLmtDTBttrCrrnt : 8|2@1+ (1,0) [0|3] "" Vector__XXX
 SG_ Hvsp19DshrgPwrLmtDTAnUndfndCs : 10|2@1+ (1,0) [0|3] "" Vector__XXX
 SG_ Hvsp19ChrgPwrLmtDTSttOfChrg : 32|2@1+ (1,0) [0|3] "" Vector__XXX
 SG_ Hvsp19ChrgPwrLmtDTBttrTmprtr : 34|2@1+ (1,0) [0|3] "" Vector__XXX
 SG_ Hvsp19CPwLtDTBttDstCdt : 36|2@1+ (1,0) [0|3] "" Vector__XXX
 SG_ Hvsp19ChrgPwrLmtDTBttrOrCllVltg : 38|2@1+ (1,0) [0|3] "" Vector__XXX
 SG_ Hvsp19ChrgPwrLmtDTBttrCrrnt : 40|2@1+ (1,0) [0|3] "" Vector__XXX
 SG_ Hvsp19ChrgPwrLmtDTAnUndfndCs : 42|2@1+ (1,0) [0|3] "" Vector__XXX

BO_ 2364721918 HVESP19D1: 8 Vector__XXX
 SG_ Hvesp19AvailableDischargePower : 0|16@1+ (0.05,0) [0|3212.75] "kW" Vector__XXX
 SG_ Hvesp19AvailableChargePower : 16|16@1+ (0.05,0) [0|3212.75] "kW" Vector__XXX
 SG_ Hvesp19VoltageLevel : 32|16@1+ (0.05,0) [0|3212.75] "V" Vector__XXX
 SG_ Hvesp19Current : 48|16@1+ (0.05,-1600) [-1600|1612.75] "A" Vector__XXX

BO_ 2364722174 HVESP19D2: 8 Vector__XXX
 SG_ Hvesp19FastUpdateStateOfCharge : 0|16@1+ (0.0015625,0) [0|100.3984375] "%" Vector__XXX
 SG_ Hvesp19HighestCellVoltage : 16|16@1+ (0.001,0) [0|64.255] "V" Vector__XXX
 SG_ Hvesp19LowestCellVoltage : 32|16@1+ (0.001,0) [0|64.255] "V" Vector__XXX
 SG_ Hvsp19CllVltgDffrntlStts : 48|4@1+ (1,0) [0|15] "" Vector__XXX

BO_ 2364722430 HVESP19D3: 8 Vector__XXX
 SG_ Hvesp19HighestCellTemperature : 0|16@1+ (0.03125,-273) [-273|1734.96875] "degC" Vector__XXX
 SG_ Hvesp19LowestCellTemperature : 16|16@1+ (0.03125,-273) [-273|1734.96875] "degC" Vector__XXX
 SG_ Hvesp19AverageCellTemperature : 32|16@1+ (0.03125,-273) [-273|1734.96875] "degC" Vector__XXX
 SG_ Hvsp19CllTmprtrDffrntlStts : 48|2@1+ (1,0) [0|3] "" Vector__XXX

BO_ 2364722686 HVESP19D4: 8 Vector__XXX
 SG_ Hvesp19DischargeCapacity : 0|16@1+ (0.01,0) [0|642.55] "Ah" Vector__XXX
 SG_ Hvesp19ChargeCapacity : 16|16@1+ (0.01,0) [0|642.55] "Ah" Vector__XXX
 SG_ Hvesp19CellBalancingCount : 32|16@1+ (1,0) [0|64255] "count" Vector__XXX

BO_ 2364722942 HVESP19D5: 8 Vector__XXX
 SG_ Hvesp19LowestCellStateOfCharge : 32|16@1+ (0.0015625,0) [0|100.3984375] "%" Vector__XXX
 SG_ Hvesp19HighestCellStateOfCharge : 48|16@1+ (0.0015625,0) [0|100.3984375] "%" Vector__XXX
 SG_ Hvsp19MxmmInstntnsDshrgCrrntLmt : 0|16@1+ (0.05,-1600) [-1600|0] "A" Vector__XXX
 SG_ Hvsp19MxmmInstntnsChrgCrrntLmt : 16|16@1+ (0.05,-1600) [0|1612.75] "A" Vector__XXX

BO_ 2364723198 HVESP19D6: 8 Vector__XXX
 SG_ Hvesp19BusVoltage : 0|16@1+ (0.05,0) [0|3212.75] "V" Vector__XXX
 SG_ Hvesp19IgnitionVoltage : 16|16@1+ (0.01,0) [0|642.55] "V" Vector__XXX
 SG_ Hvesp19IntakeCoolantTemperature : 32|8@1+ (1,-40) [-40|210] "degC" Vector__XXX
 SG_ Hvesp19OutletCoolantTemperature : 40|8@1+ (1,-40) [-40|210] "degC" Vector__XXX
 SG_ Hvesp19ElectronicsTemperature : 48|8@1+ (1,-40) [-40|210] "degC" Vector__XXX
 SG_ Hvesp19Temperature : 56|8@1+ (1,-40) [-40|210] "degC" Vector__XXX

BO_ 2364723454 HVESP19S1: 8 Vector__XXX
 SG_ Hvsp19HghVltgBsPstvCnttrStt : 0|2@1+ (1,0) [0|3] "" Vector__XXX
 SG_ Hvsp19HghVltgBsNgtvCnttrStt : 2|2@1+ (1,0) [0|3] "" Vector__XXX
 SG_ Hvsp19HghVltgBsDsnntFrwrnng : 4|4@1+ (1,0) [0|15] "" Vector__XXX
 SG_ Hvsp19HghVltgBsPrChrgRlStt : 8|2@1+ (1,0) [0|3] "" Vector__XXX
 SG_ Hvsp19CntrOfPkCnttrStt : 10|2@1+ (1,0) [0|3] "" Vector__XXX
 SG_ Hvsp19HghVltgBsAtvIsltnTstStts : 12|4@1+ (1,0) [0|15] "" Vector__XXX
 SG_ Hvsp19HghVltgBsPssvIsltnTstStts : 16|4@1+ (1,0) [0|15] "" Vector__XXX
 SG_ Hvesp19HvilStatus : 20|2@1+ (1,0) [0|3] "" Vector__XXX
 SG_ Hvesp19InertiaSwitchStatus : 22|2@1+ (1,0) [0|3] "" Vector__XXX
 SG_ Hvesp19StateOfChargeStatus : 24|4@1+ (1,0) [0|15] "" Vector__XXX
 SG_ Hvesp19CellBalanceStatus : 28|2@1+ (1,0) [0|3] "" Vector__XXX
 SG_ Hvesp19CellBalancingActive : 30|2@1+ (1,0) [0|3] "" Vector__XXX
 SG_ Hvesp19InternalChargerStatus : 32|2@1+ (1,0) [0|3] "" Vector__XXX
 SG_ Hvsp19HghVltgBsCnntnStts : 40|4@1+ (1,0) [0|15] "" Vector__XXX
 SG_ Hvesp19OperationalStatus : 44|4@1+ (1,0) [0|15] "" Vector__XXX
 SG_ Hvesp19Status1Counter : 52|4@1+ (1,0) [0|15] "" Vector__XXX
 SG_ Hvesp19Status1Crc : 56|8@1+ (1,0) [0|250] "count" Vector__XXX

BO_ 2364723710 HVESP19D7: 8 Vector__XXX
 SG_ Hvesp19DischargeEnergyCapacity : 0|24@1+ (0.001,0) [0|16449.535] "kWh" Vector__XXX
 SG_ Hvesp19ChargeEnergyCapacity : 24|24@1+ (0.001,0) [0|16449.535] "kWh" Vector__XXX
 SG_ Hvsp19MxmmChrgVltgLmt : 48|16@1+ (0.05,0) [0|3212.75] "V" Vector__XXX

BO_ 2364723966 HVESP19MS1: 8 Vector__XXX
 SG_ Hvesp19Module1OperationalStatus : 0|2@1+ (1,0) [0|3] "" Vector__XXX
 SG_ Hvesp19Module2OperationalStatus : 2|2@1+ (1,0) [0|3] "" Vector__XXX
 SG_ Hvesp19Module3OperationalStatus : 4|2@1+ (1,0) [0|3] "" Vector__XXX
 SG_ Hvesp19Module4OperationalStatus : 6|2@1+ (1,0) [0|3] "" Vector__XXX
 SG_ Hvesp19Module5OperationalStatus : 8|2@1+ (1,0) [0|3] "" Vector__XXX
 SG_ Hvesp19Module6OperationalStatus : 10|2@1+ (1,0) [0|3] "" Vector__XXX
 SG_ Hvesp19Module7OperationalStatus : 12|2@1+ (1,0) [0|3] "" Vector__XXX
 SG_ Hvesp19Module8OperationalStatus : 14|2@1+ (1,0) [0|3] "" Vector__XXX
 SG_ Hvesp19Module9OperationalStatus : 16|2@1+ (1,0) [0|3] "" Vector__XXX
 SG_ Hvsp19Mdl10OprtnlStts : 18|2@1+ (1,0) [0|3] "" Vector__XXX
 SG_ Hvsp19Mdl11OprtnlStts : 20|2@1+ (1,0) [0|3] "" Vector__XXX
 SG_ Hvsp19Mdl12OprtnlStts : 22|2@1+ (1,0) [0|3] "" Vector__XXX
 SG_ Hvsp19Mdl13OprtnlStts : 24|2@1+ (1,0) [0|3] "" Vector__XXX
 SG_ Hvsp19Mdl14OprtnlStts : 26|2@1+ (1,0) [0|3] "" Vector__XXX
 SG_ Hvsp19Mdl15OprtnlStts : 28|2@1+ (1,0) [0|3] "" Vector__XXX
 SG_ Hvsp19Mdl16OprtnlStts : 30|2@1+ (1,0) [0|3] "" Vector__XXX
 SG_ Hvsp19Mdl17OprtnlStts : 32|2@1+ (1,0) [0|3] "" Vector__XXX
 SG_ Hvsp19Mdl18OprtnlStts : 34|2@1+ (1,0) [0|3] "" Vector__XXX
 SG_ Hvsp19Mdl19OprtnlStts : 36|2@1+ (1,0) [0|3] "" Vector__XXX
 SG_ Hvsp19Mdl20OprtnlStts : 38|2@1+ (1,0) [0|3] "" Vector__XXX
 SG_ Hvsp19Mdl21OprtnlStts : 40|2@1+ (1,0) [0|3] "" Vector__XXX
 SG_ Hvsp19Mdl22OprtnlStts : 42|2@1+ (1,0) [0|3] "" Vector__XXX
 SG_ Hvsp19Mdl23OprtnlStts : 44|2@1+ (1,0) [0|3] "" Vector__XXX
 SG_ Hvsp19Mdl24OprtnlStts : 46|2@1+ (1,0) [0|3] "" Vector__XXX
 SG_ Hvsp19Mdl25OprtnlStts : 48|2@1+ (1,0) [0|3] "" Vector__XXX
 SG_ Hvsp19Mdl26OprtnlStts : 50|2@1+ (1,0) [0|3] "" Vector__XXX
 SG_ Hvsp19Mdl27OprtnlStts : 52|2@1+ (1,0) [0|3] "" Vector__XXX
 SG_ Hvsp19Mdl28OprtnlStts : 54|2@1+ (1,0) [0|3] "" Vector__XXX
 SG_ Hvsp19Mdl29OprtnlStts : 56|2@1+ (1,0) [0|3] "" Vector__XXX
 SG_ Hvsp19Mdl30OprtnlStts : 58|2@1+ (1,0) [0|3] "" Vector__XXX
 SG_ Hvsp19Mdl31OprtnlStts : 60|2@1+ (1,0) [0|3] "" Vector__XXX
 SG_ Hvsp19Mdl32OprtnlStts : 62|2@1+ (1,0) [0|3] "" Vector__XXX

BO_ 2364724222 HVESP19TS1: 8 Vector__XXX
 SG_ Hvsp19ThrmlMngmntSstmSlInptPwr : 0|16@1+ (0.5,0) [0|32127.5] "W" Vector__XXX
 SG_ Hvsp19TMtSstHVtIptPw : 16|16@1+ (0.5,0) [0|32127.5] "W" Vector__XXX
 SG_ Hvsp19ThrmlMngmntSstmCmprssrSpd : 32|8@1+ (32,0) [0|8000] "rpm" Vector__XXX
 SG_ Hvsp19ThrmlMngmntSstmRltvHmdt : 40|8@1+ (0.4,0) [0|100] "%" Vector__XXX
 SG_ Hvsp19ThrmlMngmntSstmHtrStts : 48|2@1+ (1,0) [0|3] "" Vector__XXX
 SG_ Hvsp19ThrmlMngmntSstmHvlStts : 50|2@1+ (1,0) [0|3] "" Vector__XXX
 SG_ Hvsp19ThrmlMngmntSstmMd : 52|4@1+ (1,0) [0|15] "" Vector__XXX
 SG_ Hvsp19ThrmlMngmntSstmClntLvl : 56|2@1+ (1,0) [0|3] "" Vector__XXX

BO_ 2364724478 HVESP19D8: 8 Vector__XXX
 SG_ Hvsp19HghstCllVltgMdlNmr : 0|8@1+ (1,0) [0|250] "count" Vector__XXX
 SG_ Hvsp19HghstCllVltgCllNmr : 8|8@1+ (1,0) [0|250] "count" Vector__XXX
 SG_ Hvsp19LwstCllVltgMdlNmr : 16|8@1+ (1,0) [0|250] "count" Vector__XXX
 SG_ Hvsp19LwstCllVltgCllNmr : 24|8@1+ (1,0) [0|250] "count" Vector__XXX
 SG_ Hvesp19AverageCellVoltage : 32|16@1+ (0.001,0) [0|64.255] "V" Vector__XXX

BO_ 2364724734 HVESP19D9: 8 Vector__XXX
 SG_ Hvsp19HghstCllTmprtrMdlNmr : 0|8@1+ (1,0) [0|250] "count" Vector__XXX
 SG_ Hvsp19HghstCllTmprtrCllNmr : 8|8@1+ (1,0) [0|250] "count" Vector__XXX
 SG_ Hvsp19LwstCllTmprtrMdlNmr : 16|8@1+ (1,0) [0|250] "count" Vector__XXX
 SG_ Hvsp19LwstCllTmprtrCllNmr : 24|8@1+ (1,0) [0|250] "count" Vector__XXX
 SG_ Hvess19ThermalEventDetected : 32|2@1+ (1,0) [0|3] "" Vector__XXX
 SG_ Hvsp19Dt9EmdddIntgrtSpprt : 50|2@1+ (1,0) [0|3] "" Vector__XXX
 SG_ Hvesp19Data9Counter : 52|4@1+ (1,0) [0|15] "" Vector__XXX
 SG_ Hvesp19Data9Crc : 56|8@1+ (1,0) [0|250] "count" Vector__XXX

BO_ 2364724990 HVESP19D10: 8 Vector__XXX
 SG_ Hvsp19HghstCllSttOfChrgMdlNmr : 0|8@1+ (1,0) [0|250] "count" Vector__XXX
 SG_ Hvsp19HghstCllSttOfChrgCllNmr : 8|8@1+ (1,0) [0|250] "count" Vector__XXX
 SG_ Hvsp19LwstCllSttOfChrgMdlNmr : 16|8@1+ (1,0) [0|250] "count" Vector__XXX
 SG_ Hvsp19LwstCllSttOfChrgCllNmr : 24|8@1+ (1,0) [0|250] "count" Vector__XXX
 SG_ Hvsp19HghVltgBsAtvIsltnTstRslts : 32|16@1+ (0.1,0) [0|6425.5] "OhmPerV" Vector__XXX
 SG_ Hvsp19HVtBsPssvIstTstRsts : 48|16@1+ (0.1,0) [0|6425.5] "OhmPerV" Vector__XXX

BO_ 2364725246 HVESP19D11: 8 Vector__XXX
 SG_ Hvsp19BsVltgNgtvTChsssGrndVltg : 0|16@1+ (0.05,0) [0|3212.75] "V" Vector__XXX
 SG_ Hvsp19VltgLvlNgtvTChsssGrndVltg : 16|16@1+ (0.05,0) [0|3212.75] "V" Vector__XXX
 SG_ Hvesp19ActualChargeRate : 32|16@1+ (0.05,0) [0|3212.75] "kW" Vector__XXX

BO_ 2364725502 HVESP20S2: 8 Vector__XXX
 SG_ Hvsp20DshrgPwrLmtDTSttOfChrg : 0|2@1+ (1,0) [0|3] "" Vector__XXX
 SG_ Hvsp20DshrgPwrLmtDTBttrTmprtr : 2|2@1+ (1,0) [0|3] "" Vector__XXX
 SG_ Hvsp20DsPwLtDTBttDstCdt : 4|2@1+ (1,0) [0|3] "" Vector__XXX
 SG_ Hvsp20DsPwLtDTBttOCVt : 6|2@1+ (1,0) [0|3] "" Vector__XXX
 SG_ Hvsp20DshrgPwrLmtDTBttrCrrnt : 8|2@1+ (1,0) [0|3] "" Vector__XXX
 SG_ Hvsp20DshrgPwrLmtDTAnUndfndCs : 10|2@1+ (1,0) [0|3] "" Vector__XXX
 SG_ Hvsp20ChrgPwrLmtDTSttOfChrg : 32|2@1+ (1,0) [0|3] "" Vector__XXX
 SG_ Hvsp20ChrgPwrLmtDTBttrTmprtr : 34|2@1+ (1,0) [0|3] "" Vector__XXX
 SG_ Hvsp20CPwLtDTBttDstCdt : 36|2@1+ (1,0) [0|3] "" Vector__XXX
 SG_ Hvsp20ChrgPwrLmtDTBttrOrCllVltg : 38|2@1+ (1,0) [0|3] "" Vector__XXX
 SG_ Hvsp20ChrgPwrLmtDTBttrCrrnt : 40|2@1+ (1,0) [0|3] "" Vector__XXX
 SG_ Hvsp20ChrgPwrLmtDTAnUndfndCs : 42|2@1+ (1,0) [0|3] "" Vector__XXX

BO_ 2364725758 HVESP20D1: 8 Vector__XXX
 SG_ Hvesp20AvailableDischargePower : 0|16@1+ (0.05,0) [0|3212.75] "kW" Vector__XXX
 SG_ Hvesp20AvailableChargePower : 16|16@1+ (0.05,0) [0|3212.75] "kW" Vector__XXX
 SG_ Hvesp20VoltageLevel : 32|16@1+ (0.05,0) [0|3212.75] "V" Vector__XXX
 SG_ Hvesp20Current : 48|16@1+ (0.05,-1600) [-1600|1612.75] "A" Vector__XXX

BO_ 2364726014 HVESP20D2: 8 Vector__XXX
 SG_ Hvesp20FastUpdateStateOfCharge : 0|16@1+ (0.0015625,0) [0|100.3984375] "%" Vector__XXX
 SG_ Hvesp20HighestCellVoltage : 16|16@1+ (0.001,0) [0|64.255] "V" Vector__XXX
 SG_ Hvesp20LowestCellVoltage : 32|16@1+ (0.001,0) [0|64.255] "V" Vector__XXX
 SG_ Hvsp20CllVltgDffrntlStts : 48|4@1+ (1,0) [0|15] "" Vector__XXX

BO_ 2364726270 HVESP20D3: 8 Vector__XXX
 SG_ Hvesp20HighestCellTemperature : 0|16@1+ (0.03125,-273) [-273|1734.96875] "degC" Vector__XXX
 SG_ Hvesp20LowestCellTemperature : 16|16@1+ (0.03125,-273) [-273|1734.96875] "degC" Vector__XXX
 SG_ Hvesp20AverageCellTemperature : 32|16@1+ (0.03125,-273) [-273|1734.96875] "degC" Vector__XXX
 SG_ Hvsp20CllTmprtrDffrntlStts : 48|2@1+ (1,0) [0|3] "" Vector__XXX

BO_ 2364726526 HVESP20D4: 8 Vector__XXX
 SG_ Hvesp20DischargeCapacity : 0|16@1+ (0.01,0) [0|642.55] "Ah" Vector__XXX
 SG_ Hvesp20ChargeCapacity : 16|16@1+ (0.01,0) [0|642.55] "Ah" Vector__XXX
 SG_ Hvesp20CellBalancingCount : 32|16@1+ (1,0) [0|64255] "count" Vector__XXX

BO_ 2364726782 HVESP20D5: 8 Vector__XXX
 SG_ Hvesp20LowestCellStateOfCharge : 32|16@1+ (0.0015625,0) [0|100.3984375] "%" Vector__XXX
 SG_ Hvesp20HighestCellStateOfCharge : 48|16@1+ (0.0015625,0) [0|100.3984375] "%" Vector__XXX
 SG_ Hvsp20MxmmInstntnsDshrgCrrntLmt : 0|16@1+ (0.05,-1600) [-1600|0] "A" Vector__XXX
 SG_ Hvsp20MxmmInstntnsChrgCrrntLmt : 16|16@1+ (0.05,-1600) [0|1612.75] "A" Vector__XXX

BO_ 2364727038 HVESP20D6: 8 Vector__XXX
 SG_ Hvesp20BusVoltage : 0|16@1+ (0.05,0) [0|3212.75] "V" Vector__XXX
 SG_ Hvesp20IgnitionVoltage : 16|16@1+ (0.01,0) [0|642.55] "V" Vector__XXX
 SG_ Hvesp20IntakeCoolantTemperature : 32|8@1+ (1,-40) [-40|210] "degC" Vector__XXX
 SG_ Hvesp20OutletCoolantTemperature : 40|8@1+ (1,-40) [-40|210] "degC" Vector__XXX
 SG_ Hvesp20ElectronicsTemperature : 48|8@1+ (1,-40) [-40|210] "degC" Vector__XXX
 SG_ Hvesp20Temperature : 56|8@1+ (1,-40) [-40|210] "degC" Vector__XXX

BO_ 2364727294 HVESP20S1: 8 Vector__XXX
 SG_ Hvsp20HghVltgBsPstvCnttrStt : 0|2@1+ (1,0) [0|3] "" Vector__XXX
 SG_ Hvsp20HghVltgBsNgtvCnttrStt : 2|2@1+ (1,0) [0|3] "" Vector__XXX
 SG_ Hvsp20HghVltgBsDsnntFrwrnng : 4|4@1+ (1,0) [0|15] "" Vector__XXX
 SG_ Hvsp20HghVltgBsPrChrgRlStt : 8|2@1+ (1,0) [0|3] "" Vector__XXX
 SG_ Hvsp20CntrOfPkCnttrStt : 10|2@1+ (1,0) [0|3] "" Vector__XXX
 SG_ Hvsp20HghVltgBsAtvIsltnTstStts : 12|4@1+ (1,0) [0|15] "" Vector__XXX
 SG_ Hvsp20HghVltgBsPssvIsltnTstStts : 16|4@1+ (1,0) [0|15] "" Vector__XXX
 SG_ Hvesp20HvilStatus : 20|2@1+ (1,0) [0|3] "" Vector__XXX
 SG_ Hvesp20InertiaSwitchStatus : 22|2@1+ (1,0) [0|3] "" Vector__XXX
 SG_ Hvesp20StateOfChargeStatus : 24|4@1+ (1,0) [0|15] "" Vector__XXX
 SG_ Hvesp20CellBalanceStatus : 28|2@1+ (1,0) [0|3] "" Vector__XXX
 SG_ Hvesp20CellBalancingActive : 30|2@1+ (1,0) [0|3] "" Vector__XXX
 SG_ Hvesp20InternalChargerStatus : 32|2@1+ (1,0) [0|3] "" Vector__XXX
 SG_ Hvsp20HghVltgBsCnntnStts : 40|4@1+ (1,0) [0|15] "" Vector__XXX
 SG_ Hvesp20OperationalStatus : 44|4@1+ (1,0) [0|15] "" Vector__XXX
 SG_ Hvesp20Status1Counter : 52|4@1+ (1,0) [0|15] "" Vector__XXX
 SG_ Hvesp20Status1Crc : 56|8@1+ (1,0) [0|250] "count" Vector__XXX

BO_ 2364727550 HVESP20D7: 8 Vector__XXX
 SG_ Hvesp20DischargeEnergyCapacity : 0|24@1+ (0.001,0) [0|16449.535] "kWh" Vector__XXX
 SG_ Hvesp20ChargeEnergyCapacity : 24|24@1+ (0.001,0) [0|16449.535] "kWh" Vector__XXX
 SG_ Hvsp20MxmmChrgVltgLmt : 48|16@1+ (0.05,0) [0|3212.75] "V" Vector__XXX

BO_ 2364727806 HVESP20MS1: 8 Vector__XXX
 SG_ Hvesp20Module1OperationalStatus : 0|2@1+ (1,0) [0|3] "" Vector__XXX
 SG_ Hvesp20Module2OperationalStatus : 2|2@1+ (1,0) [0|3] "" Vector__XXX
 SG_ Hvesp20Module3OperationalStatus : 4|2@1+ (1,0) [0|3] "" Vector__XXX
 SG_ Hvesp20Module4OperationalStatus : 6|2@1+ (1,0) [0|3] "" Vector__XXX
 SG_ Hvesp20Module5OperationalStatus : 8|2@1+ (1,0) [0|3] "" Vector__XXX
 SG_ Hvesp20Module6OperationalStatus : 10|2@1+ (1,0) [0|3] "" Vector__XXX
 SG_ Hvesp20Module7OperationalStatus : 12|2@1+ (1,0) [0|3] "" Vector__XXX
 SG_ Hvesp20Module8OperationalStatus : 14|2@1+ (1,0) [0|3] "" Vector__XXX
 SG_ Hvesp20Module9OperationalStatus : 16|2@1+ (1,0) [0|3] "" Vector__XXX
 SG_ Hvsp20Mdl10OprtnlStts : 18|2@1+ (1,0) [0|3] "" Vector__XXX
 SG_ Hvsp20Mdl11OprtnlStts : 20|2@1+ (1,0) [0|3] "" Vector__XXX
 SG_ Hvsp20Mdl12OprtnlStts : 22|2@1+ (1,0) [0|3] "" Vector__XXX
 SG_ Hvsp20Mdl13OprtnlStts : 24|2@1+ (1,0) [0|3] "" Vector__XXX
 SG_ Hvsp20Mdl14OprtnlStts : 26|2@1+ (1,0) [0|3] "" Vector__XXX
 SG_ Hvsp20Mdl15OprtnlStts : 28|2@1+ (1,0) [0|3] "" Vector__XXX
 SG_ Hvsp20Mdl16OprtnlStts : 30|2@1+ (1,0) [0|3] "" Vector__XXX
 SG_ Hvsp20Mdl17OprtnlStts : 32|2@1+ (1,0) [0|3] "" Vector__XXX
 SG_ Hvsp20Mdl18OprtnlStts : 34|2@1+ (1,0) [0|3] "" Vector__XXX
 SG_ Hvsp20Mdl19OprtnlStts : 36|2@1+ (1,0) [0|3] "" Vector__XXX
 SG_ Hvsp20Mdl20OprtnlStts : 38|2@1+ (1,0) [0|3] "" Vector__XXX
 SG_ Hvsp20Mdl21OprtnlStts : 40|2@1+ (1,0) [0|3] "" Vector__XXX
 SG_ Hvsp20Mdl22OprtnlStts : 42|2@1+ (1,0) [0|3] "" Vector__XXX
 SG_ Hvsp20Mdl23OprtnlStts : 44|2@1+ (1,0) [0|3] "" Vector__XXX
 SG_ Hvsp20Mdl24OprtnlStts : 46|2@1+ (1,0) [0|3] "" Vector__XXX
 SG_ Hvsp20Mdl25OprtnlStts : 48|2@1+ (1,0) [0|3] "" Vector__XXX
 SG_ Hvsp20Mdl26OprtnlStts : 50|2@1+ (1,0) [0|3] "" Vector__XXX
 SG_ Hvsp20Mdl27OprtnlStts : 52|2@1+ (1,0) [0|3] "" Vector__XXX
 SG_ Hvsp20Mdl28OprtnlStts : 54|2@1+ (1,0) [0|3] "" Vector__XXX
 SG_ Hvsp20Mdl29OprtnlStts : 56|2@1+ (1,0) [0|3] "" Vector__XXX
 SG_ Hvsp20Mdl30OprtnlStts : 58|2@1+ (1,0) [0|3] "" Vector__XXX
 SG_ Hvsp20Mdl31OprtnlStts : 60|2@1+ (1,0) [0|3] "" Vector__XXX
 SG_ Hvsp20Mdl32OprtnlStts : 62|2@1+ (1,0) [0|3] "" Vector__XXX

BO_ 2364728062 HVESP20TS1: 8 Vector__XXX
 SG_ Hvsp20ThrmlMngmntSstmSlInptPwr : 0|16@1+ (0.5,0) [0|32127.5] "W" Vector__XXX
 SG_ Hvsp20TMtSstHVtIptPw : 16|16@1+ (0.5,0) [0|32127.5] "W" Vector__XXX
 SG_ Hvsp20ThrmlMngmntSstmCmprssrSpd : 32|8@1+ (32,0) [0|8000] "rpm" Vector__XXX
 SG_ Hvsp20ThrmlMngmntSstmRltvHmdt : 40|8@1+ (0.4,0) [0|100] "%" Vector__XXX
 SG_ Hvsp20ThrmlMngmntSstmHtrStts : 48|2@1+ (1,0) [0|3] "" Vector__XXX
 SG_ Hvsp20ThrmlMngmntSstmHvlStts : 50|2@1+ (1,0) [0|3] "" Vector__XXX
 SG_ Hvsp20ThrmlMngmntSstmMd : 52|4@1+ (1,0) [0|15] "" Vector__XXX
 SG_ Hvsp20ThrmlMngmntSstmClntLvl : 56|2@1+ (1,0) [0|3] "" Vector__XXX

BO_ 2364728318 HVESP20D8: 8 Vector__XXX
 SG_ Hvsp20HghstCllVltgMdlNmr : 0|8@1+ (1,0) [0|250] "count" Vector__XXX
 SG_ Hvsp20HghstCllVltgCllNmr : 8|8@1+ (1,0) [0|250] "count" Vector__XXX
 SG_ Hvsp20LwstCllVltgMdlNmr : 16|8@1+ (1,0) [0|250] "count" Vector__XXX
 SG_ Hvsp20LwstCllVltgCllNmr : 24|8@1+ (1,0) [0|250] "count" Vector__XXX
 SG_ Hvesp20AverageCellVoltage : 32|16@1+ (0.001,0) [0|64.255] "V" Vector__XXX

BO_ 2364728574 HVESP20D9: 8 Vector__XXX
 SG_ Hvsp20HghstCllTmprtrMdlNmr : 0|8@1+ (1,0) [0|250] "count" Vector__XXX
 SG_ Hvsp20HghstCllTmprtrCllNmr : 8|8@1+ (1,0) [0|250] "count" Vector__XXX
 SG_ Hvsp20LwstCllTmprtrMdlNmr : 16|8@1+ (1,0) [0|250] "count" Vector__XXX
 SG_ Hvsp20LwstCllTmprtrCllNmr : 24|8@1+ (1,0) [0|250] "count" Vector__XXX
 SG_ Hvess20ThermalEventDetected : 32|2@1+ (1,0) [0|3] "" Vector__XXX
 SG_ Hvsp20Dt9EmdddIntgrtSpprt : 50|2@1+ (1,0) [0|3] "" Vector__XXX
 SG_ Hvesp20Data9Counter : 52|4@1+ (1,0) [0|15] "" Vector__XXX
 SG_ Hvesp20Data9Crc : 56|8@1+ (1,0) [0|250] "count" Vector__XXX

BO_ 2364728830 HVESP20D10: 8 Vector__XXX
 SG_ Hvsp20HghstCllSttOfChrgMdlNmr : 0|8@1+ (1,0) [0|250] "count" Vector__XXX
 SG_ Hvsp20HghstCllSttOfChrgCllNmr : 8|8@1+ (1,0) [0|250] "count" Vector__XXX
 SG_ Hvsp20LwstCllSttOfChrgMdlNmr : 16|8@1+ (1,0) [0|250] "count" Vector__XXX
 SG_ Hvsp20LwstCllSttOfChrgCllNmr : 24|8@1+ (1,0) [0|250] "count" Vector__XXX
 SG_ Hvsp20HghVltgBsAtvIsltnTstRslts : 32|16@1+ (0.1,0) [0|6425.5] "OhmPerV" Vector__XXX
 SG_ Hvsp20HVtBsPssvIstTstRsts : 48|16@1+ (0.1,0) [0|6425.5] "OhmPerV" Vector__XXX

BO_ 2364729086 HVESP20D11: 8 Vector__XXX
 SG_ Hvsp20BsVltgNgtvTChsssGrndVltg : 0|16@1+ (0.05,0) [0|3212.75] "V" Vector__XXX
 SG_ Hvsp20VltgLvlNgtvTChsssGrndVltg : 16|16@1+ (0.05,0) [0|3212.75] "V" Vector__XXX
 SG_ Hvesp20ActualChargeRate : 32|16@1+ (0.05,0) [0|3212.75] "kW" Vector__XXX

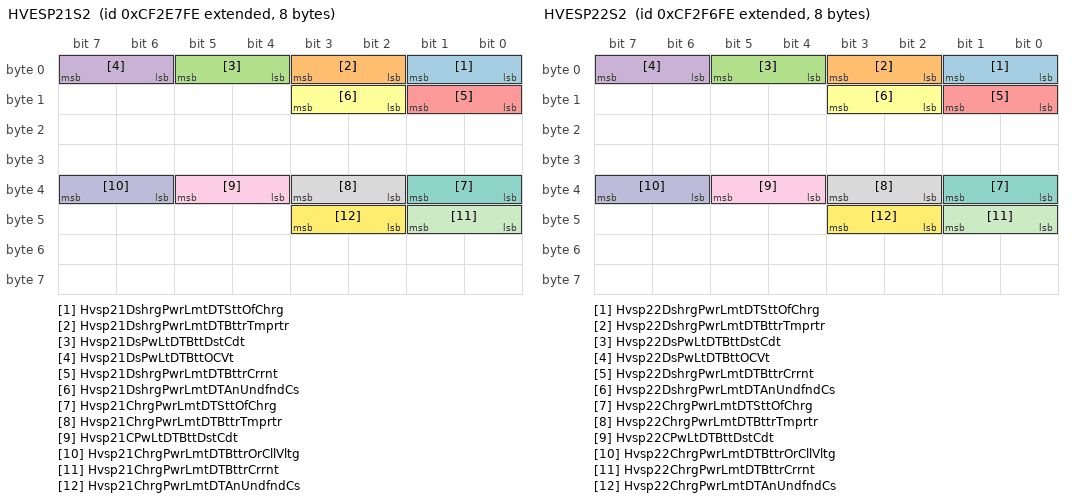
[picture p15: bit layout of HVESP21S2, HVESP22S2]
BO_ 2364729342 HVESP21S2: 8 Vector__XXX
 SG_ Hvsp21DshrgPwrLmtDTSttOfChrg : 0|2@1+ (1,0) [0|3] "" Vector__XXX
 SG_ Hvsp21DshrgPwrLmtDTBttrTmprtr : 2|2@1+ (1,0) [0|3] "" Vector__XXX
 SG_ Hvsp21DsPwLtDTBttDstCdt : 4|2@1+ (1,0) [0|3] "" Vector__XXX
 SG_ Hvsp21DsPwLtDTBttOCVt : 6|2@1+ (1,0) [0|3] "" Vector__XXX
 SG_ Hvsp21DshrgPwrLmtDTBttrCrrnt : 8|2@1+ (1,0) [0|3] "" Vector__XXX
 SG_ Hvsp21DshrgPwrLmtDTAnUndfndCs : 10|2@1+ (1,0) [0|3] "" Vector__XXX
 SG_ Hvsp21ChrgPwrLmtDTSttOfChrg : 32|2@1+ (1,0) [0|3] "" Vector__XXX
 SG_ Hvsp21ChrgPwrLmtDTBttrTmprtr : 34|2@1+ (1,0) [0|3] "" Vector__XXX
 SG_ Hvsp21CPwLtDTBttDstCdt : 36|2@1+ (1,0) [0|3] "" Vector__XXX
 SG_ Hvsp21ChrgPwrLmtDTBttrOrCllVltg : 38|2@1+ (1,0) [0|3] "" Vector__XXX
 SG_ Hvsp21ChrgPwrLmtDTBttrCrrnt : 40|2@1+ (1,0) [0|3] "" Vector__XXX
 SG_ Hvsp21ChrgPwrLmtDTAnUndfndCs : 42|2@1+ (1,0) [0|3] "" Vector__XXX

BO_ 2364729598 HVESP21D1: 8 Vector__XXX
 SG_ Hvesp21AvailableDischargePower : 0|16@1+ (0.05,0) [0|3212.75] "kW" Vector__XXX
 SG_ Hvesp21AvailableChargePower : 16|16@1+ (0.05,0) [0|3212.75] "kW" Vector__XXX
 SG_ Hvesp21VoltageLevel : 32|16@1+ (0.05,0) [0|3212.75] "V" Vector__XXX
 SG_ Hvesp21Current : 48|16@1+ (0.05,-1600) [-1600|1612.75] "A" Vector__XXX

BO_ 2364729854 HVESP21D2: 8 Vector__XXX
 SG_ Hvesp21FastUpdateStateOfCharge : 0|16@1+ (0.0015625,0) [0|100.3984375] "%" Vector__XXX
 SG_ Hvesp21HighestCellVoltage : 16|16@1+ (0.001,0) [0|64.255] "V" Vector__XXX
 SG_ Hvesp21LowestCellVoltage : 32|16@1+ (0.001,0) [0|64.255] "V" Vector__XXX
 SG_ Hvsp21CllVltgDffrntlStts : 48|4@1+ (1,0) [0|15] "" Vector__XXX

BO_ 2364730110 HVESP21D3: 8 Vector__XXX
 SG_ Hvesp21HighestCellTemperature : 0|16@1+ (0.03125,-273) [-273|1734.96875] "degC" Vector__XXX
 SG_ Hvesp21LowestCellTemperature : 16|16@1+ (0.03125,-273) [-273|1734.96875] "degC" Vector__XXX
 SG_ Hvesp21AverageCellTemperature : 32|16@1+ (0.03125,-273) [-273|1734.96875] "degC" Vector__XXX
 SG_ Hvsp21CllTmprtrDffrntlStts : 48|2@1+ (1,0) [0|3] "" Vector__XXX

BO_ 2364730366 HVESP21D4: 8 Vector__XXX
 SG_ Hvesp21DischargeCapacity : 0|16@1+ (0.01,0) [0|642.55] "Ah" Vector__XXX
 SG_ Hvesp21ChargeCapacity : 16|16@1+ (0.01,0) [0|642.55] "Ah" Vector__XXX
 SG_ Hvesp21CellBalancingCount : 32|16@1+ (1,0) [0|64255] "count" Vector__XXX

BO_ 2364730622 HVESP21D5: 8 Vector__XXX
 SG_ Hvesp21LowestCellStateOfCharge : 32|16@1+ (0.0015625,0) [0|100.3984375] "%" Vector__XXX
 SG_ Hvesp21HighestCellStateOfCharge : 48|16@1+ (0.0015625,0) [0|100.3984375] "%" Vector__XXX
 SG_ Hvsp21MxmmInstntnsDshrgCrrntLmt : 0|16@1+ (0.05,-1600) [-1600|0] "A" Vector__XXX
 SG_ Hvsp21MxmmInstntnsChrgCrrntLmt : 16|16@1+ (0.05,-1600) [0|1612.75] "A" Vector__XXX

BO_ 2364730878 HVESP21D6: 8 Vector__XXX
 SG_ Hvesp21BusVoltage : 0|16@1+ (0.05,0) [0|3212.75] "V" Vector__XXX
 SG_ Hvesp21IgnitionVoltage : 16|16@1+ (0.01,0) [0|642.55] "V" Vector__XXX
 SG_ Hvesp21IntakeCoolantTemperature : 32|8@1+ (1,-40) [-40|210] "degC" Vector__XXX
 SG_ Hvesp21OutletCoolantTemperature : 40|8@1+ (1,-40) [-40|210] "degC" Vector__XXX
 SG_ Hvesp21ElectronicsTemperature : 48|8@1+ (1,-40) [-40|210] "degC" Vector__XXX
 SG_ Hvesp21Temperature : 56|8@1+ (1,-40) [-40|210] "degC" Vector__XXX

BO_ 2364731134 HVESP21S1: 8 Vector__XXX
 SG_ Hvsp21HghVltgBsPstvCnttrStt : 0|2@1+ (1,0) [0|3] "" Vector__XXX
 SG_ Hvsp21HghVltgBsNgtvCnttrStt : 2|2@1+ (1,0) [0|3] "" Vector__XXX
 SG_ Hvsp21HghVltgBsDsnntFrwrnng : 4|4@1+ (1,0) [0|15] "" Vector__XXX
 SG_ Hvsp21HghVltgBsPrChrgRlStt : 8|2@1+ (1,0) [0|3] "" Vector__XXX
 SG_ Hvsp21CntrOfPkCnttrStt : 10|2@1+ (1,0) [0|3] "" Vector__XXX
 SG_ Hvsp21HghVltgBsAtvIsltnTstStts : 12|4@1+ (1,0) [0|15] "" Vector__XXX
 SG_ Hvsp21HghVltgBsPssvIsltnTstStts : 16|4@1+ (1,0) [0|15] "" Vector__XXX
 SG_ Hvesp21HvilStatus : 20|2@1+ (1,0) [0|3] "" Vector__XXX
 SG_ Hvesp21InertiaSwitchStatus : 22|2@1+ (1,0) [0|3] "" Vector__XXX
 SG_ Hvesp21StateOfChargeStatus : 24|4@1+ (1,0) [0|15] "" Vector__XXX
 SG_ Hvesp21CellBalanceStatus : 28|2@1+ (1,0) [0|3] "" Vector__XXX
 SG_ Hvesp21CellBalancingActive : 30|2@1+ (1,0) [0|3] "" Vector__XXX
 SG_ Hvesp21InternalChargerStatus : 32|2@1+ (1,0) [0|3] "" Vector__XXX
 SG_ Hvsp21HghVltgBsCnntnStts : 40|4@1+ (1,0) [0|15] "" Vector__XXX
 SG_ Hvesp21OperationalStatus : 44|4@1+ (1,0) [0|15] "" Vector__XXX
 SG_ Hvesp21Status1Counter : 52|4@1+ (1,0) [0|15] "" Vector__XXX
 SG_ Hvesp21Status1Crc : 56|8@1+ (1,0) [0|250] "count" Vector__XXX

BO_ 2364731390 HVESP21D7: 8 Vector__XXX
 SG_ Hvesp21DischargeEnergyCapacity : 0|24@1+ (0.001,0) [0|16449.535] "kWh" Vector__XXX
 SG_ Hvesp21ChargeEnergyCapacity : 24|24@1+ (0.001,0) [0|16449.535] "kWh" Vector__XXX
 SG_ Hvsp21MxmmChrgVltgLmt : 48|16@1+ (0.05,0) [0|3212.75] "V" Vector__XXX

BO_ 2364731646 HVESP21MS1: 8 Vector__XXX
 SG_ Hvesp21Module1OperationalStatus : 0|2@1+ (1,0) [0|3] "" Vector__XXX
 SG_ Hvesp21Module2OperationalStatus : 2|2@1+ (1,0) [0|3] "" Vector__XXX
 SG_ Hvesp21Module3OperationalStatus : 4|2@1+ (1,0) [0|3] "" Vector__XXX
 SG_ Hvesp21Module4OperationalStatus : 6|2@1+ (1,0) [0|3] "" Vector__XXX
 SG_ Hvesp21Module5OperationalStatus : 8|2@1+ (1,0) [0|3] "" Vector__XXX
 SG_ Hvesp21Module6OperationalStatus : 10|2@1+ (1,0) [0|3] "" Vector__XXX
 SG_ Hvesp21Module7OperationalStatus : 12|2@1+ (1,0) [0|3] "" Vector__XXX
 SG_ Hvesp21Module8OperationalStatus : 14|2@1+ (1,0) [0|3] "" Vector__XXX
 SG_ Hvesp21Module9OperationalStatus : 16|2@1+ (1,0) [0|3] "" Vector__XXX
 SG_ Hvsp21Mdl10OprtnlStts : 18|2@1+ (1,0) [0|3] "" Vector__XXX
 SG_ Hvsp21Mdl11OprtnlStts : 20|2@1+ (1,0) [0|3] "" Vector__XXX
 SG_ Hvsp21Mdl12OprtnlStts : 22|2@1+ (1,0) [0|3] "" Vector__XXX
 SG_ Hvsp21Mdl13OprtnlStts : 24|2@1+ (1,0) [0|3] "" Vector__XXX
 SG_ Hvsp21Mdl14OprtnlStts : 26|2@1+ (1,0) [0|3] "" Vector__XXX
 SG_ Hvsp21Mdl15OprtnlStts : 28|2@1+ (1,0) [0|3] "" Vector__XXX
 SG_ Hvsp21Mdl16OprtnlStts : 30|2@1+ (1,0) [0|3] "" Vector__XXX
 SG_ Hvsp21Mdl17OprtnlStts : 32|2@1+ (1,0) [0|3] "" Vector__XXX
 SG_ Hvsp21Mdl18OprtnlStts : 34|2@1+ (1,0) [0|3] "" Vector__XXX
 SG_ Hvsp21Mdl19OprtnlStts : 36|2@1+ (1,0) [0|3] "" Vector__XXX
 SG_ Hvsp21Mdl20OprtnlStts : 38|2@1+ (1,0) [0|3] "" Vector__XXX
 SG_ Hvsp21Mdl21OprtnlStts : 40|2@1+ (1,0) [0|3] "" Vector__XXX
 SG_ Hvsp21Mdl22OprtnlStts : 42|2@1+ (1,0) [0|3] "" Vector__XXX
 SG_ Hvsp21Mdl23OprtnlStts : 44|2@1+ (1,0) [0|3] "" Vector__XXX
 SG_ Hvsp21Mdl24OprtnlStts : 46|2@1+ (1,0) [0|3] "" Vector__XXX
 SG_ Hvsp21Mdl25OprtnlStts : 48|2@1+ (1,0) [0|3] "" Vector__XXX
 SG_ Hvsp21Mdl26OprtnlStts : 50|2@1+ (1,0) [0|3] "" Vector__XXX
 SG_ Hvsp21Mdl27OprtnlStts : 52|2@1+ (1,0) [0|3] "" Vector__XXX
 SG_ Hvsp21Mdl28OprtnlStts : 54|2@1+ (1,0) [0|3] "" Vector__XXX
 SG_ Hvsp21Mdl29OprtnlStts : 56|2@1+ (1,0) [0|3] "" Vector__XXX
 SG_ Hvsp21Mdl30OprtnlStts : 58|2@1+ (1,0) [0|3] "" Vector__XXX
 SG_ Hvsp21Mdl31OprtnlStts : 60|2@1+ (1,0) [0|3] "" Vector__XXX
 SG_ Hvsp21Mdl32OprtnlStts : 62|2@1+ (1,0) [0|3] "" Vector__XXX

BO_ 2364731902 HVESP21TS1: 8 Vector__XXX
 SG_ Hvsp21ThrmlMngmntSstmSlInptPwr : 0|16@1+ (0.5,0) [0|32127.5] "W" Vector__XXX
 SG_ Hvsp21TMtSstHVtIptPw : 16|16@1+ (0.5,0) [0|32127.5] "W" Vector__XXX
 SG_ Hvsp21ThrmlMngmntSstmCmprssrSpd : 32|8@1+ (32,0) [0|8000] "rpm" Vector__XXX
 SG_ Hvsp21ThrmlMngmntSstmRltvHmdt : 40|8@1+ (0.4,0) [0|100] "%" Vector__XXX
 SG_ Hvsp21ThrmlMngmntSstmHtrStts : 48|2@1+ (1,0) [0|3] "" Vector__XXX
 SG_ Hvsp21ThrmlMngmntSstmHvlStts : 50|2@1+ (1,0) [0|3] "" Vector__XXX
 SG_ Hvsp21ThrmlMngmntSstmMd : 52|4@1+ (1,0) [0|15] "" Vector__XXX
 SG_ Hvsp21ThrmlMngmntSstmClntLvl : 56|2@1+ (1,0) [0|3] "" Vector__XXX

BO_ 2364732158 HVESP21D8: 8 Vector__XXX
 SG_ Hvsp21HghstCllVltgMdlNmr : 0|8@1+ (1,0) [0|250] "count" Vector__XXX
 SG_ Hvsp21HghstCllVltgCllNmr : 8|8@1+ (1,0) [0|250] "count" Vector__XXX
 SG_ Hvsp21LwstCllVltgMdlNmr : 16|8@1+ (1,0) [0|250] "count" Vector__XXX
 SG_ Hvsp21LwstCllVltgCllNmr : 24|8@1+ (1,0) [0|250] "count" Vector__XXX
 SG_ Hvesp21AverageCellVoltage : 32|16@1+ (0.001,0) [0|64.255] "V" Vector__XXX

BO_ 2364732414 HVESP21D9: 8 Vector__XXX
 SG_ Hvsp21HghstCllTmprtrMdlNmr : 0|8@1+ (1,0) [0|250] "count" Vector__XXX
 SG_ Hvsp21HghstCllTmprtrCllNmr : 8|8@1+ (1,0) [0|250] "count" Vector__XXX
 SG_ Hvsp21LwstCllTmprtrMdlNmr : 16|8@1+ (1,0) [0|250] "count" Vector__XXX
 SG_ Hvsp21LwstCllTmprtrCllNmr : 24|8@1+ (1,0) [0|250] "count" Vector__XXX
 SG_ Hvess21ThermalEventDetected : 32|2@1+ (1,0) [0|3] "" Vector__XXX
 SG_ Hvsp21Dt9EmdddIntgrtSpprt : 50|2@1+ (1,0) [0|3] "" Vector__XXX
 SG_ Hvesp21Data9Counter : 52|4@1+ (1,0) [0|15] "" Vector__XXX
 SG_ Hvesp21Data9Crc : 56|8@1+ (1,0) [0|250] "count" Vector__XXX

BO_ 2364732670 HVESP21D10: 8 Vector__XXX
 SG_ Hvsp21HghstCllSttOfChrgMdlNmr : 0|8@1+ (1,0) [0|250] "count" Vector__XXX
 SG_ Hvsp21HghstCllSttOfChrgCllNmr : 8|8@1+ (1,0) [0|250] "count" Vector__XXX
 SG_ Hvsp21LwstCllSttOfChrgMdlNmr : 16|8@1+ (1,0) [0|250] "count" Vector__XXX
 SG_ Hvsp21LwstCllSttOfChrgCllNmr : 24|8@1+ (1,0) [0|250] "count" Vector__XXX
 SG_ Hvsp21HghVltgBsAtvIsltnTstRslts : 32|16@1+ (0.1,0) [0|6425.5] "OhmPerV" Vector__XXX
 SG_ Hvsp21HVtBsPssvIstTstRsts : 48|16@1+ (0.1,0) [0|6425.5] "OhmPerV" Vector__XXX

BO_ 2364732926 HVESP21D11: 8 Vector__XXX
 SG_ Hvsp21BsVltgNgtvTChsssGrndVltg : 0|16@1+ (0.05,0) [0|3212.75] "V" Vector__XXX
 SG_ Hvsp21VltgLvlNgtvTChsssGrndVltg : 16|16@1+ (0.05,0) [0|3212.75] "V" Vector__XXX
 SG_ Hvesp21ActualChargeRate : 32|16@1+ (0.05,0) [0|3212.75] "kW" Vector__XXX

BO_ 2364733182 HVESP22S2: 8 Vector__XXX
 SG_ Hvsp22DshrgPwrLmtDTSttOfChrg : 0|2@1+ (1,0) [0|3] "" Vector__XXX
 SG_ Hvsp22DshrgPwrLmtDTBttrTmprtr : 2|2@1+ (1,0) [0|3] "" Vector__XXX
 SG_ Hvsp22DsPwLtDTBttDstCdt : 4|2@1+ (1,0) [0|3] "" Vector__XXX
 SG_ Hvsp22DsPwLtDTBttOCVt : 6|2@1+ (1,0) [0|3] "" Vector__XXX
 SG_ Hvsp22DshrgPwrLmtDTBttrCrrnt : 8|2@1+ (1,0) [0|3] "" Vector__XXX
 SG_ Hvsp22DshrgPwrLmtDTAnUndfndCs : 10|2@1+ (1,0) [0|3] "" Vector__XXX
 SG_ Hvsp22ChrgPwrLmtDTSttOfChrg : 32|2@1+ (1,0) [0|3] "" Vector__XXX
 SG_ Hvsp22ChrgPwrLmtDTBttrTmprtr : 34|2@1+ (1,0) [0|3] "" Vector__XXX
 SG_ Hvsp22CPwLtDTBttDstCdt : 36|2@1+ (1,0) [0|3] "" Vector__XXX
 SG_ Hvsp22ChrgPwrLmtDTBttrOrCllVltg : 38|2@1+ (1,0) [0|3] "" Vector__XXX
 SG_ Hvsp22ChrgPwrLmtDTBttrCrrnt : 40|2@1+ (1,0) [0|3] "" Vector__XXX
 SG_ Hvsp22ChrgPwrLmtDTAnUndfndCs : 42|2@1+ (1,0) [0|3] "" Vector__XXX

BO_ 2364733438 HVESP22D1: 8 Vector__XXX
 SG_ Hvesp22AvailableDischargePower : 0|16@1+ (0.05,0) [0|3212.75] "kW" Vector__XXX
 SG_ Hvesp22AvailableChargePower : 16|16@1+ (0.05,0) [0|3212.75] "kW" Vector__XXX
 SG_ Hvesp22VoltageLevel : 32|16@1+ (0.05,0) [0|3212.75] "V" Vector__XXX
 SG_ Hvesp22Current : 48|16@1+ (0.05,-1600) [-1600|1612.75] "A" Vector__XXX

BO_ 2364733694 HVESP22D2: 8 Vector__XXX
 SG_ Hvesp22FastUpdateStateOfCharge : 0|16@1+ (0.0015625,0) [0|100.3984375] "%" Vector__XXX
 SG_ Hvesp22HighestCellVoltage : 16|16@1+ (0.001,0) [0|64.255] "V" Vector__XXX
 SG_ Hvesp22LowestCellVoltage : 32|16@1+ (0.001,0) [0|64.255] "V" Vector__XXX
 SG_ Hvsp22CllVltgDffrntlStts : 48|4@1+ (1,0) [0|15] "" Vector__XXX

BO_ 2364733950 HVESP22D3: 8 Vector__XXX
 SG_ Hvesp22HighestCellTemperature : 0|16@1+ (0.03125,-273) [-273|1734.96875] "degC" Vector__XXX
 SG_ Hvesp22LowestCellTemperature : 16|16@1+ (0.03125,-273) [-273|1734.96875] "degC" Vector__XXX
 SG_ Hvesp22AverageCellTemperature : 32|16@1+ (0.03125,-273) [-273|1734.96875] "degC" Vector__XXX
 SG_ Hvsp22CllTmprtrDffrntlStts : 48|2@1+ (1,0) [0|3] "" Vector__XXX

BO_ 2364734206 HVESP22D4: 8 Vector__XXX
 SG_ Hvesp22DischargeCapacity : 0|16@1+ (0.01,0) [0|642.55] "Ah" Vector__XXX
 SG_ Hvesp22ChargeCapacity : 16|16@1+ (0.01,0) [0|642.55] "Ah" Vector__XXX
 SG_ Hvesp22CellBalancingCount : 32|16@1+ (1,0) [0|64255] "count" Vector__XXX

BO_ 2364734462 HVESP22D5: 8 Vector__XXX
 SG_ Hvesp22LowestCellStateOfCharge : 32|16@1+ (0.0015625,0) [0|100.3984375] "%" Vector__XXX
 SG_ Hvesp22HighestCellStateOfCharge : 48|16@1+ (0.0015625,0) [0|100.3984375] "%" Vector__XXX
 SG_ Hvsp22MxmmInstntnsDshrgCrrntLmt : 0|16@1+ (0.05,-1600) [-1600|0] "A" Vector__XXX
 SG_ Hvsp22MxmmInstntnsChrgCrrntLmt : 16|16@1+ (0.05,-1600) [0|1612.75] "A" Vector__XXX

BO_ 2364734718 HVESP22D6: 8 Vector__XXX
 SG_ Hvesp22BusVoltage : 0|16@1+ (0.05,0) [0|3212.75] "V" Vector__XXX
 SG_ Hvesp22IgnitionVoltage : 16|16@1+ (0.01,0) [0|642.55] "V" Vector__XXX
 SG_ Hvesp22IntakeCoolantTemperature : 32|8@1+ (1,-40) [-40|210] "degC" Vector__XXX
 SG_ Hvesp22OutletCoolantTemperature : 40|8@1+ (1,-40) [-40|210] "degC" Vector__XXX
 SG_ Hvesp22ElectronicsTemperature : 48|8@1+ (1,-40) [-40|210] "degC" Vector__XXX
 SG_ Hvesp22Temperature : 56|8@1+ (1,-40) [-40|210] "degC" Vector__XXX

BO_ 2364734974 HVESP22S1: 8 Vector__XXX
 SG_ Hvsp22HghVltgBsPstvCnttrStt : 0|2@1+ (1,0) [0|3] "" Vector__XXX
 SG_ Hvsp22HghVltgBsNgtvCnttrStt : 2|2@1+ (1,0) [0|3] "" Vector__XXX
 SG_ Hvsp22HghVltgBsDsnntFrwrnng : 4|4@1+ (1,0) [0|15] "" Vector__XXX
 SG_ Hvsp22HghVltgBsPrChrgRlStt : 8|2@1+ (1,0) [0|3] "" Vector__XXX
 SG_ Hvsp22CntrOfPkCnttrStt : 10|2@1+ (1,0) [0|3] "" Vector__XXX
 SG_ Hvsp22HghVltgBsAtvIsltnTstStts : 12|4@1+ (1,0) [0|15] "" Vector__XXX
 SG_ Hvsp22HghVltgBsPssvIsltnTstStts : 16|4@1+ (1,0) [0|15] "" Vector__XXX
 SG_ Hvesp22HvilStatus : 20|2@1+ (1,0) [0|3] "" Vector__XXX
 SG_ Hvesp22InertiaSwitchStatus : 22|2@1+ (1,0) [0|3] "" Vector__XXX
 SG_ Hvesp22StateOfChargeStatus : 24|4@1+ (1,0) [0|15] "" Vector__XXX
 SG_ Hvesp22CellBalanceStatus : 28|2@1+ (1,0) [0|3] "" Vector__XXX
 SG_ Hvesp22CellBalancingActive : 30|2@1+ (1,0) [0|3] "" Vector__XXX
 SG_ Hvesp22InternalChargerStatus : 32|2@1+ (1,0) [0|3] "" Vector__XXX
 SG_ Hvsp22HghVltgBsCnntnStts : 40|4@1+ (1,0) [0|15] "" Vector__XXX
 SG_ Hvesp22OperationalStatus : 44|4@1+ (1,0) [0|15] "" Vector__XXX
 SG_ Hvesp22Status1Counter : 52|4@1+ (1,0) [0|15] "" Vector__XXX
 SG_ Hvesp22Status1Crc : 56|8@1+ (1,0) [0|250] "count" Vector__XXX

BO_ 2364735230 HVESP22D7: 8 Vector__XXX
 SG_ Hvesp22DischargeEnergyCapacity : 0|24@1+ (0.001,0) [0|16449.535] "kWh" Vector__XXX
 SG_ Hvesp22ChargeEnergyCapacity : 24|24@1+ (0.001,0) [0|16449.535] "kWh" Vector__XXX
 SG_ Hvsp22MxmmChrgVltgLmt : 48|16@1+ (0.05,0) [0|3212.75] "V" Vector__XXX

BO_ 2364735486 HVESP22MS1: 8 Vector__XXX
 SG_ Hvesp22Module1OperationalStatus : 0|2@1+ (1,0) [0|3] "" Vector__XXX
 SG_ Hvesp22Module2OperationalStatus : 2|2@1+ (1,0) [0|3] "" Vector__XXX
 SG_ Hvesp22Module3OperationalStatus : 4|2@1+ (1,0) [0|3] "" Vector__XXX
 SG_ Hvesp22Module4OperationalStatus : 6|2@1+ (1,0) [0|3] "" Vector__XXX
 SG_ Hvesp22Module5OperationalStatus : 8|2@1+ (1,0) [0|3] "" Vector__XXX
 SG_ Hvesp22Module6OperationalStatus : 10|2@1+ (1,0) [0|3] "" Vector__XXX
 SG_ Hvesp22Module7OperationalStatus : 12|2@1+ (1,0) [0|3] "" Vector__XXX
 SG_ Hvesp22Module8OperationalStatus : 14|2@1+ (1,0) [0|3] "" Vector__XXX
 SG_ Hvesp22Module9OperationalStatus : 16|2@1+ (1,0) [0|3] "" Vector__XXX
 SG_ Hvsp22Mdl10OprtnlStts : 18|2@1+ (1,0) [0|3] "" Vector__XXX
 SG_ Hvsp22Mdl11OprtnlStts : 20|2@1+ (1,0) [0|3] "" Vector__XXX
 SG_ Hvsp22Mdl12OprtnlStts : 22|2@1+ (1,0) [0|3] "" Vector__XXX
 SG_ Hvsp22Mdl13OprtnlStts : 24|2@1+ (1,0) [0|3] "" Vector__XXX
 SG_ Hvsp22Mdl14OprtnlStts : 26|2@1+ (1,0) [0|3] "" Vector__XXX
 SG_ Hvsp22Mdl15OprtnlStts : 28|2@1+ (1,0) [0|3] "" Vector__XXX
 SG_ Hvsp22Mdl16OprtnlStts : 30|2@1+ (1,0) [0|3] "" Vector__XXX
 SG_ Hvsp22Mdl17OprtnlStts : 32|2@1+ (1,0) [0|3] "" Vector__XXX
 SG_ Hvsp22Mdl18OprtnlStts : 34|2@1+ (1,0) [0|3] "" Vector__XXX
 SG_ Hvsp22Mdl19OprtnlStts : 36|2@1+ (1,0) [0|3] "" Vector__XXX
 SG_ Hvsp22Mdl20OprtnlStts : 38|2@1+ (1,0) [0|3] "" Vector__XXX
 SG_ Hvsp22Mdl21OprtnlStts : 40|2@1+ (1,0) [0|3] "" Vector__XXX
 SG_ Hvsp22Mdl22OprtnlStts : 42|2@1+ (1,0) [0|3] "" Vector__XXX
 SG_ Hvsp22Mdl23OprtnlStts : 44|2@1+ (1,0) [0|3] "" Vector__XXX
 SG_ Hvsp22Mdl24OprtnlStts : 46|2@1+ (1,0) [0|3] "" Vector__XXX
 SG_ Hvsp22Mdl25OprtnlStts : 48|2@1+ (1,0) [0|3] "" Vector__XXX
 SG_ Hvsp22Mdl26OprtnlStts : 50|2@1+ (1,0) [0|3] "" Vector__XXX
 SG_ Hvsp22Mdl27OprtnlStts : 52|2@1+ (1,0) [0|3] "" Vector__XXX
 SG_ Hvsp22Mdl28OprtnlStts : 54|2@1+ (1,0) [0|3] "" Vector__XXX
 SG_ Hvsp22Mdl29OprtnlStts : 56|2@1+ (1,0) [0|3] "" Vector__XXX
 SG_ Hvsp22Mdl30OprtnlStts : 58|2@1+ (1,0) [0|3] "" Vector__XXX
 SG_ Hvsp22Mdl31OprtnlStts : 60|2@1+ (1,0) [0|3] "" Vector__XXX
 SG_ Hvsp22Mdl32OprtnlStts : 62|2@1+ (1,0) [0|3] "" Vector__XXX

BO_ 2364735742 HVESP22TS1: 8 Vector__XXX
 SG_ Hvsp22ThrmlMngmntSstmSlInptPwr : 0|16@1+ (0.5,0) [0|32127.5] "W" Vector__XXX
 SG_ Hvsp22TMtSstHVtIptPw : 16|16@1+ (0.5,0) [0|32127.5] "W" Vector__XXX
 SG_ Hvsp22ThrmlMngmntSstmCmprssrSpd : 32|8@1+ (32,0) [0|8000] "rpm" Vector__XXX
 SG_ Hvsp22ThrmlMngmntSstmRltvHmdt : 40|8@1+ (0.4,0) [0|100] "%" Vector__XXX
 SG_ Hvsp22ThrmlMngmntSstmHtrStts : 48|2@1+ (1,0) [0|3] "" Vector__XXX
 SG_ Hvsp22ThrmlMngmntSstmHvlStts : 50|2@1+ (1,0) [0|3] "" Vector__XXX
 SG_ Hvsp22ThrmlMngmntSstmMd : 52|4@1+ (1,0) [0|15] "" Vector__XXX
 SG_ Hvsp22ThrmlMngmntSstmClntLvl : 56|2@1+ (1,0) [0|3] "" Vector__XXX

BO_ 2364735998 HVESP22D8: 8 Vector__XXX
 SG_ Hvsp22HghstCllVltgMdlNmr : 0|8@1+ (1,0) [0|250] "count" Vector__XXX
 SG_ Hvsp22HghstCllVltgCllNmr : 8|8@1+ (1,0) [0|250] "count" Vector__XXX
 SG_ Hvsp22LwstCllVltgMdlNmr : 16|8@1+ (1,0) [0|250] "count" Vector__XXX
 SG_ Hvsp22LwstCllVltgCllNmr : 24|8@1+ (1,0) [0|250] "count" Vector__XXX
 SG_ Hvesp22AverageCellVoltage : 32|16@1+ (0.001,0) [0|64.255] "V" Vector__XXX

BO_ 2364736254 HVESP22D9: 8 Vector__XXX
 SG_ Hvsp22HghstCllTmprtrMdlNmr : 0|8@1+ (1,0) [0|250] "count" Vector__XXX
 SG_ Hvsp22HghstCllTmprtrCllNmr : 8|8@1+ (1,0) [0|250] "count" Vector__XXX
 SG_ Hvsp22LwstCllTmprtrMdlNmr : 16|8@1+ (1,0) [0|250] "count" Vector__XXX
 SG_ Hvsp22LwstCllTmprtrCllNmr : 24|8@1+ (1,0) [0|250] "count" Vector__XXX
 SG_ Hvess22ThermalEventDetected : 32|2@1+ (1,0) [0|3] "" Vector__XXX
 SG_ Hvsp22Dt9EmdddIntgrtSpprt : 50|2@1+ (1,0) [0|3] "" Vector__XXX
 SG_ Hvesp22Data9Counter : 52|4@1+ (1,0) [0|15] "" Vector__XXX
 SG_ Hvesp22Data9Crc : 56|8@1+ (1,0) [0|250] "count" Vector__XXX

BO_ 2364736510 HVESP22D10: 8 Vector__XXX
 SG_ Hvsp22HghstCllSttOfChrgMdlNmr : 0|8@1+ (1,0) [0|250] "count" Vector__XXX
 SG_ Hvsp22HghstCllSttOfChrgCllNmr : 8|8@1+ (1,0) [0|250] "count" Vector__XXX
 SG_ Hvsp22LwstCllSttOfChrgMdlNmr : 16|8@1+ (1,0) [0|250] "count" Vector__XXX
 SG_ Hvsp22LwstCllSttOfChrgCllNmr : 24|8@1+ (1,0) [0|250] "count" Vector__XXX
 SG_ Hvsp22HghVltgBsAtvIsltnTstRslts : 32|16@1+ (0.1,0) [0|6425.5] "OhmPerV" Vector__XXX
 SG_ Hvsp22HVtBsPssvIstTstRsts : 48|16@1+ (0.1,0) [0|6425.5] "OhmPerV" Vector__XXX

BO_ 2364736766 HVESP22D11: 8 Vector__XXX
 SG_ Hvsp22BsVltgNgtvTChsssGrndVltg : 0|16@1+ (0.05,0) [0|3212.75] "V" Vector__XXX
 SG_ Hvsp22VltgLvlNgtvTChsssGrndVltg : 16|16@1+ (0.05,0) [0|3212.75] "V" Vector__XXX
 SG_ Hvesp22ActualChargeRate : 32|16@1+ (0.05,0) [0|3212.75] "kW" Vector__XXX

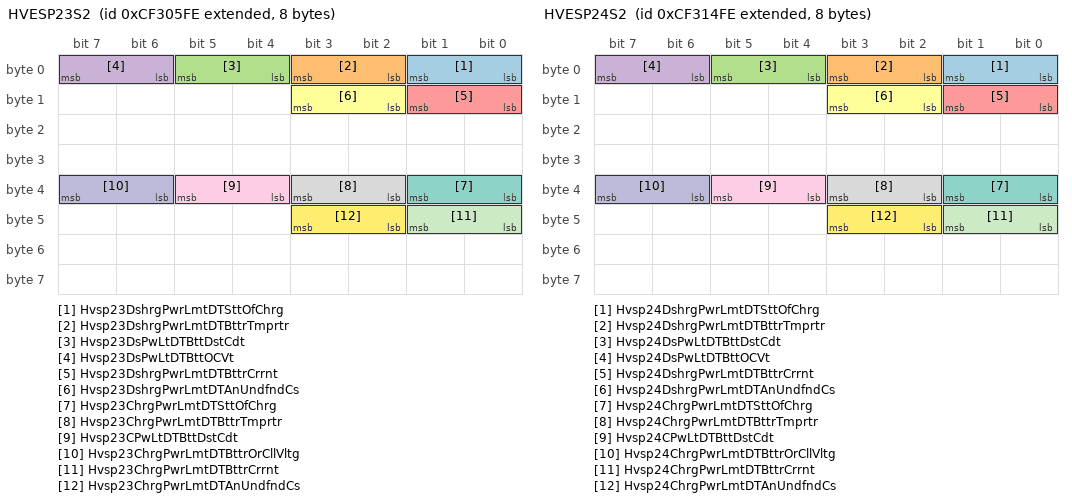
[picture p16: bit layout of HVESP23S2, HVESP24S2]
BO_ 2364737022 HVESP23S2: 8 Vector__XXX
 SG_ Hvsp23DshrgPwrLmtDTSttOfChrg : 0|2@1+ (1,0) [0|3] "" Vector__XXX
 SG_ Hvsp23DshrgPwrLmtDTBttrTmprtr : 2|2@1+ (1,0) [0|3] "" Vector__XXX
 SG_ Hvsp23DsPwLtDTBttDstCdt : 4|2@1+ (1,0) [0|3] "" Vector__XXX
 SG_ Hvsp23DsPwLtDTBttOCVt : 6|2@1+ (1,0) [0|3] "" Vector__XXX
 SG_ Hvsp23DshrgPwrLmtDTBttrCrrnt : 8|2@1+ (1,0) [0|3] "" Vector__XXX
 SG_ Hvsp23DshrgPwrLmtDTAnUndfndCs : 10|2@1+ (1,0) [0|3] "" Vector__XXX
 SG_ Hvsp23ChrgPwrLmtDTSttOfChrg : 32|2@1+ (1,0) [0|3] "" Vector__XXX
 SG_ Hvsp23ChrgPwrLmtDTBttrTmprtr : 34|2@1+ (1,0) [0|3] "" Vector__XXX
 SG_ Hvsp23CPwLtDTBttDstCdt : 36|2@1+ (1,0) [0|3] "" Vector__XXX
 SG_ Hvsp23ChrgPwrLmtDTBttrOrCllVltg : 38|2@1+ (1,0) [0|3] "" Vector__XXX
 SG_ Hvsp23ChrgPwrLmtDTBttrCrrnt : 40|2@1+ (1,0) [0|3] "" Vector__XXX
 SG_ Hvsp23ChrgPwrLmtDTAnUndfndCs : 42|2@1+ (1,0) [0|3] "" Vector__XXX

BO_ 2364737278 HVESP23D1: 8 Vector__XXX
 SG_ Hvesp23AvailableDischargePower : 0|16@1+ (0.05,0) [0|3212.75] "kW" Vector__XXX
 SG_ Hvesp23AvailableChargePower : 16|16@1+ (0.05,0) [0|3212.75] "kW" Vector__XXX
 SG_ Hvesp23VoltageLevel : 32|16@1+ (0.05,0) [0|3212.75] "V" Vector__XXX
 SG_ Hvesp23Current : 48|16@1+ (0.05,-1600) [-1600|1612.75] "A" Vector__XXX

BO_ 2364737534 HVESP23D2: 8 Vector__XXX
 SG_ Hvesp23FastUpdateStateOfCharge : 0|16@1+ (0.0015625,0) [0|100.3984375] "%" Vector__XXX
 SG_ Hvesp23HighestCellVoltage : 16|16@1+ (0.001,0) [0|64.255] "V" Vector__XXX
 SG_ Hvesp23LowestCellVoltage : 32|16@1+ (0.001,0) [0|64.255] "V" Vector__XXX
 SG_ Hvsp23CllVltgDffrntlStts : 48|4@1+ (1,0) [0|15] "" Vector__XXX

BO_ 2364737790 HVESP23D3: 8 Vector__XXX
 SG_ Hvesp23HighestCellTemperature : 0|16@1+ (0.03125,-273) [-273|1734.96875] "degC" Vector__XXX
 SG_ Hvesp23LowestCellTemperature : 16|16@1+ (0.03125,-273) [-273|1734.96875] "degC" Vector__XXX
 SG_ Hvesp23AverageCellTemperature : 32|16@1+ (0.03125,-273) [-273|1734.96875] "degC" Vector__XXX
 SG_ Hvsp23CllTmprtrDffrntlStts : 48|2@1+ (1,0) [0|3] "" Vector__XXX

BO_ 2364738046 HVESP23D4: 8 Vector__XXX
 SG_ Hvesp23DischargeCapacity : 0|16@1+ (0.01,0) [0|642.55] "Ah" Vector__XXX
 SG_ Hvesp23ChargeCapacity : 16|16@1+ (0.01,0) [0|642.55] "Ah" Vector__XXX
 SG_ Hvesp23CellBalancingCount : 32|16@1+ (1,0) [0|64255] "count" Vector__XXX

BO_ 2364738302 HVESP23D5: 8 Vector__XXX
 SG_ Hvesp23LowestCellStateOfCharge : 32|16@1+ (0.0015625,0) [0|100.3984375] "%" Vector__XXX
 SG_ Hvesp23HighestCellStateOfCharge : 48|16@1+ (0.0015625,0) [0|100.3984375] "%" Vector__XXX
 SG_ Hvsp23MxmmInstntnsDshrgCrrntLmt : 0|16@1+ (0.05,-1600) [-1600|0] "A" Vector__XXX
 SG_ Hvsp23MxmmInstntnsChrgCrrntLmt : 16|16@1+ (0.05,-1600) [0|1612.75] "A" Vector__XXX

BO_ 2364738558 HVESP23D6: 8 Vector__XXX
 SG_ Hvesp23BusVoltage : 0|16@1+ (0.05,0) [0|3212.75] "V" Vector__XXX
 SG_ Hvesp23IgnitionVoltage : 16|16@1+ (0.01,0) [0|642.55] "V" Vector__XXX
 SG_ Hvesp23IntakeCoolantTemperature : 32|8@1+ (1,-40) [-40|210] "degC" Vector__XXX
 SG_ Hvesp23OutletCoolantTemperature : 40|8@1+ (1,-40) [-40|210] "degC" Vector__XXX
 SG_ Hvesp23ElectronicsTemperature : 48|8@1+ (1,-40) [-40|210] "degC" Vector__XXX
 SG_ Hvesp23Temperature : 56|8@1+ (1,-40) [-40|210] "degC" Vector__XXX

BO_ 2364738814 HVESP23S1: 8 Vector__XXX
 SG_ Hvsp23HghVltgBsPstvCnttrStt : 0|2@1+ (1,0) [0|3] "" Vector__XXX
 SG_ Hvsp23HghVltgBsNgtvCnttrStt : 2|2@1+ (1,0) [0|3] "" Vector__XXX
 SG_ Hvsp23HghVltgBsDsnntFrwrnng : 4|4@1+ (1,0) [0|15] "" Vector__XXX
 SG_ Hvsp23HghVltgBsPrChrgRlStt : 8|2@1+ (1,0) [0|3] "" Vector__XXX
 SG_ Hvsp23CntrOfPkCnttrStt : 10|2@1+ (1,0) [0|3] "" Vector__XXX
 SG_ Hvsp23HghVltgBsAtvIsltnTstStts : 12|4@1+ (1,0) [0|15] "" Vector__XXX
 SG_ Hvsp23HghVltgBsPssvIsltnTstStts : 16|4@1+ (1,0) [0|15] "" Vector__XXX
 SG_ Hvesp23HvilStatus : 20|2@1+ (1,0) [0|3] "" Vector__XXX
 SG_ Hvesp23InertiaSwitchStatus : 22|2@1+ (1,0) [0|3] "" Vector__XXX
 SG_ Hvesp23StateOfChargeStatus : 24|4@1+ (1,0) [0|15] "" Vector__XXX
 SG_ Hvesp23CellBalanceStatus : 28|2@1+ (1,0) [0|3] "" Vector__XXX
 SG_ Hvesp23CellBalancingActive : 30|2@1+ (1,0) [0|3] "" Vector__XXX
 SG_ Hvesp23InternalChargerStatus : 32|2@1+ (1,0) [0|3] "" Vector__XXX
 SG_ Hvsp23HghVltgBsCnntnStts : 40|4@1+ (1,0) [0|15] "" Vector__XXX
 SG_ Hvesp23OperationalStatus : 44|4@1+ (1,0) [0|15] "" Vector__XXX
 SG_ Hvesp23Status1Counter : 52|4@1+ (1,0) [0|15] "" Vector__XXX
 SG_ Hvesp23Status1Crc : 56|8@1+ (1,0) [0|250] "count" Vector__XXX

BO_ 2364739070 HVESP23D7: 8 Vector__XXX
 SG_ Hvesp23DischargeEnergyCapacity : 0|24@1+ (0.001,0) [0|16449.535] "kWh" Vector__XXX
 SG_ Hvesp23ChargeEnergyCapacity : 24|24@1+ (0.001,0) [0|16449.535] "kWh" Vector__XXX
 SG_ Hvsp23MxmmChrgVltgLmt : 48|16@1+ (0.05,0) [0|3212.75] "V" Vector__XXX

BO_ 2364739326 HVESP23MS1: 8 Vector__XXX
 SG_ Hvesp23Module1OperationalStatus : 0|2@1+ (1,0) [0|3] "" Vector__XXX
 SG_ Hvesp23Module2OperationalStatus : 2|2@1+ (1,0) [0|3] "" Vector__XXX
 SG_ Hvesp23Module3OperationalStatus : 4|2@1+ (1,0) [0|3] "" Vector__XXX
 SG_ Hvesp23Module4OperationalStatus : 6|2@1+ (1,0) [0|3] "" Vector__XXX
 SG_ Hvesp23Module5OperationalStatus : 8|2@1+ (1,0) [0|3] "" Vector__XXX
 SG_ Hvesp23Module6OperationalStatus : 10|2@1+ (1,0) [0|3] "" Vector__XXX
 SG_ Hvesp23Module7OperationalStatus : 12|2@1+ (1,0) [0|3] "" Vector__XXX
 SG_ Hvesp23Module8OperationalStatus : 14|2@1+ (1,0) [0|3] "" Vector__XXX
 SG_ Hvesp23Module9OperationalStatus : 16|2@1+ (1,0) [0|3] "" Vector__XXX
 SG_ Hvsp23Mdl10OprtnlStts : 18|2@1+ (1,0) [0|3] "" Vector__XXX
 SG_ Hvsp23Mdl11OprtnlStts : 20|2@1+ (1,0) [0|3] "" Vector__XXX
 SG_ Hvsp23Mdl12OprtnlStts : 22|2@1+ (1,0) [0|3] "" Vector__XXX
 SG_ Hvsp23Mdl13OprtnlStts : 24|2@1+ (1,0) [0|3] "" Vector__XXX
 SG_ Hvsp23Mdl14OprtnlStts : 26|2@1+ (1,0) [0|3] "" Vector__XXX
 SG_ Hvsp23Mdl15OprtnlStts : 28|2@1+ (1,0) [0|3] "" Vector__XXX
 SG_ Hvsp23Mdl16OprtnlStts : 30|2@1+ (1,0) [0|3] "" Vector__XXX
 SG_ Hvsp23Mdl17OprtnlStts : 32|2@1+ (1,0) [0|3] "" Vector__XXX
 SG_ Hvsp23Mdl18OprtnlStts : 34|2@1+ (1,0) [0|3] "" Vector__XXX
 SG_ Hvsp23Mdl19OprtnlStts : 36|2@1+ (1,0) [0|3] "" Vector__XXX
 SG_ Hvsp23Mdl20OprtnlStts : 38|2@1+ (1,0) [0|3] "" Vector__XXX
 SG_ Hvsp23Mdl21OprtnlStts : 40|2@1+ (1,0) [0|3] "" Vector__XXX
 SG_ Hvsp23Mdl22OprtnlStts : 42|2@1+ (1,0) [0|3] "" Vector__XXX
 SG_ Hvsp23Mdl23OprtnlStts : 44|2@1+ (1,0) [0|3] "" Vector__XXX
 SG_ Hvsp23Mdl24OprtnlStts : 46|2@1+ (1,0) [0|3] "" Vector__XXX
 SG_ Hvsp23Mdl25OprtnlStts : 48|2@1+ (1,0) [0|3] "" Vector__XXX
 SG_ Hvsp23Mdl26OprtnlStts : 50|2@1+ (1,0) [0|3] "" Vector__XXX
 SG_ Hvsp23Mdl27OprtnlStts : 52|2@1+ (1,0) [0|3] "" Vector__XXX
 SG_ Hvsp23Mdl28OprtnlStts : 54|2@1+ (1,0) [0|3] "" Vector__XXX
 SG_ Hvsp23Mdl29OprtnlStts : 56|2@1+ (1,0) [0|3] "" Vector__XXX
 SG_ Hvsp23Mdl30OprtnlStts : 58|2@1+ (1,0) [0|3] "" Vector__XXX
 SG_ Hvsp23Mdl31OprtnlStts : 60|2@1+ (1,0) [0|3] "" Vector__XXX
 SG_ Hvsp23Mdl32OprtnlStts : 62|2@1+ (1,0) [0|3] "" Vector__XXX

BO_ 2364739582 HVESP23TS1: 8 Vector__XXX
 SG_ Hvsp23ThrmlMngmntSstmSlInptPwr : 0|16@1+ (0.5,0) [0|32127.5] "W" Vector__XXX
 SG_ Hvsp23TMtSstHVtIptPw : 16|16@1+ (0.5,0) [0|32127.5] "W" Vector__XXX
 SG_ Hvsp23ThrmlMngmntSstmCmprssrSpd : 32|8@1+ (32,0) [0|8000] "rpm" Vector__XXX
 SG_ Hvsp23ThrmlMngmntSstmRltvHmdt : 40|8@1+ (0.4,0) [0|100] "%" Vector__XXX
 SG_ Hvsp23ThrmlMngmntSstmHtrStts : 48|2@1+ (1,0) [0|3] "" Vector__XXX
 SG_ Hvsp23ThrmlMngmntSstmHvlStts : 50|2@1+ (1,0) [0|3] "" Vector__XXX
 SG_ Hvsp23ThrmlMngmntSstmMd : 52|4@1+ (1,0) [0|15] "" Vector__XXX
 SG_ Hvsp23ThrmlMngmntSstmClntLvl : 56|2@1+ (1,0) [0|3] "" Vector__XXX

BO_ 2364739838 HVESP23D8: 8 Vector__XXX
 SG_ Hvsp23HghstCllVltgMdlNmr : 0|8@1+ (1,0) [0|250] "count" Vector__XXX
 SG_ Hvsp23HghstCllVltgCllNmr : 8|8@1+ (1,0) [0|250] "count" Vector__XXX
 SG_ Hvsp23LwstCllVltgMdlNmr : 16|8@1+ (1,0) [0|250] "count" Vector__XXX
 SG_ Hvsp23LwstCllVltgCllNmr : 24|8@1+ (1,0) [0|250] "count" Vector__XXX
 SG_ Hvesp23AverageCellVoltage : 32|16@1+ (0.001,0) [0|64.255] "V" Vector__XXX

BO_ 2364740094 HVESP23D9: 8 Vector__XXX
 SG_ Hvsp23HghstCllTmprtrMdlNmr : 0|8@1+ (1,0) [0|250] "count" Vector__XXX
 SG_ Hvsp23HghstCllTmprtrCllNmr : 8|8@1+ (1,0) [0|250] "count" Vector__XXX
 SG_ Hvsp23LwstCllTmprtrMdlNmr : 16|8@1+ (1,0) [0|250] "count" Vector__XXX
 SG_ Hvsp23LwstCllTmprtrCllNmr : 24|8@1+ (1,0) [0|250] "count" Vector__XXX
 SG_ Hvess23ThermalEventDetected : 32|2@1+ (1,0) [0|3] "" Vector__XXX
 SG_ Hvsp23Dt9EmdddIntgrtSpprt : 50|2@1+ (1,0) [0|3] "" Vector__XXX
 SG_ Hvesp23Data9Counter : 52|4@1+ (1,0) [0|15] "" Vector__XXX
 SG_ Hvesp23Data9Crc : 56|8@1+ (1,0) [0|250] "count" Vector__XXX

BO_ 2364740350 HVESP23D10: 8 Vector__XXX
 SG_ Hvsp23HghstCllSttOfChrgMdlNmr : 0|8@1+ (1,0) [0|250] "count" Vector__XXX
 SG_ Hvsp23HghstCllSttOfChrgCllNmr : 8|8@1+ (1,0) [0|250] "count" Vector__XXX
 SG_ Hvsp23LwstCllSttOfChrgMdlNmr : 16|8@1+ (1,0) [0|250] "count" Vector__XXX
 SG_ Hvsp23LwstCllSttOfChrgCllNmr : 24|8@1+ (1,0) [0|250] "count" Vector__XXX
 SG_ Hvsp23HghVltgBsAtvIsltnTstRslts : 32|16@1+ (0.1,0) [0|6425.5] "OhmPerV" Vector__XXX
 SG_ Hvsp23HVtBsPssvIstTstRsts : 48|16@1+ (0.1,0) [0|6425.5] "OhmPerV" Vector__XXX

BO_ 2364740606 HVESP23D11: 8 Vector__XXX
 SG_ Hvsp23BsVltgNgtvTChsssGrndVltg : 0|16@1+ (0.05,0) [0|3212.75] "V" Vector__XXX
 SG_ Hvsp23VltgLvlNgtvTChsssGrndVltg : 16|16@1+ (0.05,0) [0|3212.75] "V" Vector__XXX
 SG_ Hvesp23ActualChargeRate : 32|16@1+ (0.05,0) [0|3212.75] "kW" Vector__XXX

BO_ 2364740862 HVESP24S2: 8 Vector__XXX
 SG_ Hvsp24DshrgPwrLmtDTSttOfChrg : 0|2@1+ (1,0) [0|3] "" Vector__XXX
 SG_ Hvsp24DshrgPwrLmtDTBttrTmprtr : 2|2@1+ (1,0) [0|3] "" Vector__XXX
 SG_ Hvsp24DsPwLtDTBttDstCdt : 4|2@1+ (1,0) [0|3] "" Vector__XXX
 SG_ Hvsp24DsPwLtDTBttOCVt : 6|2@1+ (1,0) [0|3] "" Vector__XXX
 SG_ Hvsp24DshrgPwrLmtDTBttrCrrnt : 8|2@1+ (1,0) [0|3] "" Vector__XXX
 SG_ Hvsp24DshrgPwrLmtDTAnUndfndCs : 10|2@1+ (1,0) [0|3] "" Vector__XXX
 SG_ Hvsp24ChrgPwrLmtDTSttOfChrg : 32|2@1+ (1,0) [0|3] "" Vector__XXX
 SG_ Hvsp24ChrgPwrLmtDTBttrTmprtr : 34|2@1+ (1,0) [0|3] "" Vector__XXX
 SG_ Hvsp24CPwLtDTBttDstCdt : 36|2@1+ (1,0) [0|3] "" Vector__XXX
 SG_ Hvsp24ChrgPwrLmtDTBttrOrCllVltg : 38|2@1+ (1,0) [0|3] "" Vector__XXX
 SG_ Hvsp24ChrgPwrLmtDTBttrCrrnt : 40|2@1+ (1,0) [0|3] "" Vector__XXX
 SG_ Hvsp24ChrgPwrLmtDTAnUndfndCs : 42|2@1+ (1,0) [0|3] "" Vector__XXX

BO_ 2364741118 HVESP24D1: 8 Vector__XXX
 SG_ Hvesp24AvailableDischargePower : 0|16@1+ (0.05,0) [0|3212.75] "kW" Vector__XXX
 SG_ Hvesp24AvailableChargePower : 16|16@1+ (0.05,0) [0|3212.75] "kW" Vector__XXX
 SG_ Hvesp24VoltageLevel : 32|16@1+ (0.05,0) [0|3212.75] "V" Vector__XXX
 SG_ Hvesp24Current : 48|16@1+ (0.05,-1600) [-1600|1612.75] "A" Vector__XXX

BO_ 2364741374 HVESP24D2: 8 Vector__XXX
 SG_ Hvesp24FastUpdateStateOfCharge : 0|16@1+ (0.0015625,0) [0|100.3984375] "%" Vector__XXX
 SG_ Hvesp24HighestCellVoltage : 16|16@1+ (0.001,0) [0|64.255] "V" Vector__XXX
 SG_ Hvesp24LowestCellVoltage : 32|16@1+ (0.001,0) [0|64.255] "V" Vector__XXX
 SG_ Hvsp24CllVltgDffrntlStts : 48|4@1+ (1,0) [0|15] "" Vector__XXX

BO_ 2364741630 HVESP24D3: 8 Vector__XXX
 SG_ Hvesp24HighestCellTemperature : 0|16@1+ (0.03125,-273) [-273|1734.96875] "degC" Vector__XXX
 SG_ Hvesp24LowestCellTemperature : 16|16@1+ (0.03125,-273) [-273|1734.96875] "degC" Vector__XXX
 SG_ Hvesp24AverageCellTemperature : 32|16@1+ (0.03125,-273) [-273|1734.96875] "degC" Vector__XXX
 SG_ Hvsp24CllTmprtrDffrntlStts : 48|2@1+ (1,0) [0|3] "" Vector__XXX

BO_ 2364741886 HVESP24D4: 8 Vector__XXX
 SG_ Hvesp24DischargeCapacity : 0|16@1+ (0.01,0) [0|642.55] "Ah" Vector__XXX
 SG_ Hvesp24ChargeCapacity : 16|16@1+ (0.01,0) [0|642.55] "Ah" Vector__XXX
 SG_ Hvesp24CellBalancingCount : 32|16@1+ (1,0) [0|64255] "count" Vector__XXX

BO_ 2364742142 HVESP24D5: 8 Vector__XXX
 SG_ Hvesp24LowestCellStateOfCharge : 32|16@1+ (0.0015625,0) [0|100.3984375] "%" Vector__XXX
 SG_ Hvesp24HighestCellStateOfCharge : 48|16@1+ (0.0015625,0) [0|100.3984375] "%" Vector__XXX
 SG_ Hvsp24MxmmInstntnsDshrgCrrntLmt : 0|16@1+ (0.05,-1600) [-1600|0] "A" Vector__XXX
 SG_ Hvsp24MxmmInstntnsChrgCrrntLmt : 16|16@1+ (0.05,-1600) [0|1612.75] "A" Vector__XXX

BO_ 2364742398 HVESP24D6: 8 Vector__XXX
 SG_ Hvesp24BusVoltage : 0|16@1+ (0.05,0) [0|3212.75] "V" Vector__XXX
 SG_ Hvesp24IgnitionVoltage : 16|16@1+ (0.01,0) [0|642.55] "V" Vector__XXX
 SG_ Hvesp24IntakeCoolantTemperature : 32|8@1+ (1,-40) [-40|210] "degC" Vector__XXX
 SG_ Hvesp24OutletCoolantTemperature : 40|8@1+ (1,-40) [-40|210] "degC" Vector__XXX
 SG_ Hvesp24ElectronicsTemperature : 48|8@1+ (1,-40) [-40|210] "degC" Vector__XXX
 SG_ Hvesp24Temperature : 56|8@1+ (1,-40) [-40|210] "degC" Vector__XXX

BO_ 2364742654 HVESP24S1: 8 Vector__XXX
 SG_ Hvsp24HghVltgBsPstvCnttrStt : 0|2@1+ (1,0) [0|3] "" Vector__XXX
 SG_ Hvsp24HghVltgBsNgtvCnttrStt : 2|2@1+ (1,0) [0|3] "" Vector__XXX
 SG_ Hvsp24HghVltgBsDsnntFrwrnng : 4|4@1+ (1,0) [0|15] "" Vector__XXX
 SG_ Hvsp24HghVltgBsPrChrgRlStt : 8|2@1+ (1,0) [0|3] "" Vector__XXX
 SG_ Hvsp24CntrOfPkCnttrStt : 10|2@1+ (1,0) [0|3] "" Vector__XXX
 SG_ Hvsp24HghVltgBsAtvIsltnTstStts : 12|4@1+ (1,0) [0|15] "" Vector__XXX
 SG_ Hvsp24HghVltgBsPssvIsltnTstStts : 16|4@1+ (1,0) [0|15] "" Vector__XXX
 SG_ Hvesp24HvilStatus : 20|2@1+ (1,0) [0|3] "" Vector__XXX
 SG_ Hvesp24InertiaSwitchStatus : 22|2@1+ (1,0) [0|3] "" Vector__XXX
 SG_ Hvesp24StateOfChargeStatus : 24|4@1+ (1,0) [0|15] "" Vector__XXX
 SG_ Hvesp24CellBalanceStatus : 28|2@1+ (1,0) [0|3] "" Vector__XXX
 SG_ Hvesp24CellBalancingActive : 30|2@1+ (1,0) [0|3] "" Vector__XXX
 SG_ Hvesp24InternalChargerStatus : 32|2@1+ (1,0) [0|3] "" Vector__XXX
 SG_ Hvsp24HghVltgBsCnntnStts : 40|4@1+ (1,0) [0|15] "" Vector__XXX
 SG_ Hvesp24OperationalStatus : 44|4@1+ (1,0) [0|15] "" Vector__XXX
 SG_ Hvesp24Status1Counter : 52|4@1+ (1,0) [0|15] "" Vector__XXX
 SG_ Hvesp24Status1Crc : 56|8@1+ (1,0) [0|250] "count" Vector__XXX

BO_ 2364742910 HVESP24D7: 8 Vector__XXX
 SG_ Hvesp24DischargeEnergyCapacity : 0|24@1+ (0.001,0) [0|16449.535] "kWh" Vector__XXX
 SG_ Hvesp24ChargeEnergyCapacity : 24|24@1+ (0.001,0) [0|16449.535] "kWh" Vector__XXX
 SG_ Hvsp24MxmmChrgVltgLmt : 48|16@1+ (0.05,0) [0|3212.75] "V" Vector__XXX

BO_ 2364743166 HVESP24MS1: 8 Vector__XXX
 SG_ Hvesp24Module1OperationalStatus : 0|2@1+ (1,0) [0|3] "" Vector__XXX
 SG_ Hvesp24Module2OperationalStatus : 2|2@1+ (1,0) [0|3] "" Vector__XXX
 SG_ Hvesp24Module3OperationalStatus : 4|2@1+ (1,0) [0|3] "" Vector__XXX
 SG_ Hvesp24Module4OperationalStatus : 6|2@1+ (1,0) [0|3] "" Vector__XXX
 SG_ Hvesp24Module5OperationalStatus : 8|2@1+ (1,0) [0|3] "" Vector__XXX
 SG_ Hvesp24Module6OperationalStatus : 10|2@1+ (1,0) [0|3] "" Vector__XXX
 SG_ Hvesp24Module7OperationalStatus : 12|2@1+ (1,0) [0|3] "" Vector__XXX
 SG_ Hvesp24Module8OperationalStatus : 14|2@1+ (1,0) [0|3] "" Vector__XXX
 SG_ Hvesp24Module9OperationalStatus : 16|2@1+ (1,0) [0|3] "" Vector__XXX
 SG_ Hvsp24Mdl10OprtnlStts : 18|2@1+ (1,0) [0|3] "" Vector__XXX
 SG_ Hvsp24Mdl11OprtnlStts : 20|2@1+ (1,0) [0|3] "" Vector__XXX
 SG_ Hvsp24Mdl12OprtnlStts : 22|2@1+ (1,0) [0|3] "" Vector__XXX
 SG_ Hvsp24Mdl13OprtnlStts : 24|2@1+ (1,0) [0|3] "" Vector__XXX
 SG_ Hvsp24Mdl14OprtnlStts : 26|2@1+ (1,0) [0|3] "" Vector__XXX
 SG_ Hvsp24Mdl15OprtnlStts : 28|2@1+ (1,0) [0|3] "" Vector__XXX
 SG_ Hvsp24Mdl16OprtnlStts : 30|2@1+ (1,0) [0|3] "" Vector__XXX
 SG_ Hvsp24Mdl17OprtnlStts : 32|2@1+ (1,0) [0|3] "" Vector__XXX
 SG_ Hvsp24Mdl18OprtnlStts : 34|2@1+ (1,0) [0|3] "" Vector__XXX
 SG_ Hvsp24Mdl19OprtnlStts : 36|2@1+ (1,0) [0|3] "" Vector__XXX
 SG_ Hvsp24Mdl20OprtnlStts : 38|2@1+ (1,0) [0|3] "" Vector__XXX
 SG_ Hvsp24Mdl21OprtnlStts : 40|2@1+ (1,0) [0|3] "" Vector__XXX
 SG_ Hvsp24Mdl22OprtnlStts : 42|2@1+ (1,0) [0|3] "" Vector__XXX
 SG_ Hvsp24Mdl23OprtnlStts : 44|2@1+ (1,0) [0|3] "" Vector__XXX
 SG_ Hvsp24Mdl24OprtnlStts : 46|2@1+ (1,0) [0|3] "" Vector__XXX
 SG_ Hvsp24Mdl25OprtnlStts : 48|2@1+ (1,0) [0|3] "" Vector__XXX
 SG_ Hvsp24Mdl26OprtnlStts : 50|2@1+ (1,0) [0|3] "" Vector__XXX
 SG_ Hvsp24Mdl27OprtnlStts : 52|2@1+ (1,0) [0|3] "" Vector__XXX
 SG_ Hvsp24Mdl28OprtnlStts : 54|2@1+ (1,0) [0|3] "" Vector__XXX
 SG_ Hvsp24Mdl29OprtnlStts : 56|2@1+ (1,0) [0|3] "" Vector__XXX
 SG_ Hvsp24Mdl30OprtnlStts : 58|2@1+ (1,0) [0|3] "" Vector__XXX
 SG_ Hvsp24Mdl31OprtnlStts : 60|2@1+ (1,0) [0|3] "" Vector__XXX
 SG_ Hvsp24Mdl32OprtnlStts : 62|2@1+ (1,0) [0|3] "" Vector__XXX

BO_ 2364743422 HVESP24TS1: 8 Vector__XXX
 SG_ Hvsp24ThrmlMngmntSstmSlInptPwr : 0|16@1+ (0.5,0) [0|32127.5] "W" Vector__XXX
 SG_ Hvsp24TMtSstHVtIptPw : 16|16@1+ (0.5,0) [0|32127.5] "W" Vector__XXX
 SG_ Hvsp24ThrmlMngmntSstmCmprssrSpd : 32|8@1+ (32,0) [0|8000] "rpm" Vector__XXX
 SG_ Hvsp24ThrmlMngmntSstmRltvHmdt : 40|8@1+ (0.4,0) [0|100] "%" Vector__XXX
 SG_ Hvsp24ThrmlMngmntSstmHtrStts : 48|2@1+ (1,0) [0|3] "" Vector__XXX
 SG_ Hvsp24ThrmlMngmntSstmHvlStts : 50|2@1+ (1,0) [0|3] "" Vector__XXX
 SG_ Hvsp24ThrmlMngmntSstmMd : 52|4@1+ (1,0) [0|15] "" Vector__XXX
 SG_ Hvsp24ThrmlMngmntSstmClntLvl : 56|2@1+ (1,0) [0|3] "" Vector__XXX

BO_ 2364743678 HVESP24D8: 8 Vector__XXX
 SG_ Hvsp24HghstCllVltgMdlNmr : 0|8@1+ (1,0) [0|250] "count" Vector__XXX
 SG_ Hvsp24HghstCllVltgCllNmr : 8|8@1+ (1,0) [0|250] "count" Vector__XXX
 SG_ Hvsp24LwstCllVltgMdlNmr : 16|8@1+ (1,0) [0|250] "count" Vector__XXX
 SG_ Hvsp24LwstCllVltgCllNmr : 24|8@1+ (1,0) [0|250] "count" Vector__XXX
 SG_ Hvesp24AverageCellVoltage : 32|16@1+ (0.001,0) [0|64.255] "V" Vector__XXX

BO_ 2364743934 HVESP24D9: 8 Vector__XXX
 SG_ Hvsp24HghstCllTmprtrMdlNmr : 0|8@1+ (1,0) [0|250] "count" Vector__XXX
 SG_ Hvsp24HghstCllTmprtrCllNmr : 8|8@1+ (1,0) [0|250] "count" Vector__XXX
 SG_ Hvsp24LwstCllTmprtrMdlNmr : 16|8@1+ (1,0) [0|250] "count" Vector__XXX
 SG_ Hvsp24LwstCllTmprtrCllNmr : 24|8@1+ (1,0) [0|250] "count" Vector__XXX
 SG_ Hvess24ThermalEventDetected : 32|2@1+ (1,0) [0|3] "" Vector__XXX
 SG_ Hvsp24Dt9EmdddIntgrtSpprt : 50|2@1+ (1,0) [0|3] "" Vector__XXX
 SG_ Hvesp24Data9Counter : 52|4@1+ (1,0) [0|15] "" Vector__XXX
 SG_ Hvesp24Data9Crc : 56|8@1+ (1,0) [0|250] "count" Vector__XXX

BO_ 2364744190 HVESP24D10: 8 Vector__XXX
 SG_ Hvsp24HghstCllSttOfChrgMdlNmr : 0|8@1+ (1,0) [0|250] "count" Vector__XXX
 SG_ Hvsp24HghstCllSttOfChrgCllNmr : 8|8@1+ (1,0) [0|250] "count" Vector__XXX
 SG_ Hvsp24LwstCllSttOfChrgMdlNmr : 16|8@1+ (1,0) [0|250] "count" Vector__XXX
 SG_ Hvsp24LwstCllSttOfChrgCllNmr : 24|8@1+ (1,0) [0|250] "count" Vector__XXX
 SG_ Hvsp24HghVltgBsAtvIsltnTstRslts : 32|16@1+ (0.1,0) [0|6425.5] "OhmPerV" Vector__XXX
 SG_ Hvsp24HVtBsPssvIstTstRsts : 48|16@1+ (0.1,0) [0|6425.5] "OhmPerV" Vector__XXX

BO_ 2364744446 HVESP24D11: 8 Vector__XXX
 SG_ Hvsp24BsVltgNgtvTChsssGrndVltg : 0|16@1+ (0.05,0) [0|3212.75] "V" Vector__XXX
 SG_ Hvsp24VltgLvlNgtvTChsssGrndVltg : 16|16@1+ (0.05,0) [0|3212.75] "V" Vector__XXX
 SG_ Hvesp24ActualChargeRate : 32|16@1+ (0.05,0) [0|3212.75] "kW" Vector__XXX

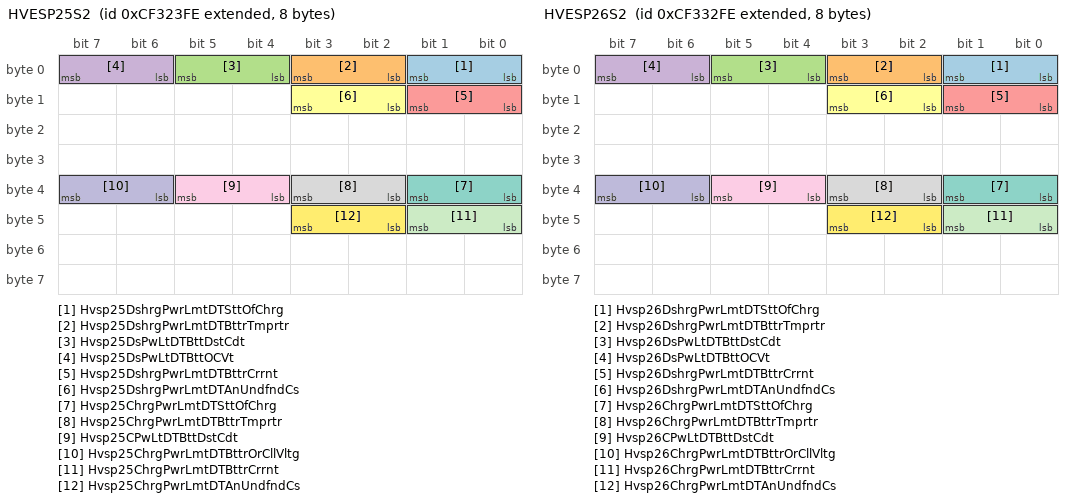
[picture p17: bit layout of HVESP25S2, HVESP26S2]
BO_ 2364744702 HVESP25S2: 8 Vector__XXX
 SG_ Hvsp25DshrgPwrLmtDTSttOfChrg : 0|2@1+ (1,0) [0|3] "" Vector__XXX
 SG_ Hvsp25DshrgPwrLmtDTBttrTmprtr : 2|2@1+ (1,0) [0|3] "" Vector__XXX
 SG_ Hvsp25DsPwLtDTBttDstCdt : 4|2@1+ (1,0) [0|3] "" Vector__XXX
 SG_ Hvsp25DsPwLtDTBttOCVt : 6|2@1+ (1,0) [0|3] "" Vector__XXX
 SG_ Hvsp25DshrgPwrLmtDTBttrCrrnt : 8|2@1+ (1,0) [0|3] "" Vector__XXX
 SG_ Hvsp25DshrgPwrLmtDTAnUndfndCs : 10|2@1+ (1,0) [0|3] "" Vector__XXX
 SG_ Hvsp25ChrgPwrLmtDTSttOfChrg : 32|2@1+ (1,0) [0|3] "" Vector__XXX
 SG_ Hvsp25ChrgPwrLmtDTBttrTmprtr : 34|2@1+ (1,0) [0|3] "" Vector__XXX
 SG_ Hvsp25CPwLtDTBttDstCdt : 36|2@1+ (1,0) [0|3] "" Vector__XXX
 SG_ Hvsp25ChrgPwrLmtDTBttrOrCllVltg : 38|2@1+ (1,0) [0|3] "" Vector__XXX
 SG_ Hvsp25ChrgPwrLmtDTBttrCrrnt : 40|2@1+ (1,0) [0|3] "" Vector__XXX
 SG_ Hvsp25ChrgPwrLmtDTAnUndfndCs : 42|2@1+ (1,0) [0|3] "" Vector__XXX

BO_ 2364744958 HVESP25D1: 8 Vector__XXX
 SG_ Hvesp25AvailableDischargePower : 0|16@1+ (0.05,0) [0|3212.75] "kW" Vector__XXX
 SG_ Hvesp25AvailableChargePower : 16|16@1+ (0.05,0) [0|3212.75] "kW" Vector__XXX
 SG_ Hvesp25VoltageLevel : 32|16@1+ (0.05,0) [0|3212.75] "V" Vector__XXX
 SG_ Hvesp25Current : 48|16@1+ (0.05,-1600) [-1600|1612.75] "A" Vector__XXX

BO_ 2364745214 HVESP25D2: 8 Vector__XXX
 SG_ Hvesp25FastUpdateStateOfCharge : 0|16@1+ (0.0015625,0) [0|100.3984375] "%" Vector__XXX
 SG_ Hvesp25HighestCellVoltage : 16|16@1+ (0.001,0) [0|64.255] "V" Vector__XXX
 SG_ Hvesp25LowestCellVoltage : 32|16@1+ (0.001,0) [0|64.255] "V" Vector__XXX
 SG_ Hvsp25CllVltgDffrntlStts : 48|4@1+ (1,0) [0|15] "" Vector__XXX

BO_ 2364745470 HVESP25D3: 8 Vector__XXX
 SG_ Hvesp25HighestCellTemperature : 0|16@1+ (0.03125,-273) [-273|1734.96875] "degC" Vector__XXX
 SG_ Hvesp25LowestCellTemperature : 16|16@1+ (0.03125,-273) [-273|1734.96875] "degC" Vector__XXX
 SG_ Hvesp25AverageCellTemperature : 32|16@1+ (0.03125,-273) [-273|1734.96875] "degC" Vector__XXX
 SG_ Hvsp25CllTmprtrDffrntlStts : 48|2@1+ (1,0) [0|3] "" Vector__XXX

BO_ 2364745726 HVESP25D4: 8 Vector__XXX
 SG_ Hvesp25DischargeCapacity : 0|16@1+ (0.01,0) [0|642.55] "Ah" Vector__XXX
 SG_ Hvesp25ChargeCapacity : 16|16@1+ (0.01,0) [0|642.55] "Ah" Vector__XXX
 SG_ Hvesp25CellBalancingCount : 32|16@1+ (1,0) [0|64255] "count" Vector__XXX

BO_ 2364745982 HVESP25D5: 8 Vector__XXX
 SG_ Hvesp25LowestCellStateOfCharge : 32|16@1+ (0.0015625,0) [0|100.3984375] "%" Vector__XXX
 SG_ Hvesp25HighestCellStateOfCharge : 48|16@1+ (0.0015625,0) [0|100.3984375] "%" Vector__XXX
 SG_ Hvsp25MxmmInstntnsDshrgCrrntLmt : 0|16@1+ (0.05,-1600) [-1600|0] "A" Vector__XXX
 SG_ Hvsp25MxmmInstntnsChrgCrrntLmt : 16|16@1+ (0.05,-1600) [0|1612.75] "A" Vector__XXX

BO_ 2364746238 HVESP25D6: 8 Vector__XXX
 SG_ Hvesp25BusVoltage : 0|16@1+ (0.05,0) [0|3212.75] "V" Vector__XXX
 SG_ Hvesp25IgnitionVoltage : 16|16@1+ (0.01,0) [0|642.55] "V" Vector__XXX
 SG_ Hvesp25IntakeCoolantTemperature : 32|8@1+ (1,-40) [-40|210] "degC" Vector__XXX
 SG_ Hvesp25OutletCoolantTemperature : 40|8@1+ (1,-40) [-40|210] "degC" Vector__XXX
 SG_ Hvesp25ElectronicsTemperature : 48|8@1+ (1,-40) [-40|210] "degC" Vector__XXX
 SG_ Hvesp25Temperature : 56|8@1+ (1,-40) [-40|210] "degC" Vector__XXX

BO_ 2364746494 HVESP25S1: 8 Vector__XXX
 SG_ Hvsp25HghVltgBsPstvCnttrStt : 0|2@1+ (1,0) [0|3] "" Vector__XXX
 SG_ Hvsp25HghVltgBsNgtvCnttrStt : 2|2@1+ (1,0) [0|3] "" Vector__XXX
 SG_ Hvsp25HghVltgBsDsnntFrwrnng : 4|4@1+ (1,0) [0|15] "" Vector__XXX
 SG_ Hvsp25HghVltgBsPrChrgRlStt : 8|2@1+ (1,0) [0|3] "" Vector__XXX
 SG_ Hvsp25CntrOfPkCnttrStt : 10|2@1+ (1,0) [0|3] "" Vector__XXX
 SG_ Hvsp25HghVltgBsAtvIsltnTstStts : 12|4@1+ (1,0) [0|15] "" Vector__XXX
 SG_ Hvsp25HghVltgBsPssvIsltnTstStts : 16|4@1+ (1,0) [0|15] "" Vector__XXX
 SG_ Hvesp25HvilStatus : 20|2@1+ (1,0) [0|3] "" Vector__XXX
 SG_ Hvesp25InertiaSwitchStatus : 22|2@1+ (1,0) [0|3] "" Vector__XXX
 SG_ Hvesp25StateOfChargeStatus : 24|4@1+ (1,0) [0|15] "" Vector__XXX
 SG_ Hvesp25CellBalanceStatus : 28|2@1+ (1,0) [0|3] "" Vector__XXX
 SG_ Hvesp25CellBalancingActive : 30|2@1+ (1,0) [0|3] "" Vector__XXX
 SG_ Hvesp25InternalChargerStatus : 32|2@1+ (1,0) [0|3] "" Vector__XXX
 SG_ Hvsp25HghVltgBsCnntnStts : 40|4@1+ (1,0) [0|15] "" Vector__XXX
 SG_ Hvesp25OperationalStatus : 44|4@1+ (1,0) [0|15] "" Vector__XXX
 SG_ Hvesp25Status1Counter : 52|4@1+ (1,0) [0|15] "" Vector__XXX
 SG_ Hvesp25Status1Crc : 56|8@1+ (1,0) [0|250] "count" Vector__XXX

BO_ 2364746750 HVESP25D7: 8 Vector__XXX
 SG_ Hvesp25DischargeEnergyCapacity : 0|24@1+ (0.001,0) [0|16449.535] "kWh" Vector__XXX
 SG_ Hvesp25ChargeEnergyCapacity : 24|24@1+ (0.001,0) [0|16449.535] "kWh" Vector__XXX
 SG_ Hvsp25MxmmChrgVltgLmt : 48|16@1+ (0.05,0) [0|3212.75] "V" Vector__XXX

BO_ 2364747006 HVESP25MS1: 8 Vector__XXX
 SG_ Hvesp25Module1OperationalStatus : 0|2@1+ (1,0) [0|3] "" Vector__XXX
 SG_ Hvesp25Module2OperationalStatus : 2|2@1+ (1,0) [0|3] "" Vector__XXX
 SG_ Hvesp25Module3OperationalStatus : 4|2@1+ (1,0) [0|3] "" Vector__XXX
 SG_ Hvesp25Module4OperationalStatus : 6|2@1+ (1,0) [0|3] "" Vector__XXX
 SG_ Hvesp25Module5OperationalStatus : 8|2@1+ (1,0) [0|3] "" Vector__XXX
 SG_ Hvesp25Module6OperationalStatus : 10|2@1+ (1,0) [0|3] "" Vector__XXX
 SG_ Hvesp25Module7OperationalStatus : 12|2@1+ (1,0) [0|3] "" Vector__XXX
 SG_ Hvesp25Module8OperationalStatus : 14|2@1+ (1,0) [0|3] "" Vector__XXX
 SG_ Hvesp25Module9OperationalStatus : 16|2@1+ (1,0) [0|3] "" Vector__XXX
 SG_ Hvsp25Mdl10OprtnlStts : 18|2@1+ (1,0) [0|3] "" Vector__XXX
 SG_ Hvsp25Mdl11OprtnlStts : 20|2@1+ (1,0) [0|3] "" Vector__XXX
 SG_ Hvsp25Mdl12OprtnlStts : 22|2@1+ (1,0) [0|3] "" Vector__XXX
 SG_ Hvsp25Mdl13OprtnlStts : 24|2@1+ (1,0) [0|3] "" Vector__XXX
 SG_ Hvsp25Mdl14OprtnlStts : 26|2@1+ (1,0) [0|3] "" Vector__XXX
 SG_ Hvsp25Mdl15OprtnlStts : 28|2@1+ (1,0) [0|3] "" Vector__XXX
 SG_ Hvsp25Mdl16OprtnlStts : 30|2@1+ (1,0) [0|3] "" Vector__XXX
 SG_ Hvsp25Mdl17OprtnlStts : 32|2@1+ (1,0) [0|3] "" Vector__XXX
 SG_ Hvsp25Mdl18OprtnlStts : 34|2@1+ (1,0) [0|3] "" Vector__XXX
 SG_ Hvsp25Mdl19OprtnlStts : 36|2@1+ (1,0) [0|3] "" Vector__XXX
 SG_ Hvsp25Mdl20OprtnlStts : 38|2@1+ (1,0) [0|3] "" Vector__XXX
 SG_ Hvsp25Mdl21OprtnlStts : 40|2@1+ (1,0) [0|3] "" Vector__XXX
 SG_ Hvsp25Mdl22OprtnlStts : 42|2@1+ (1,0) [0|3] "" Vector__XXX
 SG_ Hvsp25Mdl23OprtnlStts : 44|2@1+ (1,0) [0|3] "" Vector__XXX
 SG_ Hvsp25Mdl24OprtnlStts : 46|2@1+ (1,0) [0|3] "" Vector__XXX
 SG_ Hvsp25Mdl25OprtnlStts : 48|2@1+ (1,0) [0|3] "" Vector__XXX
 SG_ Hvsp25Mdl26OprtnlStts : 50|2@1+ (1,0) [0|3] "" Vector__XXX
 SG_ Hvsp25Mdl27OprtnlStts : 52|2@1+ (1,0) [0|3] "" Vector__XXX
 SG_ Hvsp25Mdl28OprtnlStts : 54|2@1+ (1,0) [0|3] "" Vector__XXX
 SG_ Hvsp25Mdl29OprtnlStts : 56|2@1+ (1,0) [0|3] "" Vector__XXX
 SG_ Hvsp25Mdl30OprtnlStts : 58|2@1+ (1,0) [0|3] "" Vector__XXX
 SG_ Hvsp25Mdl31OprtnlStts : 60|2@1+ (1,0) [0|3] "" Vector__XXX
 SG_ Hvsp25Mdl32OprtnlStts : 62|2@1+ (1,0) [0|3] "" Vector__XXX

BO_ 2364747262 HVESP25TS1: 8 Vector__XXX
 SG_ Hvsp25ThrmlMngmntSstmSlInptPwr : 0|16@1+ (0.5,0) [0|32127.5] "W" Vector__XXX
 SG_ Hvsp25TMtSstHVtIptPw : 16|16@1+ (0.5,0) [0|32127.5] "W" Vector__XXX
 SG_ Hvsp25ThrmlMngmntSstmCmprssrSpd : 32|8@1+ (32,0) [0|8000] "rpm" Vector__XXX
 SG_ Hvsp25ThrmlMngmntSstmRltvHmdt : 40|8@1+ (0.4,0) [0|100] "%" Vector__XXX
 SG_ Hvsp25ThrmlMngmntSstmHtrStts : 48|2@1+ (1,0) [0|3] "" Vector__XXX
 SG_ Hvsp25ThrmlMngmntSstmHvlStts : 50|2@1+ (1,0) [0|3] "" Vector__XXX
 SG_ Hvsp25ThrmlMngmntSstmMd : 52|4@1+ (1,0) [0|15] "" Vector__XXX
 SG_ Hvsp25ThrmlMngmntSstmClntLvl : 56|2@1+ (1,0) [0|3] "" Vector__XXX

BO_ 2364747518 HVESP25D8: 8 Vector__XXX
 SG_ Hvsp25HghstCllVltgMdlNmr : 0|8@1+ (1,0) [0|250] "count" Vector__XXX
 SG_ Hvsp25HghstCllVltgCllNmr : 8|8@1+ (1,0) [0|250] "count" Vector__XXX
 SG_ Hvsp25LwstCllVltgMdlNmr : 16|8@1+ (1,0) [0|250] "count" Vector__XXX
 SG_ Hvsp25LwstCllVltgCllNmr : 24|8@1+ (1,0) [0|250] "count" Vector__XXX
 SG_ Hvesp25AverageCellVoltage : 32|16@1+ (0.001,0) [0|64.255] "V" Vector__XXX

BO_ 2364747774 HVESP25D9: 8 Vector__XXX
 SG_ Hvsp25HghstCllTmprtrMdlNmr : 0|8@1+ (1,0) [0|250] "count" Vector__XXX
 SG_ Hvsp25HghstCllTmprtrCllNmr : 8|8@1+ (1,0) [0|250] "count" Vector__XXX
 SG_ Hvsp25LwstCllTmprtrMdlNmr : 16|8@1+ (1,0) [0|250] "count" Vector__XXX
 SG_ Hvsp25LwstCllTmprtrCllNmr : 24|8@1+ (1,0) [0|250] "count" Vector__XXX
 SG_ Hvess25ThermalEventDetected : 32|2@1+ (1,0) [0|3] "" Vector__XXX
 SG_ Hvsp25Dt9EmdddIntgrtSpprt : 50|2@1+ (1,0) [0|3] "" Vector__XXX
 SG_ Hvesp25Data9Counter : 52|4@1+ (1,0) [0|15] "" Vector__XXX
 SG_ Hvesp25Data9Crc : 56|8@1+ (1,0) [0|250] "count" Vector__XXX

BO_ 2364748030 HVESP25D10: 8 Vector__XXX
 SG_ Hvsp25HghstCllSttOfChrgMdlNmr : 0|8@1+ (1,0) [0|250] "count" Vector__XXX
 SG_ Hvsp25HghstCllSttOfChrgCllNmr : 8|8@1+ (1,0) [0|250] "count" Vector__XXX
 SG_ Hvsp25LwstCllSttOfChrgMdlNmr : 16|8@1+ (1,0) [0|250] "count" Vector__XXX
 SG_ Hvsp25LwstCllSttOfChrgCllNmr : 24|8@1+ (1,0) [0|250] "count" Vector__XXX
 SG_ Hvsp25HghVltgBsAtvIsltnTstRslts : 32|16@1+ (0.1,0) [0|6425.5] "OhmPerV" Vector__XXX
 SG_ Hvsp25HVtBsPssvIstTstRsts : 48|16@1+ (0.1,0) [0|6425.5] "OhmPerV" Vector__XXX

BO_ 2364748286 HVESP25D11: 8 Vector__XXX
 SG_ Hvsp25BsVltgNgtvTChsssGrndVltg : 0|16@1+ (0.05,0) [0|3212.75] "V" Vector__XXX
 SG_ Hvsp25VltgLvlNgtvTChsssGrndVltg : 16|16@1+ (0.05,0) [0|3212.75] "V" Vector__XXX
 SG_ Hvesp25ActualChargeRate : 32|16@1+ (0.05,0) [0|3212.75] "kW" Vector__XXX

BO_ 2364748542 HVESP26S2: 8 Vector__XXX
 SG_ Hvsp26DshrgPwrLmtDTSttOfChrg : 0|2@1+ (1,0) [0|3] "" Vector__XXX
 SG_ Hvsp26DshrgPwrLmtDTBttrTmprtr : 2|2@1+ (1,0) [0|3] "" Vector__XXX
 SG_ Hvsp26DsPwLtDTBttDstCdt : 4|2@1+ (1,0) [0|3] "" Vector__XXX
 SG_ Hvsp26DsPwLtDTBttOCVt : 6|2@1+ (1,0) [0|3] "" Vector__XXX
 SG_ Hvsp26DshrgPwrLmtDTBttrCrrnt : 8|2@1+ (1,0) [0|3] "" Vector__XXX
 SG_ Hvsp26DshrgPwrLmtDTAnUndfndCs : 10|2@1+ (1,0) [0|3] "" Vector__XXX
 SG_ Hvsp26ChrgPwrLmtDTSttOfChrg : 32|2@1+ (1,0) [0|3] "" Vector__XXX
 SG_ Hvsp26ChrgPwrLmtDTBttrTmprtr : 34|2@1+ (1,0) [0|3] "" Vector__XXX
 SG_ Hvsp26CPwLtDTBttDstCdt : 36|2@1+ (1,0) [0|3] "" Vector__XXX
 SG_ Hvsp26ChrgPwrLmtDTBttrOrCllVltg : 38|2@1+ (1,0) [0|3] "" Vector__XXX
 SG_ Hvsp26ChrgPwrLmtDTBttrCrrnt : 40|2@1+ (1,0) [0|3] "" Vector__XXX
 SG_ Hvsp26ChrgPwrLmtDTAnUndfndCs : 42|2@1+ (1,0) [0|3] "" Vector__XXX

BO_ 2364748798 HVESP26D1: 8 Vector__XXX
 SG_ Hvesp26AvailableDischargePower : 0|16@1+ (0.05,0) [0|3212.75] "kW" Vector__XXX
 SG_ Hvesp26AvailableChargePower : 16|16@1+ (0.05,0) [0|3212.75] "kW" Vector__XXX
 SG_ Hvesp26VoltageLevel : 32|16@1+ (0.05,0) [0|3212.75] "V" Vector__XXX
 SG_ Hvesp26Current : 48|16@1+ (0.05,-1600) [-1600|1612.75] "A" Vector__XXX

BO_ 2364749054 HVESP26D2: 8 Vector__XXX
 SG_ Hvesp26FastUpdateStateOfCharge : 0|16@1+ (0.0015625,0) [0|100.3984375] "%" Vector__XXX
 SG_ Hvesp26HighestCellVoltage : 16|16@1+ (0.001,0) [0|64.255] "V" Vector__XXX
 SG_ Hvesp26LowestCellVoltage : 32|16@1+ (0.001,0) [0|64.255] "V" Vector__XXX
 SG_ Hvsp26CllVltgDffrntlStts : 48|4@1+ (1,0) [0|15] "" Vector__XXX

BO_ 2364749310 HVESP26D3: 8 Vector__XXX
 SG_ Hvesp26HighestCellTemperature : 0|16@1+ (0.03125,-273) [-273|1734.96875] "degC" Vector__XXX
 SG_ Hvesp26LowestCellTemperature : 16|16@1+ (0.03125,-273) [-273|1734.96875] "degC" Vector__XXX
 SG_ Hvesp26AverageCellTemperature : 32|16@1+ (0.03125,-273) [-273|1734.96875] "degC" Vector__XXX
 SG_ Hvsp26CllTmprtrDffrntlStts : 48|2@1+ (1,0) [0|3] "" Vector__XXX

BO_ 2364749566 HVESP26D4: 8 Vector__XXX
 SG_ Hvesp26DischargeCapacity : 0|16@1+ (0.01,0) [0|642.55] "Ah" Vector__XXX
 SG_ Hvesp26ChargeCapacity : 16|16@1+ (0.01,0) [0|642.55] "Ah" Vector__XXX
 SG_ Hvesp26CellBalancingCount : 32|16@1+ (1,0) [0|64255] "count" Vector__XXX

BO_ 2364749822 HVESP26D5: 8 Vector__XXX
 SG_ Hvesp26LowestCellStateOfCharge : 32|16@1+ (0.0015625,0) [0|100.3984375] "%" Vector__XXX
 SG_ Hvesp26HighestCellStateOfCharge : 48|16@1+ (0.0015625,0) [0|100.3984375] "%" Vector__XXX
 SG_ Hvsp26MxmmInstntnsDshrgCrrntLmt : 0|16@1+ (0.05,-1600) [-1600|0] "A" Vector__XXX
 SG_ Hvsp26MxmmInstntnsChrgCrrntLmt : 16|16@1+ (0.05,-1600) [0|1612.75] "A" Vector__XXX

BO_ 2364750078 HVESP26D6: 8 Vector__XXX
 SG_ Hvesp26BusVoltage : 0|16@1+ (0.05,0) [0|3212.75] "V" Vector__XXX
 SG_ Hvesp26IgnitionVoltage : 16|16@1+ (0.01,0) [0|642.55] "V" Vector__XXX
 SG_ Hvesp26IntakeCoolantTemperature : 32|8@1+ (1,-40) [-40|210] "degC" Vector__XXX
 SG_ Hvesp26OutletCoolantTemperature : 40|8@1+ (1,-40) [-40|210] "degC" Vector__XXX
 SG_ Hvesp26ElectronicsTemperature : 48|8@1+ (1,-40) [-40|210] "degC" Vector__XXX
 SG_ Hvesp26Temperature : 56|8@1+ (1,-40) [-40|210] "degC" Vector__XXX

BO_ 2364750334 HVESP26S1: 8 Vector__XXX
 SG_ Hvsp26HghVltgBsPstvCnttrStt : 0|2@1+ (1,0) [0|3] "" Vector__XXX
 SG_ Hvsp26HghVltgBsNgtvCnttrStt : 2|2@1+ (1,0) [0|3] "" Vector__XXX
 SG_ Hvsp26HghVltgBsDsnntFrwrnng : 4|4@1+ (1,0) [0|15] "" Vector__XXX
 SG_ Hvsp26HghVltgBsPrChrgRlStt : 8|2@1+ (1,0) [0|3] "" Vector__XXX
 SG_ Hvsp26CntrOfPkCnttrStt : 10|2@1+ (1,0) [0|3] "" Vector__XXX
 SG_ Hvsp26HghVltgBsAtvIsltnTstStts : 12|4@1+ (1,0) [0|15] "" Vector__XXX
 SG_ Hvsp26HghVltgBsPssvIsltnTstStts : 16|4@1+ (1,0) [0|15] "" Vector__XXX
 SG_ Hvesp26HvilStatus : 20|2@1+ (1,0) [0|3] "" Vector__XXX
 SG_ Hvesp26InertiaSwitchStatus : 22|2@1+ (1,0) [0|3] "" Vector__XXX
 SG_ Hvesp26StateOfChargeStatus : 24|4@1+ (1,0) [0|15] "" Vector__XXX
 SG_ Hvesp26CellBalanceStatus : 28|2@1+ (1,0) [0|3] "" Vector__XXX
 SG_ Hvesp26CellBalancingActive : 30|2@1+ (1,0) [0|3] "" Vector__XXX
 SG_ Hvesp26InternalChargerStatus : 32|2@1+ (1,0) [0|3] "" Vector__XXX
 SG_ Hvsp26HghVltgBsCnntnStts : 40|4@1+ (1,0) [0|15] "" Vector__XXX
 SG_ Hvesp26OperationalStatus : 44|4@1+ (1,0) [0|15] "" Vector__XXX
 SG_ Hvesp26Status1Counter : 52|4@1+ (1,0) [0|15] "" Vector__XXX
 SG_ Hvesp26Status1Crc : 56|8@1+ (1,0) [0|250] "count" Vector__XXX

BO_ 2364750590 HVESP26D7: 8 Vector__XXX
 SG_ Hvesp26DischargeEnergyCapacity : 0|24@1+ (0.001,0) [0|16449.535] "kWh" Vector__XXX
 SG_ Hvesp26ChargeEnergyCapacity : 24|24@1+ (0.001,0) [0|16449.535] "kWh" Vector__XXX
 SG_ Hvsp26MxmmChrgVltgLmt : 48|16@1+ (0.05,0) [0|3212.75] "V" Vector__XXX

BO_ 2364750846 HVESP26MS1: 8 Vector__XXX
 SG_ Hvesp26Module1OperationalStatus : 0|2@1+ (1,0) [0|3] "" Vector__XXX
 SG_ Hvesp26Module2OperationalStatus : 2|2@1+ (1,0) [0|3] "" Vector__XXX
 SG_ Hvesp26Module3OperationalStatus : 4|2@1+ (1,0) [0|3] "" Vector__XXX
 SG_ Hvesp26Module4OperationalStatus : 6|2@1+ (1,0) [0|3] "" Vector__XXX
 SG_ Hvesp26Module5OperationalStatus : 8|2@1+ (1,0) [0|3] "" Vector__XXX
 SG_ Hvesp26Module6OperationalStatus : 10|2@1+ (1,0) [0|3] "" Vector__XXX
 SG_ Hvesp26Module7OperationalStatus : 12|2@1+ (1,0) [0|3] "" Vector__XXX
 SG_ Hvesp26Module8OperationalStatus : 14|2@1+ (1,0) [0|3] "" Vector__XXX
 SG_ Hvesp26Module9OperationalStatus : 16|2@1+ (1,0) [0|3] "" Vector__XXX
 SG_ Hvsp26Mdl10OprtnlStts : 18|2@1+ (1,0) [0|3] "" Vector__XXX
 SG_ Hvsp26Mdl11OprtnlStts : 20|2@1+ (1,0) [0|3] "" Vector__XXX
 SG_ Hvsp26Mdl12OprtnlStts : 22|2@1+ (1,0) [0|3] "" Vector__XXX
 SG_ Hvsp26Mdl13OprtnlStts : 24|2@1+ (1,0) [0|3] "" Vector__XXX
 SG_ Hvsp26Mdl14OprtnlStts : 26|2@1+ (1,0) [0|3] "" Vector__XXX
 SG_ Hvsp26Mdl15OprtnlStts : 28|2@1+ (1,0) [0|3] "" Vector__XXX
 SG_ Hvsp26Mdl16OprtnlStts : 30|2@1+ (1,0) [0|3] "" Vector__XXX
 SG_ Hvsp26Mdl17OprtnlStts : 32|2@1+ (1,0) [0|3] "" Vector__XXX
 SG_ Hvsp26Mdl18OprtnlStts : 34|2@1+ (1,0) [0|3] "" Vector__XXX
 SG_ Hvsp26Mdl19OprtnlStts : 36|2@1+ (1,0) [0|3] "" Vector__XXX
 SG_ Hvsp26Mdl20OprtnlStts : 38|2@1+ (1,0) [0|3] "" Vector__XXX
 SG_ Hvsp26Mdl21OprtnlStts : 40|2@1+ (1,0) [0|3] "" Vector__XXX
 SG_ Hvsp26Mdl22OprtnlStts : 42|2@1+ (1,0) [0|3] "" Vector__XXX
 SG_ Hvsp26Mdl23OprtnlStts : 44|2@1+ (1,0) [0|3] "" Vector__XXX
 SG_ Hvsp26Mdl24OprtnlStts : 46|2@1+ (1,0) [0|3] "" Vector__XXX
 SG_ Hvsp26Mdl25OprtnlStts : 48|2@1+ (1,0) [0|3] "" Vector__XXX
 SG_ Hvsp26Mdl26OprtnlStts : 50|2@1+ (1,0) [0|3] "" Vector__XXX
 SG_ Hvsp26Mdl27OprtnlStts : 52|2@1+ (1,0) [0|3] "" Vector__XXX
 SG_ Hvsp26Mdl28OprtnlStts : 54|2@1+ (1,0) [0|3] "" Vector__XXX
 SG_ Hvsp26Mdl29OprtnlStts : 56|2@1+ (1,0) [0|3] "" Vector__XXX
 SG_ Hvsp26Mdl30OprtnlStts : 58|2@1+ (1,0) [0|3] "" Vector__XXX
 SG_ Hvsp26Mdl31OprtnlStts : 60|2@1+ (1,0) [0|3] "" Vector__XXX
 SG_ Hvsp26Mdl32OprtnlStts : 62|2@1+ (1,0) [0|3] "" Vector__XXX

BO_ 2364751102 HVESP26TS1: 8 Vector__XXX
 SG_ Hvsp26ThrmlMngmntSstmSlInptPwr : 0|16@1+ (0.5,0) [0|32127.5] "W" Vector__XXX
 SG_ Hvsp26TMtSstHVtIptPw : 16|16@1+ (0.5,0) [0|32127.5] "W" Vector__XXX
 SG_ Hvsp26ThrmlMngmntSstmCmprssrSpd : 32|8@1+ (32,0) [0|8000] "rpm" Vector__XXX
 SG_ Hvsp26ThrmlMngmntSstmRltvHmdt : 40|8@1+ (0.4,0) [0|100] "%" Vector__XXX
 SG_ Hvsp26ThrmlMngmntSstmHtrStts : 48|2@1+ (1,0) [0|3] "" Vector__XXX
 SG_ Hvsp26ThrmlMngmntSstmHvlStts : 50|2@1+ (1,0) [0|3] "" Vector__XXX
 SG_ Hvsp26ThrmlMngmntSstmMd : 52|4@1+ (1,0) [0|15] "" Vector__XXX
 SG_ Hvsp26ThrmlMngmntSstmClntLvl : 56|2@1+ (1,0) [0|3] "" Vector__XXX

BO_ 2364751358 HVESP26D8: 8 Vector__XXX
 SG_ Hvsp26HghstCllVltgMdlNmr : 0|8@1+ (1,0) [0|250] "count" Vector__XXX
 SG_ Hvsp26HghstCllVltgCllNmr : 8|8@1+ (1,0) [0|250] "count" Vector__XXX
 SG_ Hvsp26LwstCllVltgMdlNmr : 16|8@1+ (1,0) [0|250] "count" Vector__XXX
 SG_ Hvsp26LwstCllVltgCllNmr : 24|8@1+ (1,0) [0|250] "count" Vector__XXX
 SG_ Hvesp26AverageCellVoltage : 32|16@1+ (0.001,0) [0|64.255] "V" Vector__XXX

BO_ 2364751614 HVESP26D9: 8 Vector__XXX
 SG_ Hvsp26HghstCllTmprtrMdlNmr : 0|8@1+ (1,0) [0|250] "count" Vector__XXX
 SG_ Hvsp26HghstCllTmprtrCllNmr : 8|8@1+ (1,0) [0|250] "count" Vector__XXX
 SG_ Hvsp26LwstCllTmprtrMdlNmr : 16|8@1+ (1,0) [0|250] "count" Vector__XXX
 SG_ Hvsp26LwstCllTmprtrCllNmr : 24|8@1+ (1,0) [0|250] "count" Vector__XXX
 SG_ Hvess26ThermalEventDetected : 32|2@1+ (1,0) [0|3] "" Vector__XXX
 SG_ Hvsp26Dt9EmdddIntgrtSpprt : 50|2@1+ (1,0) [0|3] "" Vector__XXX
 SG_ Hvesp26Data9Counter : 52|4@1+ (1,0) [0|15] "" Vector__XXX
 SG_ Hvesp26Data9Crc : 56|8@1+ (1,0) [0|250] "count" Vector__XXX

BO_ 2364751870 HVESP26D10: 8 Vector__XXX
 SG_ Hvsp26HghstCllSttOfChrgMdlNmr : 0|8@1+ (1,0) [0|250] "count" Vector__XXX
 SG_ Hvsp26HghstCllSttOfChrgCllNmr : 8|8@1+ (1,0) [0|250] "count" Vector__XXX
 SG_ Hvsp26LwstCllSttOfChrgMdlNmr : 16|8@1+ (1,0) [0|250] "count" Vector__XXX
 SG_ Hvsp26LwstCllSttOfChrgCllNmr : 24|8@1+ (1,0) [0|250] "count" Vector__XXX
 SG_ Hvsp26HghVltgBsAtvIsltnTstRslts : 32|16@1+ (0.1,0) [0|6425.5] "OhmPerV" Vector__XXX
 SG_ Hvsp26HVtBsPssvIstTstRsts : 48|16@1+ (0.1,0) [0|6425.5] "OhmPerV" Vector__XXX

BO_ 2364752126 HVESP26D11: 8 Vector__XXX
 SG_ Hvsp26BsVltgNgtvTChsssGrndVltg : 0|16@1+ (0.05,0) [0|3212.75] "V" Vector__XXX
 SG_ Hvsp26VltgLvlNgtvTChsssGrndVltg : 16|16@1+ (0.05,0) [0|3212.75] "V" Vector__XXX
 SG_ Hvesp26ActualChargeRate : 32|16@1+ (0.05,0) [0|3212.75] "kW" Vector__XXX

BO_ 2297643518 XSR: 8 Vector__XXX
 SG_ ExtrnlStrngRqstOprtngMd : 0|4@1+ (1,0) [0|15] "" Vector__XXX
 SG_ ExtrnlStrngWhlPstnRqst : 8|16@1+ (0.0625,-2008) [-2008|2007.9375] "deg" Vector__XXX
 SG_ ExtrnlStrngWhlTrqRqst : 24|16@1+ (0.0009765625,-31) [-31|31.7490234375] "Nm" Vector__XXX
 SG_ ExternalSteeringRequestPriority : 40|4@1+ (1,0) [0|15] "" Vector__XXX
 SG_ XsrMessageCounter : 56|4@1+ (1,0) [0|15] "count" Vector__XXX
 SG_ XsrMessageChecksum : 60|4@1+ (1,0) [0|15] "count" Vector__XXX

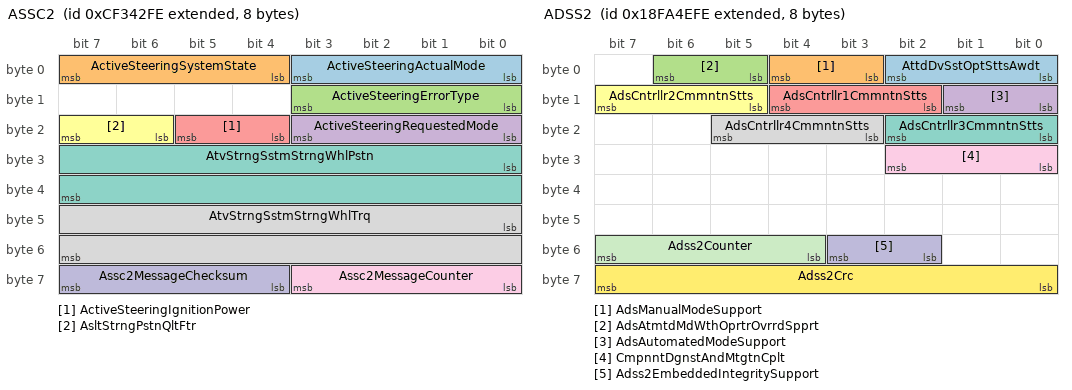
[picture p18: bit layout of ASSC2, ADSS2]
BO_ 2364752638 ASSC2: 8 Vector__XXX
 SG_ ActiveSteeringActualMode : 0|4@1+ (1,0) [0|15] "" Vector__XXX
 SG_ ActiveSteeringSystemState : 4|4@1+ (1,0) [0|15] "" Vector__XXX
 SG_ ActiveSteeringErrorType : 8|4@1+ (1,0) [0|15] "" Vector__XXX
 SG_ ActiveSteeringRequestedMode : 16|4@1+ (1,0) [0|15] "" Vector__XXX
 SG_ ActiveSteeringIgnitionPower : 20|2@1+ (1,0) [0|3] "" Vector__XXX
 SG_ AsltStrngPstnQltFtr : 22|2@1+ (1,0) [0|3] "" Vector__XXX
 SG_ AtvStrngSstmStrngWhlPstn : 24|16@1+ (0.0625,-2008) [-2008|2007.9375] "deg" Vector__XXX
 SG_ AtvStrngSstmStrngWhlTrq : 40|16@1+ (0.0009765625,-31) [-31|31.7490234375] "Nm" Vector__XXX
 SG_ Assc2MessageCounter : 56|4@1+ (1,0) [0|15] "count" Vector__XXX
 SG_ Assc2MessageChecksum : 60|4@1+ (1,0) [0|15] "count" Vector__XXX

BO_ 2566540286 A2SCRDSI5: 8 Vector__XXX
 SG_ Atttt2DsExstFdDs2PssExtddR : 0|16@1+ (0.1,-100) [-100|6325.5] "kPa" Vector__XXX
 SG_ Atttt2DsExstFdDs3PssExtddR : 16|16@1+ (0.1,-100) [-100|6325.5] "kPa" Vector__XXX

BO_ 2566540542 A1SCRDSI5: 8 Vector__XXX
 SG_ Atttt1DsExstFdDs2PssExtddR : 0|16@1+ (0.1,-100) [-100|6325.5] "kPa" Vector__XXX
 SG_ Atttt1DsExstFdDs3PssExtddR : 16|16@1+ (0.1,-100) [-100|6325.5] "kPa" Vector__XXX

BO_ 2566540798 EVEI: 8 Vector__XXX
 SG_ TotalTripEnergyConsumed : 0|32@1+ (0.1,0) [0|421108121.5] "kWh" Vector__XXX
 SG_ TripDriveEnergyEconomy : 32|16@1+ (0.001953125,0) [0|125.498046875] "kWh/km" Vector__XXX

BO_ 2566541054 ADSS2: 8 Vector__XXX
 SG_ AttdDvSstOptSttsAwdt : 0|3@1+ (1,0) [0|7] "" Vector__XXX
 SG_ AdsManualModeSupport : 3|2@1+ (1,0) [0|3] "" Vector__XXX
 SG_ AdsAtmtdMdWthOprtrOvrrdSpprt : 5|2@1+ (1,0) [0|3] "" Vector__XXX
 SG_ AdsAutomatedModeSupport : 8|2@1+ (1,0) [0|3] "" Vector__XXX
 SG_ AdsCntrllr1CmmntnStts : 10|3@1+ (1,0) [0|7] "" Vector__XXX
 SG_ AdsCntrllr2CmmntnStts : 13|3@1+ (1,0) [0|7] "" Vector__XXX
 SG_ AdsCntrllr3CmmntnStts : 16|3@1+ (1,0) [0|7] "" Vector__XXX
 SG_ AdsCntrllr4CmmntnStts : 19|3@1+ (1,0) [0|7] "" Vector__XXX
 SG_ CmpnntDgnstAndMtgtnCplt : 24|3@1+ (1,0) [0|7] "" Vector__XXX
 SG_ Adss2EmbeddedIntegritySupport : 50|2@1+ (1,0) [0|3] "" Vector__XXX
 SG_ Adss2Counter : 52|4@1+ (1,0) [0|15] "" Vector__XXX
 SG_ Adss2Crc : 56|8@1+ (1,0) [0|250] "count" Vector__XXX

BO_ 2566541310 ADSC3: 8 Vector__XXX
 SG_ AtmtdDrvngSstmOprtnStts : 0|3@1+ (1,0) [0|7] "" Vector__XXX
 SG_ Adsc3Counter : 52|4@1+ (1,0) [0|15] "" Vector__XXX
 SG_ Adsc3Crc : 56|8@1+ (1,0) [0|250] "count" Vector__XXX
 SG_ Adsc3EmbeddedIntegritySupport : 50|2@1+ (1,0) [0|3] "" Vector__XXX

BO_ 2566541566 AV: 8 Vector__XXX
 SG_ EngnAftrlrClntTmprtr : 0|16@1+ (0.03125,-273) [-273|1734.96875] "degC" Vector__XXX
 SG_ EDsdAtCtItTptHRst : 16|16@1+ (0.03125,-273) [-273|1734.96875] "degC" Vector__XXX
 SG_ EAtCtDtPssSwtStts : 32|2@1+ (1,0) [0|3] "" Vector__XXX
 SG_ EngnAftrlrClntPmpCntrl : 34|2@1+ (1,0) [0|3] "" Vector__XXX
 SG_ EngnAftrlrClntDvrtrVlvPstn : 40|8@1+ (0.4,0) [0|100] "%" Vector__XXX

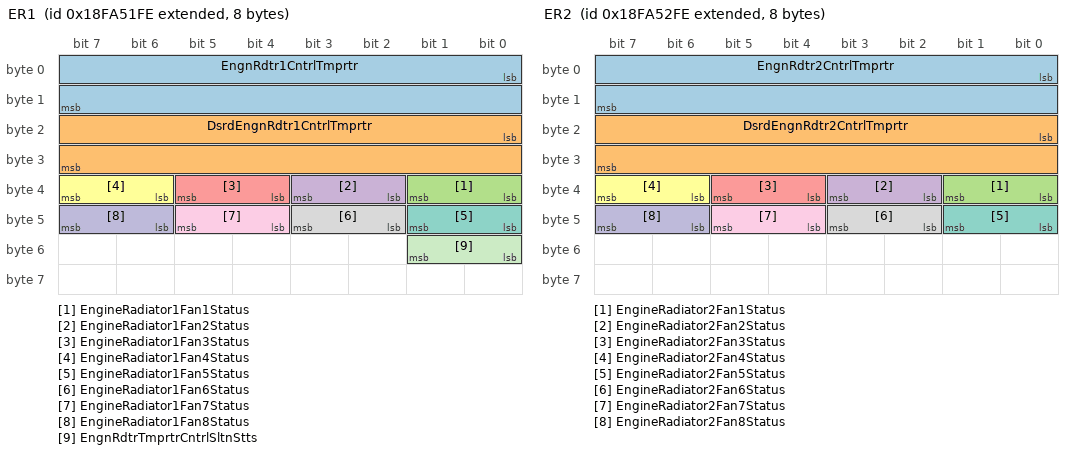
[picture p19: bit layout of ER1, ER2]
BO_ 2566541822 ER1: 8 Vector__XXX
 SG_ EngnRdtr1CntrlTmprtr : 0|16@1+ (0.03125,-273) [-273|1734.96875] "degC" Vector__XXX
 SG_ DsrdEngnRdtr1CntrlTmprtr : 16|16@1+ (0.03125,-273) [-273|1734.96875] "degC" Vector__XXX
 SG_ EngineRadiator1Fan1Status : 32|2@1+ (1,0) [0|3] "" Vector__XXX
 SG_ EngineRadiator1Fan2Status : 34|2@1+ (1,0) [0|3] "" Vector__XXX
 SG_ EngineRadiator1Fan3Status : 36|2@1+ (1,0) [0|3] "" Vector__XXX
 SG_ EngineRadiator1Fan4Status : 38|2@1+ (1,0) [0|3] "" Vector__XXX
 SG_ EngineRadiator1Fan5Status : 40|2@1+ (1,0) [0|3] "" Vector__XXX
 SG_ EngineRadiator1Fan6Status : 42|2@1+ (1,0) [0|3] "" Vector__XXX
 SG_ EngineRadiator1Fan7Status : 44|2@1+ (1,0) [0|3] "" Vector__XXX
 SG_ EngineRadiator1Fan8Status : 46|2@1+ (1,0) [0|3] "" Vector__XXX
 SG_ EngnRdtrTmprtrCntrlSltnStts : 48|2@1+ (1,0) [0|3] "" Vector__XXX

BO_ 2566542078 ER2: 8 Vector__XXX
 SG_ EngnRdtr2CntrlTmprtr : 0|16@1+ (0.03125,-273) [-273|1734.96875] "degC" Vector__XXX
 SG_ DsrdEngnRdtr2CntrlTmprtr : 16|16@1+ (0.03125,-273) [-273|1734.96875] "degC" Vector__XXX
 SG_ EngineRadiator2Fan1Status : 32|2@1+ (1,0) [0|3] "" Vector__XXX
 SG_ EngineRadiator2Fan2Status : 34|2@1+ (1,0) [0|3] "" Vector__XXX
 SG_ EngineRadiator2Fan3Status : 36|2@1+ (1,0) [0|3] "" Vector__XXX
 SG_ EngineRadiator2Fan4Status : 38|2@1+ (1,0) [0|3] "" Vector__XXX
 SG_ EngineRadiator2Fan5Status : 40|2@1+ (1,0) [0|3] "" Vector__XXX
 SG_ EngineRadiator2Fan6Status : 42|2@1+ (1,0) [0|3] "" Vector__XXX
 SG_ EngineRadiator2Fan7Status : 44|2@1+ (1,0) [0|3] "" Vector__XXX
 SG_ EngineRadiator2Fan8Status : 46|2@1+ (1,0) [0|3] "" Vector__XXX

BO_ 2566542334 GEV: 8 Vector__XXX
 SG_ GnstEnlsrIntkArTmprtr : 0|8@1+ (1,-40) [-40|210] "degC" Vector__XXX
 SG_ GnstEnlsrOtltArTmprtr : 8|8@1+ (1,-40) [-40|210] "degC" Vector__XXX
 SG_ GnstEnlsrFnRqstdPrntSpd : 16|8@1+ (0.4,0) [0|100] "%" Vector__XXX
 SG_ GensetEnclosureFanStatus : 24|2@1+ (1,0) [0|3] "" Vector__XXX

BO_ 2566542590 HE1: 8 Vector__XXX
 SG_ HtExhngr1PrmrIntkTmprtr : 0|16@1+ (0.03125,-273) [-273|1734.96875] "degC" Vector__XXX
 SG_ HtExhngr1PrmrOtltTmprtr : 16|16@1+ (0.03125,-273) [-273|1734.96875] "degC" Vector__XXX
 SG_ HtExhngr1SndrIntkTmprtr : 32|16@1+ (0.03125,-273) [-273|1734.96875] "degC" Vector__XXX
 SG_ HtExhngr1SndrOtltTmprtr : 48|16@1+ (0.03125,-273) [-273|1734.96875] "degC" Vector__XXX

BO_ 2566542846 HE2: 8 Vector__XXX
 SG_ HtExhngr2PrmrIntkTmprtr : 0|16@1+ (0.03125,-273) [-273|1734.96875] "degC" Vector__XXX
 SG_ HtExhngr2PrmrOtltTmprtr : 16|16@1+ (0.03125,-273) [-273|1734.96875] "degC" Vector__XXX
 SG_ HtExhngr2SndrIntkTmprtr : 32|16@1+ (0.03125,-273) [-273|1734.96875] "degC" Vector__XXX
 SG_ HtExhngr2SndrOtltTmprtr : 48|16@1+ (0.03125,-273) [-273|1734.96875] "degC" Vector__XXX

BO_ 2566543102 HE3: 8 Vector__XXX
 SG_ HtExhngr3PrmrIntkTmprtr : 0|16@1+ (0.03125,-273) [-273|1734.96875] "degC" Vector__XXX
 SG_ HtExhngr3PrmrOtltTmprtr : 16|16@1+ (0.03125,-273) [-273|1734.96875] "degC" Vector__XXX
 SG_ HtExhngr3SndrIntkTmprtr : 32|16@1+ (0.03125,-273) [-273|1734.96875] "degC" Vector__XXX
 SG_ HtExhngr3SndrOtltTmprtr : 48|16@1+ (0.03125,-273) [-273|1734.96875] "degC" Vector__XXX

BO_ 2566543358 HE4: 8 Vector__XXX
 SG_ HtExhngr4PrmrIntkTmprtr : 0|16@1+ (0.03125,-273) [-273|1734.96875] "degC" Vector__XXX
 SG_ HtExhngr4PrmrOtltTmprtr : 16|16@1+ (0.03125,-273) [-273|1734.96875] "degC" Vector__XXX
 SG_ HtExhngr4SndrIntkTmprtr : 32|16@1+ (0.03125,-273) [-273|1734.96875] "degC" Vector__XXX
 SG_ HtExhngr4SndrOtltTmprtr : 48|16@1+ (0.03125,-273) [-273|1734.96875] "degC" Vector__XXX

BO_ 2566543614 EEGHE: 8 Vector__XXX
 SG_ EngnExhstHtExhngrOtltTmprtr : 0|16@1+ (0.03125,-273) [-273|1734.96875] "degC" Vector__XXX
 SG_ EExstHtExBpssAtt1DsdPst : 16|8@1+ (0.4,0) [0|100] "%" Vector__XXX
 SG_ EngnExhstHtExhngrBpssAttr1Pstn : 24|8@1+ (0.4,0) [0|100] "%" Vector__XXX

BO_ 2566543870 GEVL: 8 Vector__XXX
 SG_ GnstEnlsrVntltnLvrAttr1DsrdPstn : 0|8@1+ (0.4,0) [0|100] "%" Vector__XXX
 SG_ GnstEnlsrVntltnLvrAttr1Pstn : 8|8@1+ (0.4,0) [0|100] "%" Vector__XXX
 SG_ GnstEnlsrVntltnLvrAttr2DsrdPstn : 16|8@1+ (0.4,0) [0|100] "%" Vector__XXX
 SG_ GnstEnlsrVntltnLvrAttr2Pstn : 24|8@1+ (0.4,0) [0|100] "%" Vector__XXX
 SG_ GstEsVttRtLvAttDsdPst : 32|8@1+ (0.4,0) [0|100] "%" Vector__XXX
 SG_ GnstEnlsrVntltnRrltnLvrAttrPstn : 40|8@1+ (0.4,0) [0|100] "%" Vector__XXX

BO_ 2566544126 GECS: 8 Vector__XXX
 SG_ DsrdHtngCrtThrmsttOpnng : 32|8@1+ (0.4,0) [0|100] "%" Vector__XXX
 SG_ HeatingCircuitThermostatOpening : 40|8@1+ (0.4,0) [0|100] "%" Vector__XXX
 SG_ HtngCrtDffrntlPrssrSwthStts : 48|2@1+ (1,0) [0|3] "" Vector__XXX
 SG_ HeatingCircuitPumpControl : 50|2@1+ (1,0) [0|3] "" Vector__XXX
 SG_ HtngCrtSpplOtltClntTmprtr : 0|16@1+ (0.03125,-273) [-273|1734.96875] "degC" Vector__XXX
 SG_ HtngCrtRtrnClntTmprtr : 16|16@1+ (0.03125,-273) [-273|1734.96875] "degC" Vector__XXX

BO_ 2566544382 EVDCS1: 8 Vector__XXX
 SG_ EvCabinConditioningFlag : 0|2@1+ (1,0) [0|3] "" Vector__XXX
 SG_ EvRessConditioningFlag : 2|2@1+ (1,0) [0|3] "" Vector__XXX
 SG_ EvErrorCode : 8|4@1+ (1,0) [0|15] "" Vector__XXX

BO_ 2566544638 EVSEDCLIM3: 8 Vector__XXX
 SG_ EvseEnergyToBeDelivered : 0|24@1+ (0.001,0) [0|16449.535] "kWh" Vector__XXX

BO_ 2566545406 EVDCLIM2: 8 Vector__XXX
 SG_ EvBulkStateOfCharge : 0|8@1+ (0.5,0) [0|125] "%" Vector__XXX
 SG_ EvFullStateOfCharge : 8|8@1+ (0.5,0) [0|125] "%" Vector__XXX
 SG_ EvEnergyCapacity : 16|16@1+ (1,0) [0|64255] "kWh" Vector__XXX
 SG_ EvEnergyRequested : 32|16@1+ (1,0) [0|64255] "kWh" Vector__XXX

BO_ 2566545662 EVDCCIP: 8 Vector__XXX
 SG_ EvBulkChargingComplete : 0|2@1+ (1,0) [0|3] "" Vector__XXX
 SG_ EvFullChargingComplete : 2|2@1+ (1,0) [0|3] "" Vector__XXX
 SG_ EvBulkChargeTimeRemaining : 8|16@1+ (10,0) [0|642550] "s" Vector__XXX
 SG_ EvFullChargeTimeRemaining : 24|16@1+ (10,0) [0|642550] "s" Vector__XXX
 SG_ EvDepartureTime : 40|16@1+ (10,0) [0|642550] "s" Vector__XXX

BO_ 2566546174 LD2: 8 Vector__XXX
 SG_ TractorHazardLights : 0|2@1+ (1,0) [0|3] "" Vector__XXX

BO_ 2365219838 LCMD2: 8 Vector__XXX
 SG_ LightingData2RequestCommand : 0|2@1+ (1,0) [0|3] "" Vector__XXX
 SG_ TractorHazardLightsCommand : 2|2@1+ (1,0) [0|3] "" Vector__XXX

BO_ 2566546686 ASI5: 8 Vector__XXX
 SG_ Aftrtrtmnt1SrIntkHghTmprtrCnt : 0|32@1+ (1,0) [0|4211081215] "count" Vector__XXX
 SG_ Aftrtrtmnt1TtlEvntCntWthNDfDlvr : 32|32@1+ (1,0) [0|4211081215] "count" Vector__XXX

BO_ 2566546942 ASI4: 8 Vector__XXX
 SG_ AftrtrtmntSrMlfntnCnt : 0|32@1+ (1,0) [0|4211081215] "count" Vector__XXX
 SG_ DieselExhaustFluidFrozenCount : 32|32@1+ (1,0) [0|4211081215] "count" Vector__XXX

BA_DEF_ BO_  "VFrameFormat" ENUM  "StandardCAN","ExtendedCAN","reserved","J1939PG";
BA_DEF_DEF_  "VFrameFormat" "J1939PG";
